VERSION "canboat-NMEA2000-curated"

NS_ :

BS_:

BU_: Vector__XXX
BO_ 2582577152 PGN_126720_0x1ef00ManufacturerProprietaryFastPacketAddressed: 223 Vector__XXX
 SG_ Industry_Code : 13|3@1+ (1.0,0) [0|7] "" Vector__XXX
 SG_ Data : 16|1768@1+ (1.0,0) [0|16635364987126134419907490844611231857889171561340108669757218330385068731224834608417815051548234195819468783937845710359164977421616154908223175941492902641772198991471137845920843845811776377869137773379678289214194183661112800944378464511794046030758602257005203964634516091405743061582849883160885255175229773660916874237270946647032424101972117051870087763059119895517977437771543686400460392041962138103436564399831189767740372774280024852942859855049773927338342604171805121253257539126169331943684033945189625789470637817855] "" Vector__XXX

BO_ 2582577152 PGN_126720_airmarAddressableMultiFrame: 8 Vector__XXX
 SG_ Industry_Code : 13|3@1+ (1.0,0) [0|7] "" Vector__XXX
 SG_ Proprietary_ID : 16|8@1+ (1.0,0) [0|255] "" Vector__XXX

BO_ 2582577152 PGN_126720_airmarAttitudeOffset: 9 Vector__XXX
 SG_ Industry_Code : 13|3@1+ (1.0,0) [0|7] "" Vector__XXX
 SG_ Proprietary_ID : 16|8@1+ (1.0,0) [0|255] "" Vector__XXX
 SG_ Azimuth_offset : 24|16@1- (0.0001,0) [-3.2768|3.2767] "" Vector__XXX
 SG_ Pitch_offset : 40|16@1- (0.0001,0) [-3.2768|3.2767] "" Vector__XXX
 SG_ Roll_offset : 56|16@1- (0.0001,0) [-3.2768|3.2767] "" Vector__XXX

BO_ 2582577152 PGN_126720_airmarCalibrateCompass: 24 Vector__XXX
 SG_ Industry_Code : 13|3@1+ (1.0,0) [0|7] "" Vector__XXX
 SG_ Proprietary_ID : 16|8@1+ (1.0,0) [0|255] "" Vector__XXX
 SG_ Calibrate_Function : 24|8@1+ (1.0,0) [0|255] "" Vector__XXX
 SG_ Calibration_Status : 32|8@1+ (1.0,0) [0|255] "" Vector__XXX
 SG_ Verify_Score : 40|8@1+ (1.0,0) [0|255] "" Vector__XXX
 SG_ X_axis_gain_value : 48|16@1- (0.01,0) [-327.68|327.67] "" Vector__XXX
 SG_ Y_axis_gain_value : 64|16@1- (0.01,0) [-327.68|327.67] "" Vector__XXX
 SG_ Z_axis_gain_value : 80|16@1- (0.01,0) [-327.68|327.67] "" Vector__XXX
 SG_ X_axis_linear_offset : 96|16@1- (0.01,0) [-327.68|327.67] "" Vector__XXX
 SG_ Y_axis_linear_offset : 112|16@1- (0.01,0) [-327.68|327.67] "" Vector__XXX
 SG_ Z_axis_linear_offset : 128|16@1- (0.01,0) [-327.68|327.67] "" Vector__XXX
 SG_ X_axis_angular_offset : 144|16@1- (0.1,0) [-3276.8|3276.7000000000003] "deg" Vector__XXX
 SG_ Pitch_and_Roll_damping : 160|16@1- (0.05,0) [-1638.4|1638.3500000000001] "" Vector__XXX
 SG_ Compass_Rate_gyro_damping : 176|16@1- (0.05,0) [-1638.4|1638.3500000000001] "" Vector__XXX

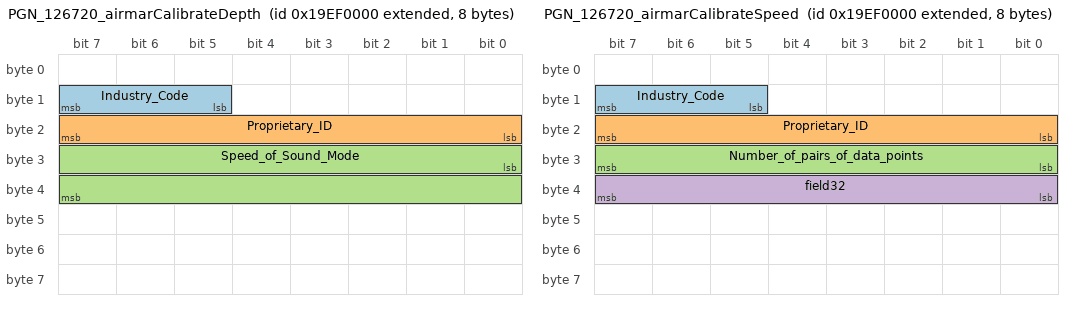
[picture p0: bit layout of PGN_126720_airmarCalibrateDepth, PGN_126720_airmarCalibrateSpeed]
BO_ 2582577152 PGN_126720_airmarCalibrateDepth: 8 Vector__XXX
 SG_ Industry_Code : 13|3@1+ (1.0,0) [0|7] "" Vector__XXX
 SG_ Proprietary_ID : 16|8@1+ (1.0,0) [0|255] "" Vector__XXX
 SG_ Speed_of_Sound_Mode : 24|16@1+ (0.1,0) [0.0|6553.5] "" Vector__XXX

BO_ 2582577152 PGN_126720_airmarCalibrateSpeed: 8 Vector__XXX
 SG_ Industry_Code : 13|3@1+ (1.0,0) [0|7] "" Vector__XXX
 SG_ Proprietary_ID : 16|8@1+ (1.0,0) [0|255] "" Vector__XXX
 SG_ Number_of_pairs_of_data_points : 24|8@1+ (1.0,0) [0|255] "" Vector__XXX
 SG_ field32 : 32|8@1+ (1.0,0) [0|255] "" Vector__XXX

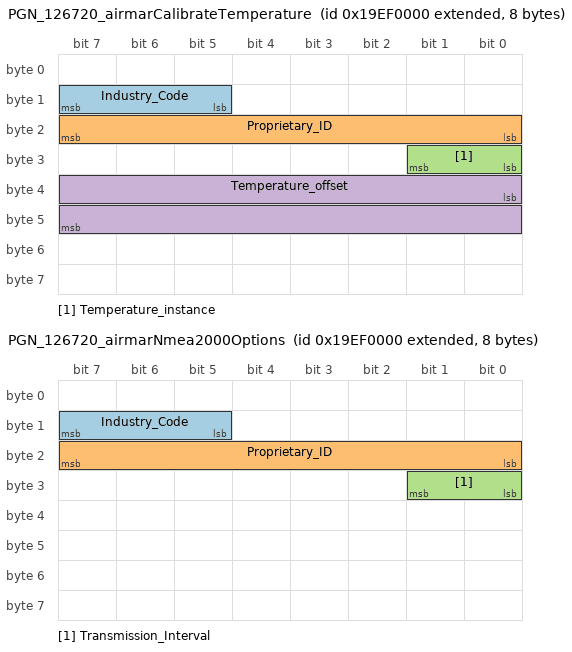
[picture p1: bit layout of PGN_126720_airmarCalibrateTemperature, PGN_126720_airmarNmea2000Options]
BO_ 2582577152 PGN_126720_airmarCalibrateTemperature: 8 Vector__XXX
 SG_ Industry_Code : 13|3@1+ (1.0,0) [0|7] "" Vector__XXX
 SG_ Proprietary_ID : 16|8@1+ (1.0,0) [0|255] "" Vector__XXX
 SG_ Temperature_instance : 24|2@1+ (1.0,0) [0|3] "" Vector__XXX
 SG_ Temperature_offset : 32|16@1- (0.001,0) [-9.999|9.999] "K" Vector__XXX

BO_ 2582577152 PGN_126720_airmarNmea2000Options: 8 Vector__XXX
 SG_ Industry_Code : 13|3@1+ (1.0,0) [0|7] "" Vector__XXX
 SG_ Proprietary_ID : 16|8@1+ (1.0,0) [0|255] "" Vector__XXX
 SG_ Transmission_Interval : 24|2@1+ (1.0,0) [0|3] "" Vector__XXX

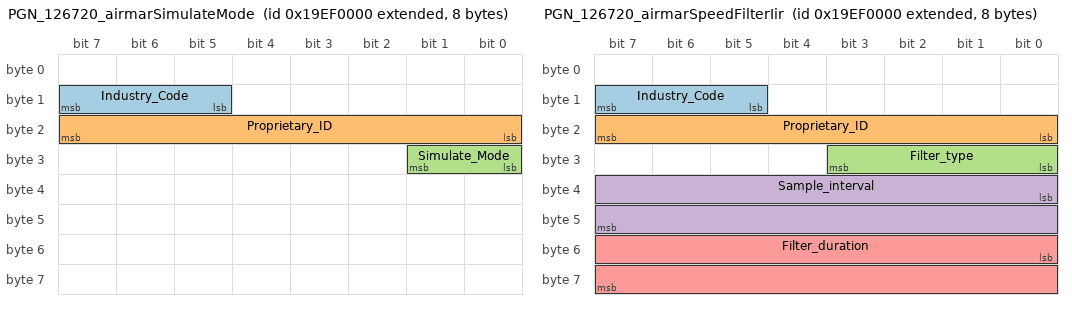
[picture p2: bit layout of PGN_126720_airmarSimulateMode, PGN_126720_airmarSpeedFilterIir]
BO_ 2582577152 PGN_126720_airmarSimulateMode: 8 Vector__XXX
 SG_ Industry_Code : 13|3@1+ (1.0,0) [0|7] "" Vector__XXX
 SG_ Proprietary_ID : 16|8@1+ (1.0,0) [0|255] "" Vector__XXX
 SG_ Simulate_Mode : 24|2@1+ (1.0,0) [0|3] "" Vector__XXX

BO_ 2582577152 PGN_126720_airmarSpeedFilterIir: 8 Vector__XXX
 SG_ Industry_Code : 13|3@1+ (1.0,0) [0|7] "" Vector__XXX
 SG_ Proprietary_ID : 16|8@1+ (1.0,0) [0|255] "" Vector__XXX
 SG_ Filter_type : 24|4@1+ (1.0,0) [0|15] "" Vector__XXX
 SG_ Sample_interval : 32|16@1+ (0.01,0) [0.0|655.35] "" Vector__XXX
 SG_ Filter_duration : 48|16@1+ (0.01,0) [0.0|655.35] "" Vector__XXX

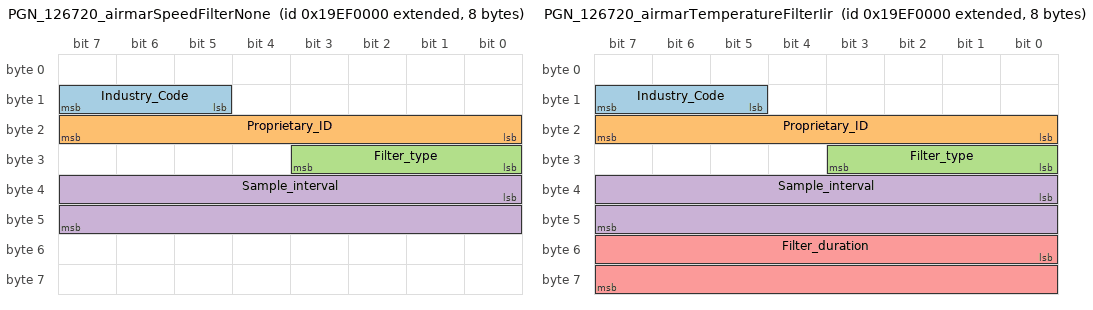
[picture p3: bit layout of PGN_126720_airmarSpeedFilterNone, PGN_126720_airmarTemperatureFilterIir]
BO_ 2582577152 PGN_126720_airmarSpeedFilterNone: 8 Vector__XXX
 SG_ Industry_Code : 13|3@1+ (1.0,0) [0|7] "" Vector__XXX
 SG_ Proprietary_ID : 16|8@1+ (1.0,0) [0|255] "" Vector__XXX
 SG_ Filter_type : 24|4@1+ (1.0,0) [0|15] "" Vector__XXX
 SG_ Sample_interval : 32|16@1+ (0.01,0) [0.0|655.35] "" Vector__XXX

BO_ 2582577152 PGN_126720_airmarTemperatureFilterIir: 8 Vector__XXX
 SG_ Industry_Code : 13|3@1+ (1.0,0) [0|7] "" Vector__XXX
 SG_ Proprietary_ID : 16|8@1+ (1.0,0) [0|255] "" Vector__XXX
 SG_ Filter_type : 24|4@1+ (1.0,0) [0|15] "" Vector__XXX
 SG_ Sample_interval : 32|16@1+ (0.01,0) [0.0|655.35] "" Vector__XXX
 SG_ Filter_duration : 48|16@1+ (0.01,0) [0.0|655.35] "" Vector__XXX

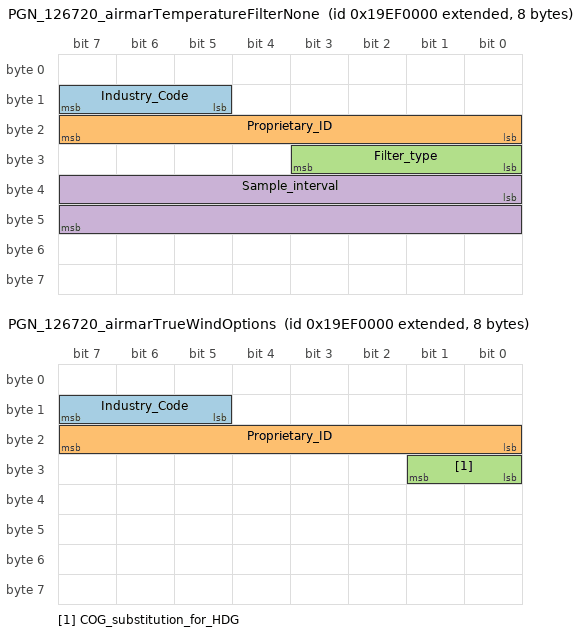
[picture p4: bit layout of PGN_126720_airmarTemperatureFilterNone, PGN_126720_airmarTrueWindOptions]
BO_ 2582577152 PGN_126720_airmarTemperatureFilterNone: 8 Vector__XXX
 SG_ Industry_Code : 13|3@1+ (1.0,0) [0|7] "" Vector__XXX
 SG_ Proprietary_ID : 16|8@1+ (1.0,0) [0|255] "" Vector__XXX
 SG_ Filter_type : 24|4@1+ (1.0,0) [0|15] "" Vector__XXX
 SG_ Sample_interval : 32|16@1+ (0.01,0) [0.0|655.35] "" Vector__XXX

BO_ 2582577152 PGN_126720_airmarTrueWindOptions: 8 Vector__XXX
 SG_ Industry_Code : 13|3@1+ (1.0,0) [0|7] "" Vector__XXX
 SG_ Proprietary_ID : 16|8@1+ (1.0,0) [0|255] "" Vector__XXX
 SG_ COG_substitution_for_HDG : 24|2@1+ (1.0,0) [0|3] "" Vector__XXX

BO_ 2582577152 PGN_126720_carlingDcConfigurationCommand: 13 Vector__XXX
 SG_ Industry_Code : 13|3@1+ (1.0,0) [0|7] "" Vector__XXX
 SG_ Message_Type : 16|8@1+ (1.0,0) [0|255] "" Vector__XXX
 SG_ Breaker_Mapping_1 : 24|8@1+ (1.0,0) [0|255] "" Vector__XXX
 SG_ Breaker_Mapping_2 : 32|8@1+ (1.0,0) [0|255] "" Vector__XXX
 SG_ Breaker_Mapping_3 : 45|3@1+ (1.0,0) [0|7] "" Vector__XXX
 SG_ Inrush_Delay : 48|4@1+ (1.0,0) [0|15] "" Vector__XXX
 SG_ Trip_Delay : 52|4@1+ (1.0,0) [0|15] "" Vector__XXX
 SG_ Configuration_Flags : 56|8@1+ (1.0,0) [0|255] "" Vector__XXX
 SG_ Current_Rating : 64|8@1+ (1.0,0) [0|255] "" Vector__XXX
 SG_ Factory_Max_Rating : 72|8@1+ (1.0,0) [0|255] "" Vector__XXX
 SG_ Schedule_B_Load_Shed_Priority : 80|4@1+ (1.0,0) [0|15] "" Vector__XXX
 SG_ Schedule_A_Load_Shed_Priority : 84|4@1+ (1.0,0) [0|15] "" Vector__XXX
 SG_ Dim_Value : 88|8@1+ (1.0,0) [0|255] "" Vector__XXX
 SG_ Breaker_Group : 96|4@1+ (1.0,0) [0|15] "" Vector__XXX
 SG_ Flash_Map_Index : 100|4@1+ (1.0,0) [0|15] "" Vector__XXX

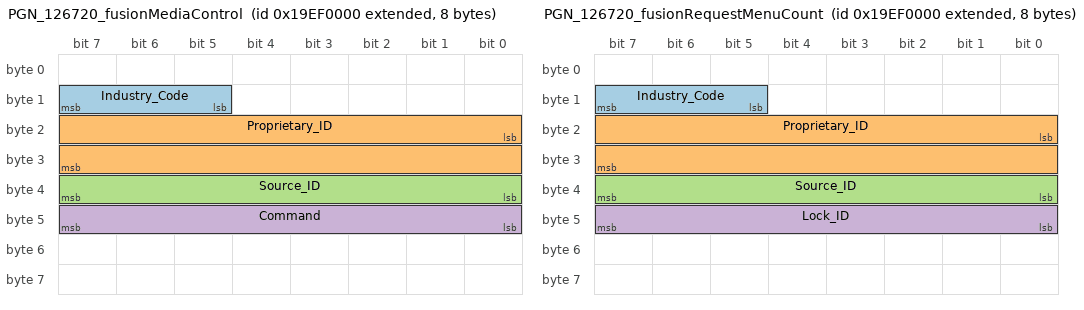
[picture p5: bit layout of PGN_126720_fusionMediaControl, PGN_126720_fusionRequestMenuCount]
BO_ 2582577152 PGN_126720_fusionMediaControl: 8 Vector__XXX
 SG_ Industry_Code : 13|3@1+ (1.0,0) [0|7] "" Vector__XXX
 SG_ Proprietary_ID : 16|16@1+ (1.0,0) [0|65535] "" Vector__XXX
 SG_ Source_ID : 32|8@1+ (1.0,0) [0|255] "" Vector__XXX
 SG_ Command : 40|8@1+ (1.0,0) [0|255] "" Vector__XXX

BO_ 2582577152 PGN_126720_fusionMenuActionCommand: 11 Vector__XXX
 SG_ Industry_Code : 13|3@1+ (1.0,0) [0|7] "" Vector__XXX
 SG_ Proprietary_ID : 16|16@1+ (1.0,0) [0|65535] "" Vector__XXX
 SG_ Source_ID : 32|8@1+ (1.0,0) [0|255] "" Vector__XXX
 SG_ Item_Index : 40|32@1+ (1.0,0) [0|4294967295] "" Vector__XXX
 SG_ Action : 72|8@1+ (1.0,0) [0|255] "" Vector__XXX
 SG_ Lock_ID : 80|8@1+ (1.0,0) [0|255] "" Vector__XXX

BO_ 2582577152 PGN_126720_fusionRequestMenuCount: 8 Vector__XXX
 SG_ Industry_Code : 13|3@1+ (1.0,0) [0|7] "" Vector__XXX
 SG_ Proprietary_ID : 16|16@1+ (1.0,0) [0|65535] "" Vector__XXX
 SG_ Source_ID : 32|8@1+ (1.0,0) [0|255] "" Vector__XXX
 SG_ Lock_ID : 40|8@1+ (1.0,0) [0|255] "" Vector__XXX

BO_ 2582577152 PGN_126720_fusionRequestMenuItems: 14 Vector__XXX
 SG_ Industry_Code : 13|3@1+ (1.0,0) [0|7] "" Vector__XXX
 SG_ Proprietary_ID : 16|16@1+ (1.0,0) [0|65535] "" Vector__XXX
 SG_ Source_ID : 32|8@1+ (1.0,0) [0|255] "" Vector__XXX
 SG_ Start_Index : 40|32@1+ (1.0,0) [0|4294967295] "" Vector__XXX
 SG_ Count : 72|32@1+ (1.0,0) [0|4294967295] "" Vector__XXX
 SG_ Lock_ID : 104|8@1+ (1.0,0) [0|255] "" Vector__XXX

BO_ 2582577152 PGN_126720_fusionRequestStatus: 8 Vector__XXX
 SG_ Industry_Code : 13|3@1+ (1.0,0) [0|7] "" Vector__XXX
 SG_ Proprietary_ID : 16|16@1+ (1.0,0) [0|65535] "" Vector__XXX

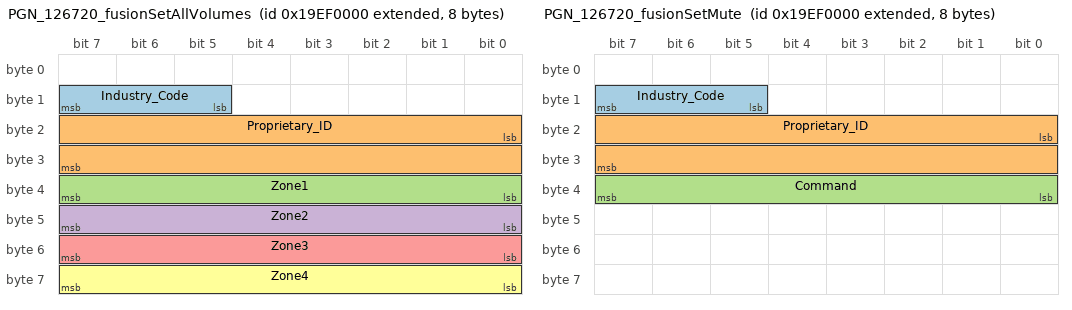
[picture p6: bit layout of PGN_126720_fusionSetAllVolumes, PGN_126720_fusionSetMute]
BO_ 2582577152 PGN_126720_fusionSetAllVolumes: 8 Vector__XXX
 SG_ Industry_Code : 13|3@1+ (1.0,0) [0|7] "" Vector__XXX
 SG_ Proprietary_ID : 16|16@1+ (1.0,0) [0|65535] "" Vector__XXX
 SG_ Zone1 : 32|8@1+ (1.0,0) [0|255] "" Vector__XXX
 SG_ Zone2 : 40|8@1+ (1.0,0) [0|255] "" Vector__XXX
 SG_ Zone3 : 48|8@1+ (1.0,0) [0|255] "" Vector__XXX
 SG_ Zone4 : 56|8@1+ (1.0,0) [0|255] "" Vector__XXX

BO_ 2582577152 PGN_126720_fusionSetMute: 8 Vector__XXX
 SG_ Industry_Code : 13|3@1+ (1.0,0) [0|7] "" Vector__XXX
 SG_ Proprietary_ID : 16|16@1+ (1.0,0) [0|65535] "" Vector__XXX
 SG_ Command : 32|8@1+ (1.0,0) [0|255] "" Vector__XXX

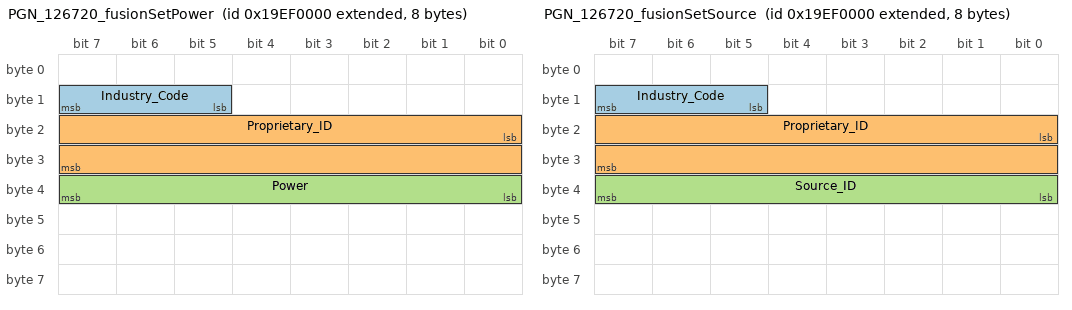
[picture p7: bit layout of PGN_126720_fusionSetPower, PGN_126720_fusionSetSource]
BO_ 2582577152 PGN_126720_fusionSetPower: 8 Vector__XXX
 SG_ Industry_Code : 13|3@1+ (1.0,0) [0|7] "" Vector__XXX
 SG_ Proprietary_ID : 16|16@1+ (1.0,0) [0|65535] "" Vector__XXX
 SG_ Power : 32|8@1+ (1.0,0) [0|255] "" Vector__XXX

BO_ 2582577152 PGN_126720_fusionSetSetting: 12 Vector__XXX
 SG_ Industry_Code : 13|3@1+ (1.0,0) [0|7] "" Vector__XXX
 SG_ Proprietary_ID : 16|16@1+ (1.0,0) [0|65535] "" Vector__XXX
 SG_ ID : 32|32@1+ (1.0,0) [0|4294967295] "" Vector__XXX
 SG_ Value : 64|32@1+ (1.0,0) [0|4294967295] "" Vector__XXX

BO_ 2582577152 PGN_126720_fusionSetSource: 8 Vector__XXX
 SG_ Industry_Code : 13|3@1+ (1.0,0) [0|7] "" Vector__XXX
 SG_ Proprietary_ID : 16|16@1+ (1.0,0) [0|65535] "" Vector__XXX
 SG_ Source_ID : 32|8@1+ (1.0,0) [0|255] "" Vector__XXX

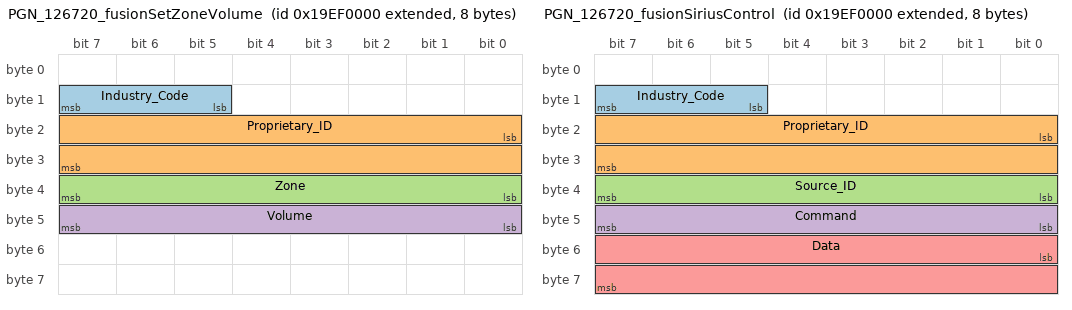
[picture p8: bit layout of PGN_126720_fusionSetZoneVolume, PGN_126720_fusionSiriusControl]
BO_ 2582577152 PGN_126720_fusionSetZoneVolume: 8 Vector__XXX
 SG_ Industry_Code : 13|3@1+ (1.0,0) [0|7] "" Vector__XXX
 SG_ Proprietary_ID : 16|16@1+ (1.0,0) [0|65535] "" Vector__XXX
 SG_ Zone : 32|8@1+ (1.0,0) [0|255] "" Vector__XXX
 SG_ Volume : 40|8@1+ (1.0,0) [0|255] "" Vector__XXX

BO_ 2582577152 PGN_126720_fusionSiriusControl: 8 Vector__XXX
 SG_ Industry_Code : 13|3@1+ (1.0,0) [0|7] "" Vector__XXX
 SG_ Proprietary_ID : 16|16@1+ (1.0,0) [0|65535] "" Vector__XXX
 SG_ Source_ID : 32|8@1+ (1.0,0) [0|255] "" Vector__XXX
 SG_ Command : 40|8@1+ (1.0,0) [0|255] "" Vector__XXX
 SG_ Data : 48|16@1+ (1.0,0) [0|65535] "" Vector__XXX

BO_ 2582577152 PGN_126720_garminAhrsAttCogSourceValidFlag: 12 Vector__XXX
 SG_ Industry_Code : 13|3@1+ (1.0,0) [0|7] "" Vector__XXX
 SG_ Sub_protocol_ID : 16|16@1+ (1.0,0) [0|65535] "" Vector__XXX
 SG_ Wrapper_Byte_1 : 32|8@1+ (1.0,0) [0|255] "" Vector__XXX
 SG_ Wrapper_Byte_2 : 40|8@1+ (1.0,0) [0|255] "" Vector__XXX
 SG_ ATT_Message_ID : 48|16@1+ (1.0,0) [0|65535] "" Vector__XXX
 SG_ COG_Source_Flags : 64|32@1+ (1.0,0) [0|4294967295] "" Vector__XXX

BO_ 2582577152 PGN_126720_garminAhrsAttDeviceFlags: 12 Vector__XXX
 SG_ Industry_Code : 13|3@1+ (1.0,0) [0|7] "" Vector__XXX
 SG_ Sub_protocol_ID : 16|16@1+ (1.0,0) [0|65535] "" Vector__XXX
 SG_ Wrapper_Byte_1 : 32|8@1+ (1.0,0) [0|255] "" Vector__XXX
 SG_ Wrapper_Byte_2 : 40|8@1+ (1.0,0) [0|255] "" Vector__XXX
 SG_ ATT_Message_ID : 48|16@1+ (1.0,0) [0|65535] "" Vector__XXX
 SG_ Device_Flags : 64|32@1+ (1.0,0) [0|4294967295] "" Vector__XXX

BO_ 2582577152 PGN_126720_garminAhrsAttNonDefaultCalibrationMatrixPresent: 9 Vector__XXX
 SG_ Industry_Code : 13|3@1+ (1.0,0) [0|7] "" Vector__XXX
 SG_ Sub_protocol_ID : 16|16@1+ (1.0,0) [0|65535] "" Vector__XXX
 SG_ Wrapper_Byte_1 : 32|8@1+ (1.0,0) [0|255] "" Vector__XXX
 SG_ Wrapper_Byte_2 : 40|8@1+ (1.0,0) [0|255] "" Vector__XXX
 SG_ ATT_Message_ID : 48|16@1+ (1.0,0) [0|65535] "" Vector__XXX
 SG_ Calibration_Matrix_Present : 64|8@1+ (1.0,0) [0|255] "" Vector__XXX

BO_ 2582577152 PGN_126720_garminAhrsAttSetNorthState: 9 Vector__XXX
 SG_ Industry_Code : 13|3@1+ (1.0,0) [0|7] "" Vector__XXX
 SG_ Sub_protocol_ID : 16|16@1+ (1.0,0) [0|65535] "" Vector__XXX
 SG_ Wrapper_Byte_1 : 32|8@1+ (1.0,0) [0|255] "" Vector__XXX
 SG_ Wrapper_Byte_2 : 40|8@1+ (1.0,0) [0|255] "" Vector__XXX
 SG_ ATT_Message_ID : 48|16@1+ (1.0,0) [0|65535] "" Vector__XXX
 SG_ Set_North_State : 64|8@1+ (1.0,0) [0|255] "" Vector__XXX

BO_ 2649686016 PGN_126720_garminAutopilotEngineRpmA: 11 Vector__XXX
 SG_ Manufacturer_Code : 0|11@1+ (1.0,0) [0|2047] "" Vector__XXX
 SG_ Industry_Code : 13|3@1+ (1.0,0) [0|7] "" Vector__XXX
 SG_ Sub_protocol_ID : 16|16@1+ (1.0,0) [0|65535] "" Vector__XXX
 SG_ Wrapper_Byte_1 : 32|8@1+ (1.0,0) [0|255] "" Vector__XXX
 SG_ Wrapper_Byte_2 : 40|8@1+ (1.0,0) [0|255] "" Vector__XXX
 SG_ Field_Group : 48|8@1+ (1.0,0) [0|255] "" Vector__XXX
 SG_ Field : 56|8@1+ (1.0,0) [0|255] "" Vector__XXX
 SG_ Engine_Speed : 72|16@1+ (1.0,0) [0|65535] "rpm" Vector__XXX

BO_ 2649686016 PGN_126720_garminAutopilotEngineRpmB: 11 Vector__XXX
 SG_ Manufacturer_Code : 0|11@1+ (1.0,0) [0|2047] "" Vector__XXX
 SG_ Industry_Code : 13|3@1+ (1.0,0) [0|7] "" Vector__XXX
 SG_ Sub_protocol_ID : 16|16@1+ (1.0,0) [0|65535] "" Vector__XXX
 SG_ Wrapper_Byte_1 : 32|8@1+ (1.0,0) [0|255] "" Vector__XXX
 SG_ Wrapper_Byte_2 : 40|8@1+ (1.0,0) [0|255] "" Vector__XXX
 SG_ Field_Group : 48|8@1+ (1.0,0) [0|255] "" Vector__XXX
 SG_ Field : 56|8@1+ (1.0,0) [0|255] "" Vector__XXX
 SG_ Engine_Speed : 72|16@1+ (1.0,0) [0|65535] "rpm" Vector__XXX

BO_ 2649686016 PGN_126720_garminAutopilotHeadingToSteer: 13 Vector__XXX
 SG_ Manufacturer_Code : 0|11@1+ (1.0,0) [0|2047] "" Vector__XXX
 SG_ Industry_Code : 13|3@1+ (1.0,0) [0|7] "" Vector__XXX
 SG_ Sub_protocol_ID : 16|16@1+ (1.0,0) [0|65535] "" Vector__XXX
 SG_ Wrapper_Byte_1 : 32|8@1+ (1.0,0) [0|255] "" Vector__XXX
 SG_ Wrapper_Byte_2 : 40|8@1+ (1.0,0) [0|255] "" Vector__XXX
 SG_ Field_Group : 48|8@1+ (1.0,0) [0|255] "" Vector__XXX
 SG_ Field : 56|8@1+ (1.0,0) [0|255] "" Vector__XXX
 SG_ Heading_to_Steer : 72|32@1- (1.0,0) [-2147483648|2147483647] "rad" Vector__XXX

BO_ 2649686016 PGN_126720_garminAutopilotHeartbeat: 12 Vector__XXX
 SG_ Manufacturer_Code : 0|11@1+ (1.0,0) [0|2047] "" Vector__XXX
 SG_ Industry_Code : 13|3@1+ (1.0,0) [0|7] "" Vector__XXX
 SG_ Sub_protocol_ID : 16|16@1+ (1.0,0) [0|65535] "" Vector__XXX
 SG_ Wrapper_Byte_1 : 32|8@1+ (1.0,0) [0|255] "" Vector__XXX
 SG_ Wrapper_Byte_2 : 40|8@1+ (1.0,0) [0|255] "" Vector__XXX
 SG_ Field_Group : 48|8@1+ (1.0,0) [0|255] "" Vector__XXX
 SG_ Field : 56|8@1+ (1.0,0) [0|255] "" Vector__XXX
 SG_ Heartbeat_Data : 64|32@1+ (1.0,0) [0|4294967295] "" Vector__XXX

BO_ 2649686016 PGN_126720_garminAutopilotManeuver: 10 Vector__XXX
 SG_ Manufacturer_Code : 0|11@1+ (1.0,0) [0|2047] "" Vector__XXX
 SG_ Industry_Code : 13|3@1+ (1.0,0) [0|7] "" Vector__XXX
 SG_ Sub_protocol_ID : 16|16@1+ (1.0,0) [0|65535] "" Vector__XXX
 SG_ Wrapper_Byte_1 : 32|8@1+ (1.0,0) [0|255] "" Vector__XXX
 SG_ Wrapper_Byte_2 : 40|8@1+ (1.0,0) [0|255] "" Vector__XXX
 SG_ Field_Group : 48|8@1+ (1.0,0) [0|255] "" Vector__XXX
 SG_ Maneuver_Code : 56|8@1+ (1.0,0) [0|255] "" Vector__XXX
 SG_ Spare : 64|8@1+ (1.0,0) [0|255] "" Vector__XXX
 SG_ Value : 72|8@1+ (1.0,0) [0|255] "" Vector__XXX

BO_ 2649686016 PGN_126720_garminAutopilotModeState: 11 Vector__XXX
 SG_ Manufacturer_Code : 0|11@1+ (1.0,0) [0|2047] "" Vector__XXX
 SG_ Industry_Code : 13|3@1+ (1.0,0) [0|7] "" Vector__XXX
 SG_ Sub_protocol_ID : 16|16@1+ (1.0,0) [0|65535] "" Vector__XXX
 SG_ Wrapper_Byte_1 : 32|8@1+ (1.0,0) [0|255] "" Vector__XXX
 SG_ Wrapper_Byte_2 : 40|8@1+ (1.0,0) [0|255] "" Vector__XXX
 SG_ Field_Group : 48|8@1+ (1.0,0) [0|255] "" Vector__XXX
 SG_ Field : 56|8@1+ (1.0,0) [0|255] "" Vector__XXX
 SG_ Spare : 64|8@1+ (1.0,0) [0|255] "" Vector__XXX
 SG_ Mode_State : 72|8@1+ (1.0,0) [0|255] "" Vector__XXX
 SG_ Spare_1 : 80|8@1+ (1.0,0) [0|255] "" Vector__XXX

BO_ 2649686016 PGN_126720_garminAutopilotRateOfTurn: 13 Vector__XXX
 SG_ Manufacturer_Code : 0|11@1+ (1.0,0) [0|2047] "" Vector__XXX
 SG_ Industry_Code : 13|3@1+ (1.0,0) [0|7] "" Vector__XXX
 SG_ Sub_protocol_ID : 16|16@1+ (1.0,0) [0|65535] "" Vector__XXX
 SG_ Wrapper_Byte_1 : 32|8@1+ (1.0,0) [0|255] "" Vector__XXX
 SG_ Wrapper_Byte_2 : 40|8@1+ (1.0,0) [0|255] "" Vector__XXX
 SG_ Field_Group : 48|8@1+ (1.0,0) [0|255] "" Vector__XXX
 SG_ Field : 56|8@1+ (1.0,0) [0|255] "" Vector__XXX
 SG_ Rate_of_Turn : 72|32@1- (1.0,0) [-3.40282346638529e+38|3.40282346638529e+38] "rad/s" Vector__XXX

BO_ 2649686016 PGN_126720_garminAutopilotRateOfTurnOrder: 13 Vector__XXX
 SG_ Manufacturer_Code : 0|11@1+ (1.0,0) [0|2047] "" Vector__XXX
 SG_ Industry_Code : 13|3@1+ (1.0,0) [0|7] "" Vector__XXX
 SG_ Sub_protocol_ID : 16|16@1+ (1.0,0) [0|65535] "" Vector__XXX
 SG_ Wrapper_Byte_1 : 32|8@1+ (1.0,0) [0|255] "" Vector__XXX
 SG_ Wrapper_Byte_2 : 40|8@1+ (1.0,0) [0|255] "" Vector__XXX
 SG_ Field_Group : 48|8@1+ (1.0,0) [0|255] "" Vector__XXX
 SG_ Field : 56|8@1+ (1.0,0) [0|255] "" Vector__XXX
 SG_ Rate_of_Turn_Order : 72|32@1- (1.0,0) [-3.40282346638529e+38|3.40282346638529e+38] "rad/s" Vector__XXX

BO_ 2649686016 PGN_126720_garminAutopilotResponseSetting: 10 Vector__XXX
 SG_ Manufacturer_Code : 0|11@1+ (1.0,0) [0|2047] "" Vector__XXX
 SG_ Industry_Code : 13|3@1+ (1.0,0) [0|7] "" Vector__XXX
 SG_ Sub_protocol_ID : 16|16@1+ (1.0,0) [0|65535] "" Vector__XXX
 SG_ Wrapper_Byte_1 : 32|8@1+ (1.0,0) [0|255] "" Vector__XXX
 SG_ Wrapper_Byte_2 : 40|8@1+ (1.0,0) [0|255] "" Vector__XXX
 SG_ Field_Group : 48|8@1+ (1.0,0) [0|255] "" Vector__XXX
 SG_ Field : 56|8@1+ (1.0,0) [0|255] "" Vector__XXX
 SG_ Response_Setting : 72|8@1- (1.0,0) [-128|127] "" Vector__XXX

BO_ 2649686016 PGN_126720_garminAutopilotSpeed: 13 Vector__XXX
 SG_ Manufacturer_Code : 0|11@1+ (1.0,0) [0|2047] "" Vector__XXX
 SG_ Industry_Code : 13|3@1+ (1.0,0) [0|7] "" Vector__XXX
 SG_ Sub_protocol_ID : 16|16@1+ (1.0,0) [0|65535] "" Vector__XXX
 SG_ Wrapper_Byte_1 : 32|8@1+ (1.0,0) [0|255] "" Vector__XXX
 SG_ Wrapper_Byte_2 : 40|8@1+ (1.0,0) [0|255] "" Vector__XXX
 SG_ Field_Group : 48|8@1+ (1.0,0) [0|255] "" Vector__XXX
 SG_ Field : 56|8@1+ (1.0,0) [0|255] "" Vector__XXX
 SG_ Speed : 72|32@1- (1.0,0) [-3.40282346638529e+38|3.40282346638529e+38] "m/s" Vector__XXX

BO_ 2649686016 PGN_126720_garminAutopilotSystemVoltage: 11 Vector__XXX
 SG_ Manufacturer_Code : 0|11@1+ (1.0,0) [0|2047] "" Vector__XXX
 SG_ Industry_Code : 13|3@1+ (1.0,0) [0|7] "" Vector__XXX
 SG_ Sub_protocol_ID : 16|16@1+ (1.0,0) [0|65535] "" Vector__XXX
 SG_ Wrapper_Byte_1 : 32|8@1+ (1.0,0) [0|255] "" Vector__XXX
 SG_ Wrapper_Byte_2 : 40|8@1+ (1.0,0) [0|255] "" Vector__XXX
 SG_ Field_Group : 48|8@1+ (1.0,0) [0|255] "" Vector__XXX
 SG_ Field : 56|8@1+ (1.0,0) [0|255] "" Vector__XXX
 SG_ System_Voltage : 72|16@1+ (0.01,0) [0.0|655.35] "" Vector__XXX

BO_ 2649686016 PGN_126720_garminAutopilotTurnAngleMeasured: 11 Vector__XXX
 SG_ Manufacturer_Code : 0|11@1+ (1.0,0) [0|2047] "" Vector__XXX
 SG_ Industry_Code : 13|3@1+ (1.0,0) [0|7] "" Vector__XXX
 SG_ Sub_protocol_ID : 16|16@1+ (1.0,0) [0|65535] "" Vector__XXX
 SG_ Wrapper_Byte_1 : 32|8@1+ (1.0,0) [0|255] "" Vector__XXX
 SG_ Wrapper_Byte_2 : 40|8@1+ (1.0,0) [0|255] "" Vector__XXX
 SG_ Field_Group : 48|8@1+ (1.0,0) [0|255] "" Vector__XXX
 SG_ Field : 56|8@1+ (1.0,0) [0|255] "" Vector__XXX
 SG_ Turn_Angle_Measured : 72|16@1+ (9.587379924285257e-05,0) [0.0|6.2830894333803435] "rad" Vector__XXX

BO_ 2649686016 PGN_126720_garminAutopilotTurnAngleOrder: 11 Vector__XXX
 SG_ Manufacturer_Code : 0|11@1+ (1.0,0) [0|2047] "" Vector__XXX
 SG_ Industry_Code : 13|3@1+ (1.0,0) [0|7] "" Vector__XXX
 SG_ Sub_protocol_ID : 16|16@1+ (1.0,0) [0|65535] "" Vector__XXX
 SG_ Wrapper_Byte_1 : 32|8@1+ (1.0,0) [0|255] "" Vector__XXX
 SG_ Wrapper_Byte_2 : 40|8@1+ (1.0,0) [0|255] "" Vector__XXX
 SG_ Field_Group : 48|8@1+ (1.0,0) [0|255] "" Vector__XXX
 SG_ Field : 56|8@1+ (1.0,0) [0|255] "" Vector__XXX
 SG_ Turn_Angle_Order : 72|16@1+ (9.587379924285257e-05,0) [0.0|6.2830894333803435] "rad" Vector__XXX

BO_ 2582577152 PGN_126720_garminColorMode: 11 Vector__XXX
 SG_ Industry_Code : 13|3@1+ (1.0,0) [0|7] "" Vector__XXX
 SG_ Unknown_ID_1 : 16|8@1+ (1.0,0) [0|255] "" Vector__XXX
 SG_ Unknown_ID_2 : 24|8@1+ (1.0,0) [0|255] "" Vector__XXX
 SG_ Unknown_ID_3 : 32|8@1+ (1.0,0) [0|255] "" Vector__XXX
 SG_ Unknown_ID_4 : 40|8@1+ (1.0,0) [0|255] "" Vector__XXX
 SG_ Spare : 48|16@1+ (1.0,0) [0|65535] "" Vector__XXX
 SG_ Mode : 64|8@1+ (1.0,0) [0|255] "" Vector__XXX
 SG_ Spare_1 : 72|8@1+ (1.0,0) [0|255] "" Vector__XXX
 SG_ Color : 80|8@1+ (1.0,0) [0|255] "" Vector__XXX

BO_ 2582577152 PGN_126720_garminDayMode: 11 Vector__XXX
 SG_ Industry_Code : 13|3@1+ (1.0,0) [0|7] "" Vector__XXX
 SG_ Unknown_ID_1 : 16|8@1+ (1.0,0) [0|255] "" Vector__XXX
 SG_ Unknown_ID_2 : 24|8@1+ (1.0,0) [0|255] "" Vector__XXX
 SG_ Unknown_ID_3 : 32|8@1+ (1.0,0) [0|255] "" Vector__XXX
 SG_ Unknown_ID_4 : 40|8@1+ (1.0,0) [0|255] "" Vector__XXX
 SG_ Spare : 48|16@1+ (1.0,0) [0|65535] "" Vector__XXX
 SG_ Mode : 64|8@1+ (1.0,0) [0|255] "" Vector__XXX
 SG_ Spare_1 : 72|8@1+ (1.0,0) [0|255] "" Vector__XXX
 SG_ Backlight : 80|8@1+ (1.0,0) [0|255] "" Vector__XXX

BO_ 2582577152 PGN_126720_garminNightMode: 11 Vector__XXX
 SG_ Industry_Code : 13|3@1+ (1.0,0) [0|7] "" Vector__XXX
 SG_ Unknown_ID_1 : 16|8@1+ (1.0,0) [0|255] "" Vector__XXX
 SG_ Unknown_ID_2 : 24|8@1+ (1.0,0) [0|255] "" Vector__XXX
 SG_ Unknown_ID_3 : 32|8@1+ (1.0,0) [0|255] "" Vector__XXX
 SG_ Unknown_ID_4 : 40|8@1+ (1.0,0) [0|255] "" Vector__XXX
 SG_ Spare : 48|16@1+ (1.0,0) [0|65535] "" Vector__XXX
 SG_ Mode : 64|8@1+ (1.0,0) [0|255] "" Vector__XXX
 SG_ Spare_1 : 72|8@1+ (1.0,0) [0|255] "" Vector__XXX
 SG_ Backlight : 80|8@1+ (1.0,0) [0|255] "" Vector__XXX

BO_ 2582577152 PGN_126720_lumishoreProprietary: 225 Vector__XXX
 SG_ Industry_Code : 13|3@1+ (1.0,0) [0|7] "" Vector__XXX
 SG_ Data : 16|1784@1+ (1.0,0) [0|1090215279796298345343057319992441691038624747443985361781209060500115864369550760897269927218265076257224706224150656474098235960303036328065314058501678867531182833105052489870268422279120576700031813116210596361941430020414688522690787050244934600671795757515093047026287646566366777283893649942831776083163858446641848270013788759459916945946844663111358071639842481472666169361795887031940572252862030682746818684507336852618633070135215708762463263460541984102045620907003420426453486084172633338261276848631947315738747720031010815] "" Vector__XXX

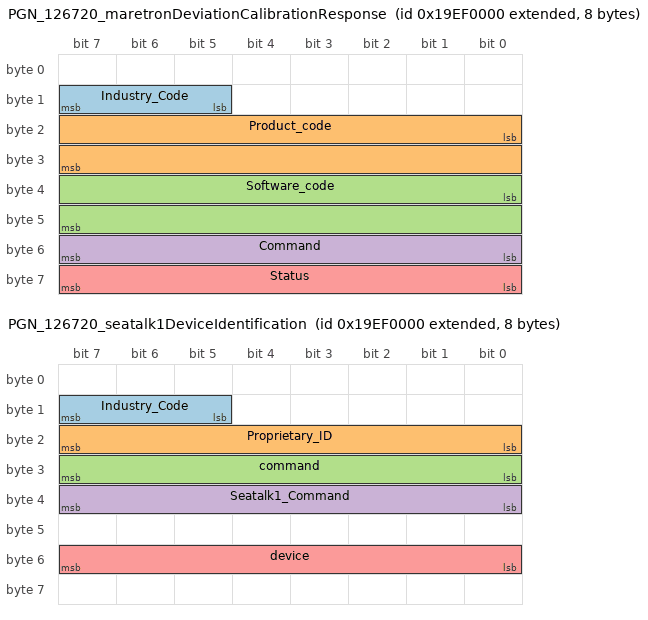
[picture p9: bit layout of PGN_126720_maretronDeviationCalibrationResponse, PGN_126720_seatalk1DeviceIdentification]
BO_ 2582577152 PGN_126720_maretronDeviationCalibrationResponse: 8 Vector__XXX
 SG_ Industry_Code : 13|3@1+ (1.0,0) [0|7] "" Vector__XXX
 SG_ Product_code : 16|16@1+ (1.0,0) [0|65535] "" Vector__XXX
 SG_ Software_code : 32|16@1+ (1.0,0) [0|65535] "" Vector__XXX
 SG_ Command : 48|8@1+ (1.0,0) [0|255] "" Vector__XXX
 SG_ Status : 56|8@1+ (1.0,0) [0|255] "" Vector__XXX

BO_ 2582577152 PGN_126720_maretronProprietaryConfiguration: 230 Vector__XXX
 SG_ Industry_Code : 13|3@1+ (1.0,0) [0|7] "" Vector__XXX
 SG_ Product_code : 16|16@1+ (1.0,0) [0|65535] "" Vector__XXX
 SG_ Software_code : 32|16@1+ (1.0,0) [0|65535] "" Vector__XXX
 SG_ Opcode : 48|8@1+ (1.0,0) [0|255] "" Vector__XXX
 SG_ Payload : 56|1784@1+ (1.0,0) [0|1090215279796298345343057319992441691038624747443985361781209060500115864369550760897269927218265076257224706224150656474098235960303036328065314058501678867531182833105052489870268422279120576700031813116210596361941430020414688522690787050244934600671795757515093047026287646566366777283893649942831776083163858446641848270013788759459916945946844663111358071639842481472666169361795887031940572252862030682746818684507336852618633070135215708762463263460541984102045620907003420426453486084172633338261276848631947315738747720031010815] "" Vector__XXX

BO_ 2582577152 PGN_126720_seatalk1DeviceIdentification: 8 Vector__XXX
 SG_ Industry_Code : 13|3@1+ (1.0,0) [0|7] "" Vector__XXX
 SG_ Proprietary_ID : 16|8@1+ (1.0,0) [0|255] "" Vector__XXX
 SG_ command : 24|8@1+ (1.0,0) [0|255] "" Vector__XXX
 SG_ Seatalk1_Command : 32|8@1+ (1.0,0) [0|255] "" Vector__XXX
 SG_ device : 48|8@1+ (1.0,0) [0|255] "" Vector__XXX

BO_ 2582577152 PGN_126720_seatalk1DisplayBrightness: 9 Vector__XXX
 SG_ Industry_Code : 13|3@1+ (1.0,0) [0|7] "" Vector__XXX
 SG_ Proprietary_ID : 16|8@1+ (1.0,0) [0|255] "" Vector__XXX
 SG_ command1 : 24|8@1+ (1.0,0) [0|255] "" Vector__XXX
 SG_ Group : 32|8@1+ (1.0,0) [0|255] "" Vector__XXX
 SG_ Shared : 40|8@1+ (1.0,0) [0|255] "" Vector__XXX
 SG_ Command : 48|8@1+ (1.0,0) [0|255] "" Vector__XXX
 SG_ Brightness : 56|8@1+ (1.0,0) [0|255] "%" Vector__XXX
 SG_ Unknown_2 : 64|8@1+ (1.0,0) [0|255] "" Vector__XXX

BO_ 2582577152 PGN_126720_seatalk1DisplayColor: 9 Vector__XXX
 SG_ Industry_Code : 13|3@1+ (1.0,0) [0|7] "" Vector__XXX
 SG_ Proprietary_ID : 16|8@1+ (1.0,0) [0|255] "" Vector__XXX
 SG_ command1 : 24|8@1+ (1.0,0) [0|255] "" Vector__XXX
 SG_ Group : 32|8@1+ (1.0,0) [0|255] "" Vector__XXX
 SG_ Unknown_1 : 40|8@1+ (1.0,0) [0|255] "" Vector__XXX
 SG_ Command : 48|8@1+ (1.0,0) [0|255] "" Vector__XXX
 SG_ Color : 56|8@1+ (1.0,0) [0|255] "" Vector__XXX
 SG_ Unknown_2 : 64|8@1+ (1.0,0) [0|255] "" Vector__XXX

BO_ 2582577152 PGN_126720_seatalk1Keystroke: 22 Vector__XXX
 SG_ Industry_Code : 13|3@1+ (1.0,0) [0|7] "" Vector__XXX
 SG_ Proprietary_ID : 16|8@1+ (1.0,0) [0|255] "" Vector__XXX
 SG_ command : 24|8@1+ (1.0,0) [0|255] "" Vector__XXX
 SG_ Seatalk1_Command : 32|8@1+ (1.0,0) [0|255] "" Vector__XXX
 SG_ device : 40|8@1+ (1.0,0) [0|255] "" Vector__XXX
 SG_ key : 48|8@1+ (1.0,0) [0|255] "" Vector__XXX
 SG_ keyInverted : 56|8@1+ (1.0,0) [0|255] "" Vector__XXX
 SG_ Unknown_data : 64|112@1+ (1.0,0) [0|5192296858534827628530496329220095] "" Vector__XXX

BO_ 2582577152 PGN_126720_seatalk1PilotHullType: 14 Vector__XXX
 SG_ Industry_Code : 13|3@1+ (1.0,0) [0|7] "" Vector__XXX
 SG_ Proprietary_ID : 16|8@1+ (1.0,0) [0|255] "" Vector__XXX
 SG_ command : 24|8@1+ (1.0,0) [0|255] "" Vector__XXX
 SG_ Unknown : 32|8@1+ (1.0,0) [0|255] "" Vector__XXX
 SG_ Hull_Type : 40|8@1+ (1.0,0) [0|255] "" Vector__XXX
 SG_ Unknown_2 : 48|64@1+ (1.0,0) [0|18446744073709551615] "" Vector__XXX

BO_ 2582577152 PGN_126720_seatalk1PilotMode: 21 Vector__XXX
 SG_ Industry_Code : 13|3@1+ (1.0,0) [0|7] "" Vector__XXX
 SG_ Proprietary_ID : 16|8@1+ (1.0,0) [0|255] "" Vector__XXX
 SG_ command : 24|8@1+ (1.0,0) [0|255] "" Vector__XXX
 SG_ Seatalk1_Command : 32|8@1+ (1.0,0) [0|255] "" Vector__XXX
 SG_ Unknown_1 : 40|24@1+ (1.0,0) [0|16777215] "" Vector__XXX
 SG_ Pilot_Mode : 64|8@1+ (1.0,0) [0|255] "" Vector__XXX
 SG_ Sub_Mode : 72|8@1+ (1.0,0) [0|255] "" Vector__XXX
 SG_ Pilot_Mode_Data : 80|8@1+ (1.0,0) [0|255] "" Vector__XXX
 SG_ Unknown_2 : 88|80@1+ (1.0,0) [0|1208925819614629174706175] "" Vector__XXX

BO_ 2582577152 PGN_126720_seatalkPilotAutoTurn: 9 Vector__XXX
 SG_ Industry_Code : 13|3@1+ (1.0,0) [0|7] "" Vector__XXX
 SG_ Proprietary_ID : 16|8@1+ (1.0,0) [0|255] "" Vector__XXX
 SG_ command : 24|8@1+ (1.0,0) [0|255] "" Vector__XXX
 SG_ Unknown : 32|8@1+ (1.0,0) [0|255] "" Vector__XXX
 SG_ Enabled : 40|8@1+ (1.0,0) [0|255] "" Vector__XXX
 SG_ Unknown_2 : 48|8@1+ (1.0,0) [0|255] "" Vector__XXX
 SG_ Unknown_3 : 56|16@1+ (1.0,0) [0|65535] "" Vector__XXX

BO_ 2582642688 PGN_126976: 223 Vector__XXX
 SG_ Data : 0|1784@1+ (1.0,0) [0|1090215279796298345343057319992441691038624747443985361781209060500115864369550760897269927218265076257224706224150656474098235960303036328065314058501678867531182833105052489870268422279120576700031813116210596361941430020414688522690787050244934600671795757515093047026287646566366777283893649942831776083163858446641848270013788759459916945946844663111358071639842481472666169361795887031940572252862030682746818684507336852618633070135215708762463263460541984102045620907003420426453486084172633338261276848631947315738747720031010815] "" Vector__XXX

BO_ 2582644480 PGN_126983_alert: 28 Vector__XXX
 SG_ Alert_Type : 0|4@1+ (1.0,0) [0|15] "" Vector__XXX
 SG_ Alert_Category : 4|4@1+ (1.0,0) [0|15] "" Vector__XXX
 SG_ Alert_System : 8|8@1+ (1.0,0) [0|255] "" Vector__XXX
 SG_ Alert_Sub_System : 16|8@1+ (1.0,0) [0|255] "" Vector__XXX
 SG_ Alert_ID : 24|16@1+ (1.0,0) [0|65535] "" Vector__XXX
 SG_ Data_Source_Network_ID_NAME : 40|64@1+ (1.0,0) [0|18446744073709551615] "" Vector__XXX
 SG_ Data_Source_Instance : 104|8@1+ (1.0,0) [0|255] "" Vector__XXX
 SG_ Data_Source_Index_Source : 112|8@1+ (1.0,0) [0|255] "" Vector__XXX
 SG_ Alert_Occurrence_Number : 120|8@1+ (1.0,0) [0|255] "" Vector__XXX
 SG_ Temporary_Silence_Status : 128|1@1+ (1.0,0) [0|1] "" Vector__XXX
 SG_ Acknowledge_Status : 129|1@1+ (1.0,0) [0|1] "" Vector__XXX
 SG_ Escalation_Status : 130|1@1+ (1.0,0) [0|1] "" Vector__XXX
 SG_ Temporary_Silence_Support : 131|1@1+ (1.0,0) [0|1] "" Vector__XXX
 SG_ Acknowledge_Support : 132|1@1+ (1.0,0) [0|1] "" Vector__XXX
 SG_ Escalation_Support : 133|1@1+ (1.0,0) [0|1] "" Vector__XXX
 SG_ Acknowledge_Source_Network_ID_NAME : 136|64@1+ (1.0,0) [0|18446744073709551615] "" Vector__XXX
 SG_ Trigger_Condition : 200|4@1+ (1.0,0) [0|15] "" Vector__XXX
 SG_ Threshold_Status : 204|4@1+ (1.0,0) [0|15] "" Vector__XXX
 SG_ Alert_Priority : 208|8@1+ (1.0,0) [0|255] "" Vector__XXX
 SG_ Alert_State : 216|8@1+ (1.0,0) [0|255] "" Vector__XXX

BO_ 2582644736 PGN_126984_alertResponse: 25 Vector__XXX
 SG_ Alert_Type : 0|4@1+ (1.0,0) [0|15] "" Vector__XXX
 SG_ Alert_Category : 4|4@1+ (1.0,0) [0|15] "" Vector__XXX
 SG_ Alert_System : 8|8@1+ (1.0,0) [0|255] "" Vector__XXX
 SG_ Alert_Sub_System : 16|8@1+ (1.0,0) [0|255] "" Vector__XXX
 SG_ Alert_ID : 24|16@1+ (1.0,0) [0|65535] "" Vector__XXX
 SG_ Data_Source_Network_ID_NAME : 40|64@1+ (1.0,0) [0|18446744073709551615] "" Vector__XXX
 SG_ Data_Source_Instance : 104|8@1+ (1.0,0) [0|255] "" Vector__XXX
 SG_ Data_Source_Index_Source : 112|8@1+ (1.0,0) [0|255] "" Vector__XXX
 SG_ Alert_Occurrence_Number : 120|8@1+ (1.0,0) [0|255] "" Vector__XXX
 SG_ Acknowledge_Source_Network_ID_NAME : 128|64@1+ (1.0,0) [0|18446744073709551615] "" Vector__XXX
 SG_ Response_Command : 192|2@1+ (1.0,0) [0|3] "" Vector__XXX

BO_ 2582644992 PGN_126985_alertText: 19 Vector__XXX
 SG_ Alert_Type : 0|4@1+ (1.0,0) [0|15] "" Vector__XXX
 SG_ Alert_Category : 4|4@1+ (1.0,0) [0|15] "" Vector__XXX
 SG_ Alert_System : 8|8@1+ (1.0,0) [0|255] "" Vector__XXX
 SG_ Alert_Sub_System : 16|8@1+ (1.0,0) [0|255] "" Vector__XXX
 SG_ Alert_ID : 24|16@1+ (1.0,0) [0|65535] "" Vector__XXX
 SG_ Data_Source_Network_ID_NAME : 40|64@1+ (1.0,0) [0|18446744073709551615] "" Vector__XXX
 SG_ Data_Source_Instance : 104|8@1+ (1.0,0) [0|255] "" Vector__XXX
 SG_ Data_Source_Index_Source : 112|8@1+ (1.0,0) [0|255] "" Vector__XXX
 SG_ Alert_Occurrence_Number : 120|8@1+ (1.0,0) [0|255] "" Vector__XXX
 SG_ Language_ID : 128|8@1+ (1.0,0) [0|255] "" Vector__XXX
 SG_ Alert_Text_Description : 136|8@1+ (1.0,0) [0|255] "" Vector__XXX
 SG_ Alert_Location_Text_Description : 144|8@1+ (1.0,0) [0|255] "" Vector__XXX

BO_ 2582645248 PGN_126986_alertConfiguration: 20 Vector__XXX
 SG_ Alert_Type : 0|4@1+ (1.0,0) [0|15] "" Vector__XXX
 SG_ Alert_Category : 4|4@1+ (1.0,0) [0|15] "" Vector__XXX
 SG_ Alert_System : 8|8@1+ (1.0,0) [0|255] "" Vector__XXX
 SG_ Alert_Sub_System : 16|8@1+ (1.0,0) [0|255] "" Vector__XXX
 SG_ Alert_ID : 24|16@1+ (1.0,0) [0|65535] "" Vector__XXX
 SG_ Data_Source_Network_ID_NAME : 40|64@1+ (1.0,0) [0|18446744073709551615] "" Vector__XXX
 SG_ Data_Source_Instance : 104|8@1+ (1.0,0) [0|255] "" Vector__XXX
 SG_ Data_Source_Index_Source : 112|8@1+ (1.0,0) [0|255] "" Vector__XXX
 SG_ Alert_Occurrence_Number : 120|8@1+ (1.0,0) [0|255] "" Vector__XXX
 SG_ Alert_Control : 128|2@1+ (1.0,0) [0|3] "" Vector__XXX
 SG_ User_Defined_Alert_Assignment : 130|2@1+ (1.0,0) [0|3] "" Vector__XXX
 SG_ Reactivation_Period : 136|8@1+ (1.0,0) [0|255] "" Vector__XXX
 SG_ Temporary_Silence_Period : 144|8@1+ (1.0,0) [0|255] "" Vector__XXX
 SG_ Escalation_Period : 152|8@1+ (1.0,0) [0|255] "" Vector__XXX

CM_ BO_ 2649686016 "NMEA2000: PGN 126720 - Garmin Autopilot: Engine RPM A (type: Fast)";
CM_ BO_ 2649686016 "NMEA2000: PGN 126720 - Garmin Autopilot: Engine RPM B (type: Fast)";
CM_ BO_ 2649686016 "NMEA2000: PGN 126720 - Garmin Autopilot: Heading to Steer (type: Fast)";
CM_ BO_ 2649686016 "NMEA2000: PGN 126720 - Garmin Autopilot: Heartbeat (type: Fast)";
CM_ BO_ 2649686016 "NMEA2000: PGN 126720 - Garmin Autopilot: Maneuver (type: Fast)";
CM_ BO_ 2649686016 "NMEA2000: PGN 126720 - Garmin Autopilot: Mode State (type: Fast)";
CM_ BO_ 2649686016 "NMEA2000: PGN 126720 - Garmin Autopilot: Rate of Turn (type: Fast)";
CM_ BO_ 2649686016 "NMEA2000: PGN 126720 - Garmin Autopilot: Rate of Turn Order (type: Fast)";
CM_ BO_ 2649686016 "NMEA2000: PGN 126720 - Garmin Autopilot: Response Setting (type: Fast)";
CM_ BO_ 2649686016 "NMEA2000: PGN 126720 - Garmin Autopilot: Speed (type: Fast)";
CM_ BO_ 2649686016 "NMEA2000: PGN 126720 - Garmin Autopilot: System Voltage (type: Fast)";
CM_ BO_ 2649686016 "NMEA2000: PGN 126720 - Garmin Autopilot: Turn Angle Measured (type: Fast)";
CM_ BO_ 2649686016 "NMEA2000: PGN 126720 - Garmin Autopilot: Turn Angle Order (type: Fast)";
CM_ BO_ 2582642688 "NMEA2000: PGN 126976 - 0x1F000-0x1FEFF: Standardized mixed single/fast packet non-addressed (type: Mixed)";
CM_ BO_ 2582644480 "NMEA2000: PGN 126983 - Alert (type: Fast)";
CM_ BO_ 2582644736 "NMEA2000: PGN 126984 - Alert Response (type: Fast)";
CM_ BO_ 2582644992 "NMEA2000: PGN 126985 - Alert Text (type: Fast)";
CM_ BO_ 2582645248 "NMEA2000: PGN 126986 - Alert Configuration (type: Fast)";
CM_ SG_ 2582577152 Industry_Code "canboat type: LOOKUP";
CM_ SG_ 2582577152 Data "canboat type: BINARY";
CM_ SG_ 2582577152 Industry_Code "Marine Industry; canboat type: LOOKUP";
CM_ SG_ 2582577152 Proprietary_ID "canboat type: UINT8";
CM_ SG_ 2582577152 Industry_Code "Marine Industry; canboat type: LOOKUP";
CM_ SG_ 2582577152 Proprietary_ID "Attitude Offsets; canboat type: LOOKUP";
CM_ SG_ 2582577152 Azimuth_offset "Positive: sensor rotated to port, negative: sensor rotated to starboard; canboat type: ANGLE_FIX16";
CM_ SG_ 2582577152 Pitch_offset "Positive: sensor tilted to bow, negative: sensor tilted to stern; canboat type: ANGLE_FIX16";
CM_ SG_ 2582577152 Roll_offset "Positive: sensor tilted to port, negative: sensor tilted to starboard; canboat type: ANGLE_FIX16";
CM_ SG_ 2582577152 Industry_Code "Marine Industry; canboat type: LOOKUP";
CM_ SG_ 2582577152 Proprietary_ID "Calibrate Compass; canboat type: LOOKUP";
CM_ SG_ 2582577152 Calibrate_Function "canboat type: LOOKUP";
CM_ SG_ 2582577152 Calibration_Status "canboat type: LOOKUP";
CM_ SG_ 2582577152 Verify_Score "TBD; canboat type: UINT8";
CM_ SG_ 2582577152 X_axis_gain_value "default 100, range 50 to 500; canboat type: DILUTION_OF_PRECISION_FIX16";
CM_ SG_ 2582577152 Y_axis_gain_value "default 100, range 50 to 500; canboat type: DILUTION_OF_PRECISION_FIX16";
CM_ SG_ 2582577152 Z_axis_gain_value "default 100, range 50 to 500; canboat type: DILUTION_OF_PRECISION_FIX16";
CM_ SG_ 2582577152 X_axis_linear_offset "canboat type: MAGNETIC_FIELD_FIX16";
CM_ SG_ 2582577152 Y_axis_linear_offset "canboat type: MAGNETIC_FIELD_FIX16";
CM_ SG_ 2582577152 Z_axis_linear_offset "canboat type: MAGNETIC_FIELD_FIX16";
CM_ SG_ 2582577152 X_axis_angular_offset "canboat type: ANGLE_FIX16_DDEG";
CM_ SG_ 2582577152 Pitch_and_Roll_damping "default 30, range 0 to 200; canboat type: DURATION_FIX16_5CS";
CM_ SG_ 2582577152 Compass_Rate_gyro_damping "default -30, range -2400 to 2400, negative indicates rate gyro is to be used in compass calculations; canboat type: DURATION_FIX16_5CS";
CM_ SG_ 2582577152 Industry_Code "Marine Industry; canboat type: LOOKUP";
CM_ SG_ 2582577152 Proprietary_ID "Calibrate Depth; canboat type: LOOKUP";
CM_ SG_ 2582577152 Speed_of_Sound_Mode "actual allowed range is 1350.0 to 1650.0 m/s; canboat type: SPEED_UFIX16_DM";
CM_ SG_ 2582577152 Industry_Code "Marine Industry; canboat type: LOOKUP";
CM_ SG_ 2582577152 Proprietary_ID "Calibrate Speed; canboat type: LOOKUP";
CM_ SG_ 2582577152 Number_of_pairs_of_data_points "actual range is 0 to 25. 254=restore default speed curve; canboat type: UINT8";
CM_ SG_ 2582577152 field32 "canboat type: NUMBER";
CM_ SG_ 2582577152 Industry_Code "Marine Industry; canboat type: LOOKUP";
CM_ SG_ 2582577152 Proprietary_ID "Calibrate Temperature; canboat type: LOOKUP";
CM_ SG_ 2582577152 Temperature_instance "canboat type: LOOKUP";
CM_ SG_ 2582577152 Temperature_offset "canboat type: INT16";
CM_ SG_ 2582577152 Industry_Code "Marine Industry; canboat type: LOOKUP";
CM_ SG_ 2582577152 Proprietary_ID "NMEA 2000 options; canboat type: LOOKUP";
CM_ SG_ 2582577152 Transmission_Interval "canboat type: LOOKUP";
CM_ SG_ 2582577152 Industry_Code "Marine Industry; canboat type: LOOKUP";
CM_ SG_ 2582577152 Proprietary_ID "Simulate Mode; canboat type: LOOKUP";
CM_ SG_ 2582577152 Simulate_Mode "canboat type: LOOKUP";
CM_ SG_ 2582577152 Industry_Code "Marine Industry; canboat type: LOOKUP";
CM_ SG_ 2582577152 Proprietary_ID "Speed Filter; canboat type: LOOKUP";
CM_ SG_ 2582577152 Filter_type "IIR filter; canboat type: UNSIGNED_INTEGER";
CM_ SG_ 2582577152 Sample_interval "Interval of time between successive samples of the paddlewheel pulse accumulator; canboat type: DURATION_UFIX16_CS";
CM_ SG_ 2582577152 Filter_duration "Duration of filter, must be bigger than the sample interval; canboat type: DURATION_UFIX16_CS";
CM_ SG_ 2582577152 Industry_Code "Marine Industry; canboat type: LOOKUP";
CM_ SG_ 2582577152 Proprietary_ID "Speed Filter; canboat type: LOOKUP";
CM_ SG_ 2582577152 Filter_type "No filter; canboat type: UNSIGNED_INTEGER";
CM_ SG_ 2582577152 Sample_interval "Interval of time between successive samples of the paddlewheel pulse accumulator; canboat type: DURATION_UFIX16_CS";
CM_ SG_ 2582577152 Industry_Code "Marine Industry; canboat type: LOOKUP";
CM_ SG_ 2582577152 Proprietary_ID "Temperature Filter; canboat type: LOOKUP";
CM_ SG_ 2582577152 Filter_type "IIR filter; canboat type: UNSIGNED_INTEGER";
CM_ SG_ 2582577152 Sample_interval "Interval of time between successive samples of the water temperature thermistor; canboat type: DURATION_UFIX16_CS";
CM_ SG_ 2582577152 Filter_duration "Duration of filter, must be bigger than the sample interval; canboat type: DURATION_UFIX16_CS";
CM_ SG_ 2582577152 Industry_Code "Marine Industry; canboat type: LOOKUP";
CM_ SG_ 2582577152 Proprietary_ID "Temperature Filter; canboat type: LOOKUP";
CM_ SG_ 2582577152 Filter_type "No filter; canboat type: UNSIGNED_INTEGER";
CM_ SG_ 2582577152 Sample_interval "Interval of time between successive samples of the water temperature thermistor; canboat type: DURATION_UFIX16_CS";
CM_ SG_ 2582577152 Industry_Code "Marine Industry; canboat type: LOOKUP";
CM_ SG_ 2582577152 Proprietary_ID "True Wind Options; canboat type: LOOKUP";
CM_ SG_ 2582577152 COG_substitution_for_HDG "Allow use of COG when HDG not available?; canboat type: LOOKUP";
CM_ SG_ 2582577152 Industry_Code "Marine Industry; canboat type: LOOKUP";
CM_ SG_ 2582577152 Message_Type "canboat type: UINT8";
CM_ SG_ 2582577152 Breaker_Mapping_1 "canboat type: UINT8";
CM_ SG_ 2582577152 Breaker_Mapping_2 "canboat type: UINT8";
CM_ SG_ 2582577152 Breaker_Mapping_3 "canboat type: UNSIGNED_INTEGER";
CM_ SG_ 2582577152 Inrush_Delay "canboat type: UNSIGNED_INTEGER";
CM_ SG_ 2582577152 Trip_Delay "canboat type: UNSIGNED_INTEGER";
CM_ SG_ 2582577152 Configuration_Flags "canboat type: UINT8";
CM_ SG_ 2582577152 Current_Rating "canboat type: UINT8";
CM_ SG_ 2582577152 Factory_Max_Rating "canboat type: UINT8";
CM_ SG_ 2582577152 Schedule_B_Load_Shed_Priority "canboat type: UNSIGNED_INTEGER";
CM_ SG_ 2582577152 Schedule_A_Load_Shed_Priority "canboat type: UNSIGNED_INTEGER";
CM_ SG_ 2582577152 Dim_Value "canboat type: UINT8";
CM_ SG_ 2582577152 Breaker_Group "canboat type: UNSIGNED_INTEGER";
CM_ SG_ 2582577152 Flash_Map_Index "canboat type: UNSIGNED_INTEGER";
CM_ SG_ 2582577152 Industry_Code "Marine Industry; canboat type: LOOKUP";
CM_ SG_ 2582577152 Proprietary_ID "Media Command; canboat type: LOOKUP";
CM_ SG_ 2582577152 Source_ID "canboat type: UINT8";
CM_ SG_ 2582577152 Command "canboat type: LOOKUP";
CM_ SG_ 2582577152 Industry_Code "Marine Industry; canboat type: LOOKUP";
CM_ SG_ 2582577152 Proprietary_ID "Menu Action; canboat type: LOOKUP";
CM_ SG_ 2582577152 Source_ID "Runtime source identifier announced by Fusion Source status messages; not a stable source-type enumeration.; canboat type: UINT8";
CM_ SG_ 2582577152 Item_Index "canboat type: UINT32";
CM_ SG_ 2582577152 Action "canboat type: LOOKUP";
CM_ SG_ 2582577152 Lock_ID "canboat type: UINT8";
CM_ SG_ 2582577152 Industry_Code "Marine Industry; canboat type: LOOKUP";
CM_ SG_ 2582577152 Proprietary_ID "Request Menu Count; canboat type: LOOKUP";
CM_ SG_ 2582577152 Source_ID "Runtime source identifier announced by Fusion Source status messages; not a stable source-type enumeration.; canboat type: UINT8";
CM_ SG_ 2582577152 Lock_ID "canboat type: UINT8";
CM_ SG_ 2582577152 Industry_Code "Marine Industry; canboat type: LOOKUP";
CM_ SG_ 2582577152 Proprietary_ID "Request Menu Item; canboat type: LOOKUP";
CM_ SG_ 2582577152 Source_ID "Runtime source identifier announced by Fusion Source status messages; not a stable source-type enumeration.; canboat type: UINT8";
CM_ SG_ 2582577152 Start_Index "canboat type: UINT32";
CM_ SG_ 2582577152 Count "canboat type: UINT32";
CM_ SG_ 2582577152 Lock_ID "canboat type: UINT8";
CM_ SG_ 2582577152 Industry_Code "Marine Industry; canboat type: LOOKUP";
CM_ SG_ 2582577152 Proprietary_ID "Request Status; canboat type: LOOKUP";
CM_ SG_ 2582577152 Industry_Code "Marine Industry; canboat type: LOOKUP";
CM_ SG_ 2582577152 Proprietary_ID "Set All Volumes; canboat type: LOOKUP";
CM_ SG_ 2582577152 Zone1 "canboat type: UINT8";
CM_ SG_ 2582577152 Zone2 "canboat type: UINT8";
CM_ SG_ 2582577152 Zone3 "canboat type: UINT8";
CM_ SG_ 2582577152 Zone4 "canboat type: UINT8";
CM_ SG_ 2582577152 Industry_Code "Marine Industry; canboat type: LOOKUP";
CM_ SG_ 2582577152 Proprietary_ID "Set Mute; canboat type: LOOKUP";
CM_ SG_ 2582577152 Command "canboat type: LOOKUP";
CM_ SG_ 2582577152 Industry_Code "Marine Industry; canboat type: LOOKUP";
CM_ SG_ 2582577152 Proprietary_ID "Power; canboat type: LOOKUP";
CM_ SG_ 2582577152 Power "canboat type: LOOKUP";
CM_ SG_ 2582577152 Industry_Code "Marine Industry; canboat type: LOOKUP";
CM_ SG_ 2582577152 Proprietary_ID "Set Settings; canboat type: LOOKUP";
CM_ SG_ 2582577152 ID "canboat type: LOOKUP";
CM_ SG_ 2582577152 Value "canboat type: UINT32";
CM_ SG_ 2582577152 Industry_Code "Marine Industry; canboat type: LOOKUP";
CM_ SG_ 2582577152 Proprietary_ID "Set Source; canboat type: LOOKUP";
CM_ SG_ 2582577152 Source_ID "canboat type: UINT8";
CM_ SG_ 2582577152 Industry_Code "Marine Industry; canboat type: LOOKUP";
CM_ SG_ 2582577152 Proprietary_ID "Set Zone Volume; canboat type: LOOKUP";
CM_ SG_ 2582577152 Zone "canboat type: UINT8";
CM_ SG_ 2582577152 Volume "canboat type: UINT8";
CM_ SG_ 2582577152 Industry_Code "Marine Industry; canboat type: LOOKUP";
CM_ SG_ 2582577152 Proprietary_ID "Send Sirius Command; canboat type: LOOKUP";
CM_ SG_ 2582577152 Source_ID "canboat type: UINT8";
CM_ SG_ 2582577152 Command "canboat type: LOOKUP";
CM_ SG_ 2582577152 Data "canboat type: UINT16";
CM_ SG_ 2582577152 Industry_Code "Marine Industry; canboat type: LOOKUP";
CM_ SG_ 2582577152 Sub_protocol_ID "AHRS ATT transport; canboat type: LOOKUP";
CM_ SG_ 2582577152 Wrapper_Byte_1 "canboat type: UINT8";
CM_ SG_ 2582577152 Wrapper_Byte_2 "canboat type: UINT8";
CM_ SG_ 2582577152 ATT_Message_ID "COG Source Valid Flag; canboat type: LOOKUP";
CM_ SG_ 2582577152 COG_Source_Flags "canboat type: UINT32";
CM_ SG_ 2582577152 Industry_Code "Marine Industry; canboat type: LOOKUP";
CM_ SG_ 2582577152 Sub_protocol_ID "AHRS ATT transport; canboat type: LOOKUP";
CM_ SG_ 2582577152 Wrapper_Byte_1 "canboat type: UINT8";
CM_ SG_ 2582577152 Wrapper_Byte_2 "canboat type: UINT8";
CM_ SG_ 2582577152 ATT_Message_ID "Device Flags; canboat type: LOOKUP";
CM_ SG_ 2582577152 Device_Flags "canboat type: UINT32";
CM_ SG_ 2582577152 Industry_Code "Marine Industry; canboat type: LOOKUP";
CM_ SG_ 2582577152 Sub_protocol_ID "AHRS ATT transport; canboat type: LOOKUP";
CM_ SG_ 2582577152 Wrapper_Byte_1 "canboat type: UINT8";
CM_ SG_ 2582577152 Wrapper_Byte_2 "canboat type: UINT8";
CM_ SG_ 2582577152 ATT_Message_ID "Calibration Matrix Present; canboat type: LOOKUP";
CM_ SG_ 2582577152 Calibration_Matrix_Present "canboat type: UINT8";
CM_ SG_ 2582577152 Industry_Code "Marine Industry; canboat type: LOOKUP";
CM_ SG_ 2582577152 Sub_protocol_ID "AHRS ATT transport; canboat type: LOOKUP";
CM_ SG_ 2582577152 Wrapper_Byte_1 "canboat type: UINT8";
CM_ SG_ 2582577152 Wrapper_Byte_2 "canboat type: UINT8";
CM_ SG_ 2582577152 ATT_Message_ID "Set North State; canboat type: LOOKUP";
CM_ SG_ 2582577152 Set_North_State "canboat type: UINT8";
CM_ SG_ 2649686016 Manufacturer_Code "Garmin; canboat type: LOOKUP";
CM_ SG_ 2649686016 Industry_Code "Marine Industry; canboat type: LOOKUP";
CM_ SG_ 2649686016 Sub_protocol_ID "Autopilot transport; canboat type: LOOKUP";
CM_ SG_ 2649686016 Wrapper_Byte_1 "canboat type: UINT8";
CM_ SG_ 2649686016 Wrapper_Byte_2 "canboat type: UINT8";
CM_ SG_ 2649686016 Field_Group "canboat type: UINT8";
CM_ SG_ 2649686016 Field "Engine RPM A; canboat type: LOOKUP";
CM_ SG_ 2649686016 Engine_Speed "canboat type: UINT16";
CM_ SG_ 2649686016 Manufacturer_Code "Garmin; canboat type: LOOKUP";
CM_ SG_ 2649686016 Industry_Code "Marine Industry; canboat type: LOOKUP";
CM_ SG_ 2649686016 Sub_protocol_ID "Autopilot transport; canboat type: LOOKUP";
CM_ SG_ 2649686016 Wrapper_Byte_1 "canboat type: UINT8";
CM_ SG_ 2649686016 Wrapper_Byte_2 "canboat type: UINT8";
CM_ SG_ 2649686016 Field_Group "canboat type: UINT8";
CM_ SG_ 2649686016 Field "Engine RPM B; canboat type: LOOKUP";
CM_ SG_ 2649686016 Engine_Speed "canboat type: UINT16";
CM_ SG_ 2649686016 Manufacturer_Code "Garmin; canboat type: LOOKUP";
CM_ SG_ 2649686016 Industry_Code "Marine Industry; canboat type: LOOKUP";
CM_ SG_ 2649686016 Sub_protocol_ID "Autopilot transport; canboat type: LOOKUP";
CM_ SG_ 2649686016 Wrapper_Byte_1 "canboat type: UINT8";
CM_ SG_ 2649686016 Wrapper_Byte_2 "canboat type: UINT8";
CM_ SG_ 2649686016 Field_Group "canboat type: UINT8";
CM_ SG_ 2649686016 Field "Heading to Steer; canboat type: LOOKUP";
CM_ SG_ 2649686016 Heading_to_Steer "Values at or above 1000 rad signal no active order; canboat type: FLOAT_RAD";
CM_ SG_ 2649686016 Manufacturer_Code "Garmin; canboat type: LOOKUP";
CM_ SG_ 2649686016 Industry_Code "Marine Industry; canboat type: LOOKUP";
CM_ SG_ 2649686016 Sub_protocol_ID "Autopilot transport; canboat type: LOOKUP";
CM_ SG_ 2649686016 Wrapper_Byte_1 "canboat type: UINT8";
CM_ SG_ 2649686016 Wrapper_Byte_2 "canboat type: UINT8";
CM_ SG_ 2649686016 Field_Group "canboat type: UINT8";
CM_ SG_ 2649686016 Field "Heartbeat; canboat type: LOOKUP";
CM_ SG_ 2649686016 Heartbeat_Data "Fixed helm heartbeat payload (observed 01 00 c8 00); canboat type: BINARY";
CM_ SG_ 2649686016 Manufacturer_Code "Garmin; canboat type: LOOKUP";
CM_ SG_ 2649686016 Industry_Code "Marine Industry; canboat type: LOOKUP";
CM_ SG_ 2649686016 Sub_protocol_ID "Autopilot transport; canboat type: LOOKUP";
CM_ SG_ 2649686016 Wrapper_Byte_1 "canboat type: UINT8";
CM_ SG_ 2649686016 Wrapper_Byte_2 "canboat type: UINT8";
CM_ SG_ 2649686016 Field_Group "canboat type: UINT8";
CM_ SG_ 2649686016 Maneuver_Code "canboat type: LOOKUP";
CM_ SG_ 2649686016 Spare "canboat type: SPARE";
CM_ SG_ 2649686016 Value "canboat type: UINT8";
CM_ SG_ 2649686016 Manufacturer_Code "Garmin; canboat type: LOOKUP";
CM_ SG_ 2649686016 Industry_Code "Marine Industry; canboat type: LOOKUP";
CM_ SG_ 2649686016 Sub_protocol_ID "Autopilot transport; canboat type: LOOKUP";
CM_ SG_ 2649686016 Wrapper_Byte_1 "canboat type: UINT8";
CM_ SG_ 2649686016 Wrapper_Byte_2 "canboat type: UINT8";
CM_ SG_ 2649686016 Field_Group "canboat type: UINT8";
CM_ SG_ 2649686016 Field "Mode State; canboat type: LOOKUP";
CM_ SG_ 2649686016 Spare "canboat type: SPARE";
CM_ SG_ 2649686016 Mode_State "canboat type: LOOKUP";
CM_ SG_ 2649686016 Spare_1 "canboat type: SPARE";
CM_ SG_ 2649686016 Manufacturer_Code "Garmin; canboat type: LOOKUP";
CM_ SG_ 2649686016 Industry_Code "Marine Industry; canboat type: LOOKUP";
CM_ SG_ 2649686016 Sub_protocol_ID "Autopilot transport; canboat type: LOOKUP";
CM_ SG_ 2649686016 Wrapper_Byte_1 "canboat type: UINT8";
CM_ SG_ 2649686016 Wrapper_Byte_2 "canboat type: UINT8";
CM_ SG_ 2649686016 Field_Group "canboat type: UINT8";
CM_ SG_ 2649686016 Field "Rate of Turn; canboat type: LOOKUP";
CM_ SG_ 2649686016 Rate_of_Turn "canboat type: FLOAT_RAD_S";
CM_ SG_ 2649686016 Manufacturer_Code "Garmin; canboat type: LOOKUP";
CM_ SG_ 2649686016 Industry_Code "Marine Industry; canboat type: LOOKUP";
CM_ SG_ 2649686016 Sub_protocol_ID "Autopilot transport; canboat type: LOOKUP";
CM_ SG_ 2649686016 Wrapper_Byte_1 "canboat type: UINT8";
CM_ SG_ 2649686016 Wrapper_Byte_2 "canboat type: UINT8";
CM_ SG_ 2649686016 Field_Group "canboat type: UINT8";
CM_ SG_ 2649686016 Field "Rate of Turn Order; canboat type: LOOKUP";
CM_ SG_ 2649686016 Rate_of_Turn_Order "canboat type: FLOAT_RAD_S";
CM_ SG_ 2649686016 Manufacturer_Code "Garmin; canboat type: LOOKUP";
CM_ SG_ 2649686016 Industry_Code "Marine Industry; canboat type: LOOKUP";
CM_ SG_ 2649686016 Sub_protocol_ID "Autopilot transport; canboat type: LOOKUP";
CM_ SG_ 2649686016 Wrapper_Byte_1 "canboat type: UINT8";
CM_ SG_ 2649686016 Wrapper_Byte_2 "canboat type: UINT8";
CM_ SG_ 2649686016 Field_Group "canboat type: UINT8";
CM_ SG_ 2649686016 Field "Response Setting; canboat type: LOOKUP";
CM_ SG_ 2649686016 Response_Setting "canboat type: INT8";
CM_ SG_ 2649686016 Manufacturer_Code "Garmin; canboat type: LOOKUP";
CM_ SG_ 2649686016 Industry_Code "Marine Industry; canboat type: LOOKUP";
CM_ SG_ 2649686016 Sub_protocol_ID "Autopilot transport; canboat type: LOOKUP";
CM_ SG_ 2649686016 Wrapper_Byte_1 "canboat type: UINT8";
CM_ SG_ 2649686016 Wrapper_Byte_2 "canboat type: UINT8";
CM_ SG_ 2649686016 Field_Group "canboat type: UINT8";
CM_ SG_ 2649686016 Field "Speed; canboat type: LOOKUP";
CM_ SG_ 2649686016 Speed "canboat type: FLOAT_SPEED";
CM_ SG_ 2649686016 Manufacturer_Code "Garmin; canboat type: LOOKUP";
CM_ SG_ 2649686016 Industry_Code "Marine Industry; canboat type: LOOKUP";
CM_ SG_ 2649686016 Sub_protocol_ID "Autopilot transport; canboat type: LOOKUP";
CM_ SG_ 2649686016 Wrapper_Byte_1 "canboat type: UINT8";
CM_ SG_ 2649686016 Wrapper_Byte_2 "canboat type: UINT8";
CM_ SG_ 2649686016 Field_Group "canboat type: UINT8";
CM_ SG_ 2649686016 Field "System Voltage; canboat type: LOOKUP";
CM_ SG_ 2649686016 System_Voltage "canboat type: VOLTAGE_UFIX16_10MV";
CM_ SG_ 2649686016 Manufacturer_Code "Garmin; canboat type: LOOKUP";
CM_ SG_ 2649686016 Industry_Code "Marine Industry; canboat type: LOOKUP";
CM_ SG_ 2649686016 Sub_protocol_ID "Autopilot transport; canboat type: LOOKUP";
CM_ SG_ 2649686016 Wrapper_Byte_1 "canboat type: UINT8";
CM_ SG_ 2649686016 Wrapper_Byte_2 "canboat type: UINT8";
CM_ SG_ 2649686016 Field_Group "canboat type: UINT8";
CM_ SG_ 2649686016 Field "Turn Angle Measured; canboat type: LOOKUP";
CM_ SG_ 2649686016 Turn_Angle_Measured "Full-circle angle, wraps 0..2*pi (2*pi/65536 rad per bit); canboat type: UINT16";
CM_ SG_ 2649686016 Manufacturer_Code "Garmin; canboat type: LOOKUP";
CM_ SG_ 2649686016 Industry_Code "Marine Industry; canboat type: LOOKUP";
CM_ SG_ 2649686016 Sub_protocol_ID "Autopilot transport; canboat type: LOOKUP";
CM_ SG_ 2649686016 Wrapper_Byte_1 "canboat type: UINT8";
CM_ SG_ 2649686016 Wrapper_Byte_2 "canboat type: UINT8";
CM_ SG_ 2649686016 Field_Group "canboat type: UINT8";
CM_ SG_ 2649686016 Field "Turn Angle Order; canboat type: LOOKUP";
CM_ SG_ 2649686016 Turn_Angle_Order "Full-circle angle, wraps 0..2*pi (2*pi/65536 rad per bit); canboat type: UINT16";
CM_ SG_ 2582577152 Industry_Code "Marine Industry; canboat type: LOOKUP";
CM_ SG_ 2582577152 Unknown_ID_1 "Always 222; canboat type: UINT8";
CM_ SG_ 2582577152 Unknown_ID_2 "Always 5; canboat type: UINT8";
CM_ SG_ 2582577152 Unknown_ID_3 "Always 5; canboat type: UINT8";
CM_ SG_ 2582577152 Unknown_ID_4 "Always 5; canboat type: UINT8";
CM_ SG_ 2582577152 Spare "canboat type: SPARE";
CM_ SG_ 2582577152 Mode "Color; canboat type: LOOKUP";
CM_ SG_ 2582577152 Spare_1 "canboat type: SPARE";
CM_ SG_ 2582577152 Color "canboat type: LOOKUP";
CM_ SG_ 2582577152 Industry_Code "Marine Industry; canboat type: LOOKUP";
CM_ SG_ 2582577152 Unknown_ID_1 "Always 222; canboat type: UINT8";
CM_ SG_ 2582577152 Unknown_ID_2 "Always 5; canboat type: UINT8";
CM_ SG_ 2582577152 Unknown_ID_3 "Always 5; canboat type: UINT8";
CM_ SG_ 2582577152 Unknown_ID_4 "Always 5; canboat type: UINT8";
CM_ SG_ 2582577152 Spare "canboat type: SPARE";
CM_ SG_ 2582577152 Mode "Day; canboat type: LOOKUP";
CM_ SG_ 2582577152 Spare_1 "canboat type: SPARE";
CM_ SG_ 2582577152 Backlight "canboat type: LOOKUP";
CM_ SG_ 2582577152 Industry_Code "Marine Industry; canboat type: LOOKUP";
CM_ SG_ 2582577152 Unknown_ID_1 "Always 222; canboat type: UINT8";
CM_ SG_ 2582577152 Unknown_ID_2 "Always 5; canboat type: UINT8";
CM_ SG_ 2582577152 Unknown_ID_3 "Always 5; canboat type: UINT8";
CM_ SG_ 2582577152 Unknown_ID_4 "Always 5; canboat type: UINT8";
CM_ SG_ 2582577152 Spare "canboat type: SPARE";
CM_ SG_ 2582577152 Mode "Night; canboat type: LOOKUP";
CM_ SG_ 2582577152 Spare_1 "canboat type: SPARE";
CM_ SG_ 2582577152 Backlight "canboat type: LOOKUP";
CM_ SG_ 2582577152 Industry_Code "Marine Industry; canboat type: LOOKUP";
CM_ SG_ 2582577152 Data "canboat type: BINARY";
CM_ SG_ 2582577152 Industry_Code "Marine Industry; canboat type: LOOKUP";
CM_ SG_ 2582577152 Product_code "canboat type: LOOKUP";
CM_ SG_ 2582577152 Software_code "Version 1; canboat type: LOOKUP";
CM_ SG_ 2582577152 Command "Deviation calibration; canboat type: LOOKUP";
CM_ SG_ 2582577152 Status "canboat type: LOOKUP";
CM_ SG_ 2582577152 Industry_Code "Marine Industry; canboat type: LOOKUP";
CM_ SG_ 2582577152 Product_code "canboat type: LOOKUP";
CM_ SG_ 2582577152 Software_code "canboat type: UINT16";
CM_ SG_ 2582577152 Opcode "canboat type: LOOKUP";
CM_ SG_ 2582577152 Payload "canboat type: BINARY";
CM_ SG_ 2582577152 Industry_Code "Marine Industry; canboat type: LOOKUP";
CM_ SG_ 2582577152 Proprietary_ID "Seatalk 1 Encoded; canboat type: LOOKUP";
CM_ SG_ 2582577152 command "Seatalk1; canboat type: LOOKUP";
CM_ SG_ 2582577152 Seatalk1_Command "Device Identification; canboat type: LOOKUP";
CM_ SG_ 2582577152 device "canboat type: LOOKUP";
CM_ SG_ 2582577152 Industry_Code "Marine Industry; canboat type: LOOKUP";
CM_ SG_ 2582577152 Proprietary_ID "Display; canboat type: LOOKUP";
CM_ SG_ 2582577152 command1 "Settings; canboat type: LOOKUP";
CM_ SG_ 2582577152 Group "canboat type: LOOKUP";
CM_ SG_ 2582577152 Shared "canboat type: LOOKUP";
CM_ SG_ 2582577152 Command "Brightness; canboat type: UINT8";
CM_ SG_ 2582577152 Brightness "canboat type: PERCENTAGE_UINT8";
CM_ SG_ 2582577152 Unknown_2 "canboat type: BINARY";
CM_ SG_ 2582577152 Industry_Code "Marine Industry; canboat type: LOOKUP";
CM_ SG_ 2582577152 Proprietary_ID "Display; canboat type: LOOKUP";
CM_ SG_ 2582577152 command1 "Settings; canboat type: LOOKUP";
CM_ SG_ 2582577152 Group "canboat type: LOOKUP";
CM_ SG_ 2582577152 Unknown_1 "canboat type: BINARY";
CM_ SG_ 2582577152 Command "Color; canboat type: UINT8";
CM_ SG_ 2582577152 Color "canboat type: LOOKUP";
CM_ SG_ 2582577152 Unknown_2 "canboat type: BINARY";
CM_ SG_ 2582577152 Industry_Code "Marine Industry; canboat type: LOOKUP";
CM_ SG_ 2582577152 Proprietary_ID "Seatalk 1 Encoded; canboat type: LOOKUP";
CM_ SG_ 2582577152 command "Seatalk1; canboat type: LOOKUP";
CM_ SG_ 2582577152 Seatalk1_Command "Keystroke; canboat type: LOOKUP";
CM_ SG_ 2582577152 device "canboat type: UINT8";
CM_ SG_ 2582577152 key "canboat type: LOOKUP";
CM_ SG_ 2582577152 keyInverted "Bit negated version of key; canboat type: UINT8";
CM_ SG_ 2582577152 Unknown_data "canboat type: BINARY";
CM_ SG_ 2582577152 Industry_Code "Marine Industry; canboat type: LOOKUP";
CM_ SG_ 2582577152 Proprietary_ID "Pilot Configuration; canboat type: LOOKUP";
CM_ SG_ 2582577152 command "Hull Type; canboat type: LOOKUP";
CM_ SG_ 2582577152 Unknown "canboat type: BINARY";
CM_ SG_ 2582577152 Hull_Type "canboat type: LOOKUP";
CM_ SG_ 2582577152 Unknown_2 "canboat type: BINARY";
CM_ SG_ 2582577152 Industry_Code "Marine Industry; canboat type: LOOKUP";
CM_ SG_ 2582577152 Proprietary_ID "Seatalk 1 Encoded; canboat type: LOOKUP";
CM_ SG_ 2582577152 command "Seatalk1; canboat type: LOOKUP";
CM_ SG_ 2582577152 Seatalk1_Command "Compass heading Autopilot course and Rudder position; canboat type: LOOKUP";
CM_ SG_ 2582577152 Unknown_1 "canboat type: BINARY";
CM_ SG_ 2582577152 Pilot_Mode "canboat type: LOOKUP";
CM_ SG_ 2582577152 Sub_Mode "canboat type: UINT8";
CM_ SG_ 2582577152 Pilot_Mode_Data "canboat type: BINARY";
CM_ SG_ 2582577152 Unknown_2 "canboat type: BINARY";
CM_ SG_ 2582577152 Industry_Code "Marine Industry; canboat type: LOOKUP";
CM_ SG_ 2582577152 Proprietary_ID "Pilot Configuration; canboat type: LOOKUP";
CM_ SG_ 2582577152 command "Auto Turn; canboat type: LOOKUP";
CM_ SG_ 2582577152 Unknown "canboat type: BINARY";
CM_ SG_ 2582577152 Enabled "canboat type: LOOKUP";
CM_ SG_ 2582577152 Unknown_2 "canboat type: LOOKUP";
CM_ SG_ 2582577152 Unknown_3 "canboat type: BINARY";
CM_ SG_ 2582642688 Data "canboat type: BINARY";
CM_ SG_ 2582644480 Alert_Type "canboat type: LOOKUP";
CM_ SG_ 2582644480 Alert_Category "canboat type: LOOKUP";
CM_ SG_ 2582644480 Alert_System "canboat type: UINT8";
CM_ SG_ 2582644480 Alert_Sub_System "canboat type: UINT8";
CM_ SG_ 2582644480 Alert_ID "canboat type: UINT16";
CM_ SG_ 2582644480 Data_Source_Network_ID_NAME "canboat type: ISO_NAME";
CM_ SG_ 2582644480 Data_Source_Instance "canboat type: UINT8";
CM_ SG_ 2582644480 Data_Source_Index_Source "canboat type: UINT8";
CM_ SG_ 2582644480 Alert_Occurrence_Number "canboat type: UINT8";
CM_ SG_ 2582644480 Temporary_Silence_Status "canboat type: LOOKUP";
CM_ SG_ 2582644480 Acknowledge_Status "canboat type: LOOKUP";
CM_ SG_ 2582644480 Escalation_Status "canboat type: LOOKUP";
CM_ SG_ 2582644480 Temporary_Silence_Support "canboat type: LOOKUP";
CM_ SG_ 2582644480 Acknowledge_Support "canboat type: LOOKUP";
CM_ SG_ 2582644480 Escalation_Support "canboat type: LOOKUP";
CM_ SG_ 2582644480 Acknowledge_Source_Network_ID_NAME "canboat type: ISO_NAME";
CM_ SG_ 2582644480 Trigger_Condition "canboat type: LOOKUP";
CM_ SG_ 2582644480 Threshold_Status "canboat type: LOOKUP";
CM_ SG_ 2582644480 Alert_Priority "canboat type: UINT8";
CM_ SG_ 2582644480 Alert_State "canboat type: LOOKUP";
CM_ SG_ 2582644736 Alert_Type "canboat type: LOOKUP";
CM_ SG_ 2582644736 Alert_Category "canboat type: LOOKUP";
CM_ SG_ 2582644736 Alert_System "canboat type: UINT8";
CM_ SG_ 2582644736 Alert_Sub_System "canboat type: UINT8";
CM_ SG_ 2582644736 Alert_ID "canboat type: UINT16";
CM_ SG_ 2582644736 Data_Source_Network_ID_NAME "canboat type: ISO_NAME";
CM_ SG_ 2582644736 Data_Source_Instance "canboat type: UINT8";
CM_ SG_ 2582644736 Data_Source_Index_Source "canboat type: UINT8";
CM_ SG_ 2582644736 Alert_Occurrence_Number "canboat type: UINT8";
CM_ SG_ 2582644736 Acknowledge_Source_Network_ID_NAME "canboat type: ISO_NAME";
CM_ SG_ 2582644736 Response_Command "canboat type: LOOKUP";
CM_ SG_ 2582644992 Alert_Type "canboat type: LOOKUP";
CM_ SG_ 2582644992 Alert_Category "canboat type: LOOKUP";
CM_ SG_ 2582644992 Alert_System "canboat type: UINT8";
CM_ SG_ 2582644992 Alert_Sub_System "canboat type: UINT8";
CM_ SG_ 2582644992 Alert_ID "canboat type: UINT16";
CM_ SG_ 2582644992 Data_Source_Network_ID_NAME "canboat type: ISO_NAME";
CM_ SG_ 2582644992 Data_Source_Instance "canboat type: UINT8";
CM_ SG_ 2582644992 Data_Source_Index_Source "canboat type: UINT8";
CM_ SG_ 2582644992 Alert_Occurrence_Number "canboat type: UINT8";
CM_ SG_ 2582644992 Language_ID "canboat type: LOOKUP";
CM_ SG_ 2582644992 Alert_Text_Description "canboat type: STRING_LAU";
CM_ SG_ 2582644992 Alert_Location_Text_Description "canboat type: STRING_LAU";
CM_ SG_ 2582645248 Alert_Type "canboat type: LOOKUP";
CM_ SG_ 2582645248 Alert_Category "canboat type: LOOKUP";
CM_ SG_ 2582645248 Alert_System "canboat type: UINT8";
CM_ SG_ 2582645248 Alert_Sub_System "canboat type: UINT8";
CM_ SG_ 2582645248 Alert_ID "canboat type: UINT16";
CM_ SG_ 2582645248 Data_Source_Network_ID_NAME "canboat type: ISO_NAME";
CM_ SG_ 2582645248 Data_Source_Instance "canboat type: UINT8";
CM_ SG_ 2582645248 Data_Source_Index_Source "canboat type: UINT8";
CM_ SG_ 2582645248 Alert_Occurrence_Number "canboat type: UINT8";
CM_ SG_ 2582645248 Alert_Control "canboat type: UNSIGNED_INTEGER";
CM_ SG_ 2582645248 User_Defined_Alert_Assignment "canboat type: UNSIGNED_INTEGER";
CM_ SG_ 2582645248 Reactivation_Period "canboat type: UINT8";
CM_ SG_ 2582645248 Temporary_Silence_Period "canboat type: UINT8";
CM_ SG_ 2582645248 Escalation_Period "canboat type: UINT8";
VAL_ 2582577152 Industry_Code 0 "Global" 1 "Highway" 2 "Agriculture" 3 "Construction" 4 "Marine Industry" 5 "Industrial" ;
VAL_ 2582577152 Industry_Code 0 "Global" 1 "Highway" 2 "Agriculture" 3 "Construction" 4 "Marine Industry" 5 "Industrial" ;
VAL_ 2582577152 Industry_Code 0 "Global" 1 "Highway" 2 "Agriculture" 3 "Construction" 4 "Marine Industry" 5 "Industrial" ;
VAL_ 2582577152 Proprietary_ID 32 "Attitude Offsets" 33 "Calibrate Compass" 34 "True Wind Options" 35 "Simulate Mode" 40 "Calibrate Depth" 41 "Calibrate Speed" 42 "Calibrate Temperature" 43 "Speed Filter" 44 "Temperature Filter" 46 "NMEA 2000 options" ;
VAL_ 2582577152 Industry_Code 0 "Global" 1 "Highway" 2 "Agriculture" 3 "Construction" 4 "Marine Industry" 5 "Industrial" ;
VAL_ 2582577152 Proprietary_ID 32 "Attitude Offsets" 33 "Calibrate Compass" 34 "True Wind Options" 35 "Simulate Mode" 40 "Calibrate Depth" 41 "Calibrate Speed" 42 "Calibrate Temperature" 43 "Speed Filter" 44 "Temperature Filter" 46 "NMEA 2000 options" ;
VAL_ 2582577152 Calibrate_Function 0 "Normal/cancel calibration" 1 "Enter calibration mode" 2 "Reset calibration to 0" 3 "Verify" 4 "Reset compass to defaults" 5 "Reset damping to defaults" ;
VAL_ 2582577152 Calibration_Status 0 "Queried" 1 "Passed" 2 "Failed - timeout" 3 "Failed - tilt error" 4 "Failed - other" 5 "In progress" ;
VAL_ 2582577152 Industry_Code 0 "Global" 1 "Highway" 2 "Agriculture" 3 "Construction" 4 "Marine Industry" 5 "Industrial" ;
VAL_ 2582577152 Proprietary_ID 32 "Attitude Offsets" 33 "Calibrate Compass" 34 "True Wind Options" 35 "Simulate Mode" 40 "Calibrate Depth" 41 "Calibrate Speed" 42 "Calibrate Temperature" 43 "Speed Filter" 44 "Temperature Filter" 46 "NMEA 2000 options" ;
VAL_ 2582577152 Industry_Code 0 "Global" 1 "Highway" 2 "Agriculture" 3 "Construction" 4 "Marine Industry" 5 "Industrial" ;
VAL_ 2582577152 Proprietary_ID 32 "Attitude Offsets" 33 "Calibrate Compass" 34 "True Wind Options" 35 "Simulate Mode" 40 "Calibrate Depth" 41 "Calibrate Speed" 42 "Calibrate Temperature" 43 "Speed Filter" 44 "Temperature Filter" 46 "NMEA 2000 options" ;
VAL_ 2582577152 Industry_Code 0 "Global" 1 "Highway" 2 "Agriculture" 3 "Construction" 4 "Marine Industry" 5 "Industrial" ;
VAL_ 2582577152 Proprietary_ID 32 "Attitude Offsets" 33 "Calibrate Compass" 34 "True Wind Options" 35 "Simulate Mode" 40 "Calibrate Depth" 41 "Calibrate Speed" 42 "Calibrate Temperature" 43 "Speed Filter" 44 "Temperature Filter" 46 "NMEA 2000 options" ;
VAL_ 2582577152 Temperature_instance 0 "Device Sensor" 1 "Onboard Water Sensor" 2 "Optional Water Sensor" ;
VAL_ 2582577152 Industry_Code 0 "Global" 1 "Highway" 2 "Agriculture" 3 "Construction" 4 "Marine Industry" 5 "Industrial" ;
VAL_ 2582577152 Proprietary_ID 32 "Attitude Offsets" 33 "Calibrate Compass" 34 "True Wind Options" 35 "Simulate Mode" 40 "Calibrate Depth" 41 "Calibrate Speed" 42 "Calibrate Temperature" 43 "Speed Filter" 44 "Temperature Filter" 46 "NMEA 2000 options" ;
VAL_ 2582577152 Transmission_Interval 0 "Measure interval" 1 "Requested by user" ;
VAL_ 2582577152 Industry_Code 0 "Global" 1 "Highway" 2 "Agriculture" 3 "Construction" 4 "Marine Industry" 5 "Industrial" ;
VAL_ 2582577152 Proprietary_ID 32 "Attitude Offsets" 33 "Calibrate Compass" 34 "True Wind Options" 35 "Simulate Mode" 40 "Calibrate Depth" 41 "Calibrate Speed" 42 "Calibrate Temperature" 43 "Speed Filter" 44 "Temperature Filter" 46 "NMEA 2000 options" ;
VAL_ 2582577152 Simulate_Mode 0 "Off" 1 "On" ;
VAL_ 2582577152 Industry_Code 0 "Global" 1 "Highway" 2 "Agriculture" 3 "Construction" 4 "Marine Industry" 5 "Industrial" ;
VAL_ 2582577152 Proprietary_ID 32 "Attitude Offsets" 33 "Calibrate Compass" 34 "True Wind Options" 35 "Simulate Mode" 40 "Calibrate Depth" 41 "Calibrate Speed" 42 "Calibrate Temperature" 43 "Speed Filter" 44 "Temperature Filter" 46 "NMEA 2000 options" ;
VAL_ 2582577152 Industry_Code 0 "Global" 1 "Highway" 2 "Agriculture" 3 "Construction" 4 "Marine Industry" 5 "Industrial" ;
VAL_ 2582577152 Proprietary_ID 32 "Attitude Offsets" 33 "Calibrate Compass" 34 "True Wind Options" 35 "Simulate Mode" 40 "Calibrate Depth" 41 "Calibrate Speed" 42 "Calibrate Temperature" 43 "Speed Filter" 44 "Temperature Filter" 46 "NMEA 2000 options" ;
VAL_ 2582577152 Industry_Code 0 "Global" 1 "Highway" 2 "Agriculture" 3 "Construction" 4 "Marine Industry" 5 "Industrial" ;
VAL_ 2582577152 Proprietary_ID 32 "Attitude Offsets" 33 "Calibrate Compass" 34 "True Wind Options" 35 "Simulate Mode" 40 "Calibrate Depth" 41 "Calibrate Speed" 42 "Calibrate Temperature" 43 "Speed Filter" 44 "Temperature Filter" 46 "NMEA 2000 options" ;
VAL_ 2582577152 Industry_Code 0 "Global" 1 "Highway" 2 "Agriculture" 3 "Construction" 4 "Marine Industry" 5 "Industrial" ;
VAL_ 2582577152 Proprietary_ID 32 "Attitude Offsets" 33 "Calibrate Compass" 34 "True Wind Options" 35 "Simulate Mode" 40 "Calibrate Depth" 41 "Calibrate Speed" 42 "Calibrate Temperature" 43 "Speed Filter" 44 "Temperature Filter" 46 "NMEA 2000 options" ;
VAL_ 2582577152 Industry_Code 0 "Global" 1 "Highway" 2 "Agriculture" 3 "Construction" 4 "Marine Industry" 5 "Industrial" ;
VAL_ 2582577152 Proprietary_ID 32 "Attitude Offsets" 33 "Calibrate Compass" 34 "True Wind Options" 35 "Simulate Mode" 40 "Calibrate Depth" 41 "Calibrate Speed" 42 "Calibrate Temperature" 43 "Speed Filter" 44 "Temperature Filter" 46 "NMEA 2000 options" ;
VAL_ 2582577152 COG_substitution_for_HDG 0 "No" 1 "Yes" ;
VAL_ 2582577152 Industry_Code 0 "Global" 1 "Highway" 2 "Agriculture" 3 "Construction" 4 "Marine Industry" 5 "Industrial" ;
VAL_ 2582577152 Industry_Code 0 "Global" 1 "Highway" 2 "Agriculture" 3 "Construction" 4 "Marine Industry" 5 "Industrial" ;
VAL_ 2582577152 Proprietary_ID 1 "Request Status" 2 "Set Source" 3 "Media Command" 5 "Tuner Command" 6 "Marine Tuner Command" 7 "Set Marine Tuner Squelch" 8 "Set Marine Tuner Scan Mode" 9 "Menu Action" 10 "Request Menu Count" 11 "Request Menu Item" 12 "Request Menu Lock ID" 13 "Set Aux Gain" 15 "Set Settings" 16 "DAB Updtate Command" 17 "Set Mute" 18 "Set Balance" 19 "Set Low Pass Filer" 20 "Set Sublevel" 22 "Set Equalizer" 23 "Set Volume Limit" 24 "Set Zone Volume" 25 "Set All Volumes" 27 "Set Line Level Control" 28 "Power" 29 "Set Device Name" 30 "Send Sirius Command" 31 "Set Sirius Parental" 33 "Send Factory Reset Command" 34 "Set Zone Name" 35 "Send Dvd Command" 36 "Dvd Press Ir Key" 39 "Send Select Sirius Team" 40 "Send Select Sirius Artist" 41 "Send Sirius Sport Alert User Action" 45 "Send Sirius Artist Song User Action" 50 "Send Multiroom Command" 51 "Get Multiroom Device Record" 52 "Scan Multirooom Devices" 53 "Send File Transfer" 54 "Set Loud" 56 "Fapi Set Source Multiroom Enabled" 57 "Request Head Unit Dsp Settings" 64 "Send Transfer Status" 65 "Fapi Get Server Info" 69 "Fapi Set Source Enabled" 70 "Fapi Set Source Name" 73 "Send External Amp Gain" 74 "Send Internal Amp Gain" 75 "Send Mono" ;
VAL_ 2582577152 Command 1 "Play" 2 "Pause" 4 "Next" 6 "Prev" ;
VAL_ 2582577152 Industry_Code 0 "Global" 1 "Highway" 2 "Agriculture" 3 "Construction" 4 "Marine Industry" 5 "Industrial" ;
VAL_ 2582577152 Proprietary_ID 1 "Request Status" 2 "Set Source" 3 "Media Command" 5 "Tuner Command" 6 "Marine Tuner Command" 7 "Set Marine Tuner Squelch" 8 "Set Marine Tuner Scan Mode" 9 "Menu Action" 10 "Request Menu Count" 11 "Request Menu Item" 12 "Request Menu Lock ID" 13 "Set Aux Gain" 15 "Set Settings" 16 "DAB Updtate Command" 17 "Set Mute" 18 "Set Balance" 19 "Set Low Pass Filer" 20 "Set Sublevel" 22 "Set Equalizer" 23 "Set Volume Limit" 24 "Set Zone Volume" 25 "Set All Volumes" 27 "Set Line Level Control" 28 "Power" 29 "Set Device Name" 30 "Send Sirius Command" 31 "Set Sirius Parental" 33 "Send Factory Reset Command" 34 "Set Zone Name" 35 "Send Dvd Command" 36 "Dvd Press Ir Key" 39 "Send Select Sirius Team" 40 "Send Select Sirius Artist" 41 "Send Sirius Sport Alert User Action" 45 "Send Sirius Artist Song User Action" 50 "Send Multiroom Command" 51 "Get Multiroom Device Record" 52 "Scan Multirooom Devices" 53 "Send File Transfer" 54 "Set Loud" 56 "Fapi Set Source Multiroom Enabled" 57 "Request Head Unit Dsp Settings" 64 "Send Transfer Status" 65 "Fapi Get Server Info" 69 "Fapi Set Source Enabled" 70 "Fapi Set Source Name" 73 "Send External Amp Gain" 74 "Send Internal Amp Gain" 75 "Send Mono" ;
VAL_ 2582577152 Action 1 "Open" 2 "Select" 4 "Close" ;
VAL_ 2582577152 Industry_Code 0 "Global" 1 "Highway" 2 "Agriculture" 3 "Construction" 4 "Marine Industry" 5 "Industrial" ;
VAL_ 2582577152 Proprietary_ID 1 "Request Status" 2 "Set Source" 3 "Media Command" 5 "Tuner Command" 6 "Marine Tuner Command" 7 "Set Marine Tuner Squelch" 8 "Set Marine Tuner Scan Mode" 9 "Menu Action" 10 "Request Menu Count" 11 "Request Menu Item" 12 "Request Menu Lock ID" 13 "Set Aux Gain" 15 "Set Settings" 16 "DAB Updtate Command" 17 "Set Mute" 18 "Set Balance" 19 "Set Low Pass Filer" 20 "Set Sublevel" 22 "Set Equalizer" 23 "Set Volume Limit" 24 "Set Zone Volume" 25 "Set All Volumes" 27 "Set Line Level Control" 28 "Power" 29 "Set Device Name" 30 "Send Sirius Command" 31 "Set Sirius Parental" 33 "Send Factory Reset Command" 34 "Set Zone Name" 35 "Send Dvd Command" 36 "Dvd Press Ir Key" 39 "Send Select Sirius Team" 40 "Send Select Sirius Artist" 41 "Send Sirius Sport Alert User Action" 45 "Send Sirius Artist Song User Action" 50 "Send Multiroom Command" 51 "Get Multiroom Device Record" 52 "Scan Multirooom Devices" 53 "Send File Transfer" 54 "Set Loud" 56 "Fapi Set Source Multiroom Enabled" 57 "Request Head Unit Dsp Settings" 64 "Send Transfer Status" 65 "Fapi Get Server Info" 69 "Fapi Set Source Enabled" 70 "Fapi Set Source Name" 73 "Send External Amp Gain" 74 "Send Internal Amp Gain" 75 "Send Mono" ;
VAL_ 2582577152 Industry_Code 0 "Global" 1 "Highway" 2 "Agriculture" 3 "Construction" 4 "Marine Industry" 5 "Industrial" ;
VAL_ 2582577152 Proprietary_ID 1 "Request Status" 2 "Set Source" 3 "Media Command" 5 "Tuner Command" 6 "Marine Tuner Command" 7 "Set Marine Tuner Squelch" 8 "Set Marine Tuner Scan Mode" 9 "Menu Action" 10 "Request Menu Count" 11 "Request Menu Item" 12 "Request Menu Lock ID" 13 "Set Aux Gain" 15 "Set Settings" 16 "DAB Updtate Command" 17 "Set Mute" 18 "Set Balance" 19 "Set Low Pass Filer" 20 "Set Sublevel" 22 "Set Equalizer" 23 "Set Volume Limit" 24 "Set Zone Volume" 25 "Set All Volumes" 27 "Set Line Level Control" 28 "Power" 29 "Set Device Name" 30 "Send Sirius Command" 31 "Set Sirius Parental" 33 "Send Factory Reset Command" 34 "Set Zone Name" 35 "Send Dvd Command" 36 "Dvd Press Ir Key" 39 "Send Select Sirius Team" 40 "Send Select Sirius Artist" 41 "Send Sirius Sport Alert User Action" 45 "Send Sirius Artist Song User Action" 50 "Send Multiroom Command" 51 "Get Multiroom Device Record" 52 "Scan Multirooom Devices" 53 "Send File Transfer" 54 "Set Loud" 56 "Fapi Set Source Multiroom Enabled" 57 "Request Head Unit Dsp Settings" 64 "Send Transfer Status" 65 "Fapi Get Server Info" 69 "Fapi Set Source Enabled" 70 "Fapi Set Source Name" 73 "Send External Amp Gain" 74 "Send Internal Amp Gain" 75 "Send Mono" ;
VAL_ 2582577152 Industry_Code 0 "Global" 1 "Highway" 2 "Agriculture" 3 "Construction" 4 "Marine Industry" 5 "Industrial" ;
VAL_ 2582577152 Proprietary_ID 1 "Request Status" 2 "Set Source" 3 "Media Command" 5 "Tuner Command" 6 "Marine Tuner Command" 7 "Set Marine Tuner Squelch" 8 "Set Marine Tuner Scan Mode" 9 "Menu Action" 10 "Request Menu Count" 11 "Request Menu Item" 12 "Request Menu Lock ID" 13 "Set Aux Gain" 15 "Set Settings" 16 "DAB Updtate Command" 17 "Set Mute" 18 "Set Balance" 19 "Set Low Pass Filer" 20 "Set Sublevel" 22 "Set Equalizer" 23 "Set Volume Limit" 24 "Set Zone Volume" 25 "Set All Volumes" 27 "Set Line Level Control" 28 "Power" 29 "Set Device Name" 30 "Send Sirius Command" 31 "Set Sirius Parental" 33 "Send Factory Reset Command" 34 "Set Zone Name" 35 "Send Dvd Command" 36 "Dvd Press Ir Key" 39 "Send Select Sirius Team" 40 "Send Select Sirius Artist" 41 "Send Sirius Sport Alert User Action" 45 "Send Sirius Artist Song User Action" 50 "Send Multiroom Command" 51 "Get Multiroom Device Record" 52 "Scan Multirooom Devices" 53 "Send File Transfer" 54 "Set Loud" 56 "Fapi Set Source Multiroom Enabled" 57 "Request Head Unit Dsp Settings" 64 "Send Transfer Status" 65 "Fapi Get Server Info" 69 "Fapi Set Source Enabled" 70 "Fapi Set Source Name" 73 "Send External Amp Gain" 74 "Send Internal Amp Gain" 75 "Send Mono" ;
VAL_ 2582577152 Industry_Code 0 "Global" 1 "Highway" 2 "Agriculture" 3 "Construction" 4 "Marine Industry" 5 "Industrial" ;
VAL_ 2582577152 Proprietary_ID 1 "Request Status" 2 "Set Source" 3 "Media Command" 5 "Tuner Command" 6 "Marine Tuner Command" 7 "Set Marine Tuner Squelch" 8 "Set Marine Tuner Scan Mode" 9 "Menu Action" 10 "Request Menu Count" 11 "Request Menu Item" 12 "Request Menu Lock ID" 13 "Set Aux Gain" 15 "Set Settings" 16 "DAB Updtate Command" 17 "Set Mute" 18 "Set Balance" 19 "Set Low Pass Filer" 20 "Set Sublevel" 22 "Set Equalizer" 23 "Set Volume Limit" 24 "Set Zone Volume" 25 "Set All Volumes" 27 "Set Line Level Control" 28 "Power" 29 "Set Device Name" 30 "Send Sirius Command" 31 "Set Sirius Parental" 33 "Send Factory Reset Command" 34 "Set Zone Name" 35 "Send Dvd Command" 36 "Dvd Press Ir Key" 39 "Send Select Sirius Team" 40 "Send Select Sirius Artist" 41 "Send Sirius Sport Alert User Action" 45 "Send Sirius Artist Song User Action" 50 "Send Multiroom Command" 51 "Get Multiroom Device Record" 52 "Scan Multirooom Devices" 53 "Send File Transfer" 54 "Set Loud" 56 "Fapi Set Source Multiroom Enabled" 57 "Request Head Unit Dsp Settings" 64 "Send Transfer Status" 65 "Fapi Get Server Info" 69 "Fapi Set Source Enabled" 70 "Fapi Set Source Name" 73 "Send External Amp Gain" 74 "Send Internal Amp Gain" 75 "Send Mono" ;
VAL_ 2582577152 Industry_Code 0 "Global" 1 "Highway" 2 "Agriculture" 3 "Construction" 4 "Marine Industry" 5 "Industrial" ;
VAL_ 2582577152 Proprietary_ID 1 "Request Status" 2 "Set Source" 3 "Media Command" 5 "Tuner Command" 6 "Marine Tuner Command" 7 "Set Marine Tuner Squelch" 8 "Set Marine Tuner Scan Mode" 9 "Menu Action" 10 "Request Menu Count" 11 "Request Menu Item" 12 "Request Menu Lock ID" 13 "Set Aux Gain" 15 "Set Settings" 16 "DAB Updtate Command" 17 "Set Mute" 18 "Set Balance" 19 "Set Low Pass Filer" 20 "Set Sublevel" 22 "Set Equalizer" 23 "Set Volume Limit" 24 "Set Zone Volume" 25 "Set All Volumes" 27 "Set Line Level Control" 28 "Power" 29 "Set Device Name" 30 "Send Sirius Command" 31 "Set Sirius Parental" 33 "Send Factory Reset Command" 34 "Set Zone Name" 35 "Send Dvd Command" 36 "Dvd Press Ir Key" 39 "Send Select Sirius Team" 40 "Send Select Sirius Artist" 41 "Send Sirius Sport Alert User Action" 45 "Send Sirius Artist Song User Action" 50 "Send Multiroom Command" 51 "Get Multiroom Device Record" 52 "Scan Multirooom Devices" 53 "Send File Transfer" 54 "Set Loud" 56 "Fapi Set Source Multiroom Enabled" 57 "Request Head Unit Dsp Settings" 64 "Send Transfer Status" 65 "Fapi Get Server Info" 69 "Fapi Set Source Enabled" 70 "Fapi Set Source Name" 73 "Send External Amp Gain" 74 "Send Internal Amp Gain" 75 "Send Mono" ;
VAL_ 2582577152 Command 1 "Mute On" 2 "Mute Off" ;
VAL_ 2582577152 Industry_Code 0 "Global" 1 "Highway" 2 "Agriculture" 3 "Construction" 4 "Marine Industry" 5 "Industrial" ;
VAL_ 2582577152 Proprietary_ID 1 "Request Status" 2 "Set Source" 3 "Media Command" 5 "Tuner Command" 6 "Marine Tuner Command" 7 "Set Marine Tuner Squelch" 8 "Set Marine Tuner Scan Mode" 9 "Menu Action" 10 "Request Menu Count" 11 "Request Menu Item" 12 "Request Menu Lock ID" 13 "Set Aux Gain" 15 "Set Settings" 16 "DAB Updtate Command" 17 "Set Mute" 18 "Set Balance" 19 "Set Low Pass Filer" 20 "Set Sublevel" 22 "Set Equalizer" 23 "Set Volume Limit" 24 "Set Zone Volume" 25 "Set All Volumes" 27 "Set Line Level Control" 28 "Power" 29 "Set Device Name" 30 "Send Sirius Command" 31 "Set Sirius Parental" 33 "Send Factory Reset Command" 34 "Set Zone Name" 35 "Send Dvd Command" 36 "Dvd Press Ir Key" 39 "Send Select Sirius Team" 40 "Send Select Sirius Artist" 41 "Send Sirius Sport Alert User Action" 45 "Send Sirius Artist Song User Action" 50 "Send Multiroom Command" 51 "Get Multiroom Device Record" 52 "Scan Multirooom Devices" 53 "Send File Transfer" 54 "Set Loud" 56 "Fapi Set Source Multiroom Enabled" 57 "Request Head Unit Dsp Settings" 64 "Send Transfer Status" 65 "Fapi Get Server Info" 69 "Fapi Set Source Enabled" 70 "Fapi Set Source Name" 73 "Send External Amp Gain" 74 "Send Internal Amp Gain" 75 "Send Mono" ;
VAL_ 2582577152 Power 1 "On" 2 "Off" ;
VAL_ 2582577152 Industry_Code 0 "Global" 1 "Highway" 2 "Agriculture" 3 "Construction" 4 "Marine Industry" 5 "Industrial" ;
VAL_ 2582577152 Proprietary_ID 1 "Request Status" 2 "Set Source" 3 "Media Command" 5 "Tuner Command" 6 "Marine Tuner Command" 7 "Set Marine Tuner Squelch" 8 "Set Marine Tuner Scan Mode" 9 "Menu Action" 10 "Request Menu Count" 11 "Request Menu Item" 12 "Request Menu Lock ID" 13 "Set Aux Gain" 15 "Set Settings" 16 "DAB Updtate Command" 17 "Set Mute" 18 "Set Balance" 19 "Set Low Pass Filer" 20 "Set Sublevel" 22 "Set Equalizer" 23 "Set Volume Limit" 24 "Set Zone Volume" 25 "Set All Volumes" 27 "Set Line Level Control" 28 "Power" 29 "Set Device Name" 30 "Send Sirius Command" 31 "Set Sirius Parental" 33 "Send Factory Reset Command" 34 "Set Zone Name" 35 "Send Dvd Command" 36 "Dvd Press Ir Key" 39 "Send Select Sirius Team" 40 "Send Select Sirius Artist" 41 "Send Sirius Sport Alert User Action" 45 "Send Sirius Artist Song User Action" 50 "Send Multiroom Command" 51 "Get Multiroom Device Record" 52 "Scan Multirooom Devices" 53 "Send File Transfer" 54 "Set Loud" 56 "Fapi Set Source Multiroom Enabled" 57 "Request Head Unit Dsp Settings" 64 "Send Transfer Status" 65 "Fapi Get Server Info" 69 "Fapi Set Source Enabled" 70 "Fapi Set Source Name" 73 "Send External Amp Gain" 74 "Send Internal Amp Gain" 75 "Send Mono" ;
VAL_ 2582577152 ID 0 "Alpha Search Threshold" 1 "iPod Subtitles" 2 "Zone 2 Linked" 3 "Zone 2 Enabled" 4 "Zone 3 Enabled" 5 "Zone 4 Enabled" 6 "Telemute" 7 "Tuner Region" 8 "Marine Zone" 9 "USB repeat" 10 "USB shuffle" 11 "iPod Album Artwork" 12 "iPod repeat" 13 "iPod shuffle" 14 "AM Preset 0" 15 "AM Preset 1" 16 "AM Preset 2" 17 "AM Preset 3" 18 "AM Preset 4" 19 "AM Preset 5" 20 "AM Preset 6" 21 "AM Preset 7" 22 "AM Preset 8" 23 "AM Preset 9" 24 "AM Preset 10" 25 "AM Preset 11" 26 "AM Preset 12" 27 "AM Preset 13" 28 "AM Preset 14" 29 "FM Preset 0" 30 "FM Preset 1" 31 "FM Preset 2" 32 "FM Preset 3" 33 "FM Preset 4" 34 "FM Preset 5" 35 "FM Preset 6" 36 "FM Preset 7" 37 "FM Preset 8" 38 "FM Preset 9" 39 "FM Preset 10" 40 "FM Preset 11" 41 "FM Preset 12" 42 "FM Preset 13" 43 "FM Preset 14" 44 "VHF Preset 0" 45 "VHF Preset 1" 46 "VHF Preset 2" 47 "VHF Preset 3" 48 "VHF Preset 4" 49 "VHF Preset 5" 50 "VHF Preset 6" 51 "VHF Preset 7" 52 "VHF Preset 8" 53 "VHF Preset 9" 54 "VHF Preset 10" 55 "VHF Preset 11" 56 "VHF Preset 12" 57 "VHF Preset 13" 58 "VHF Preset 14" 59 "Clock Time" 60 "Clock Alarm" 61 "iPod Video Signal" 62 "iPod Monitor Aspect" 63 "Aux Name Index" 64 "AM Enabled" 65 "VHF Enabled" 66 "Language" 67 "Internal Amps On" 68 "MTP Repeat" 69 "MTP Shuffle" 70 "Id Accessory Source" 71 "NMEA Power" 72 "Low Power Mode" 73 "DVD region" 74 "Volume Zone Sync" 75 "Max Volume Start" 76 "BT Auto Connect" 77 "Null Setting" ;
VAL_ 2582577152 Industry_Code 0 "Global" 1 "Highway" 2 "Agriculture" 3 "Construction" 4 "Marine Industry" 5 "Industrial" ;
VAL_ 2582577152 Proprietary_ID 1 "Request Status" 2 "Set Source" 3 "Media Command" 5 "Tuner Command" 6 "Marine Tuner Command" 7 "Set Marine Tuner Squelch" 8 "Set Marine Tuner Scan Mode" 9 "Menu Action" 10 "Request Menu Count" 11 "Request Menu Item" 12 "Request Menu Lock ID" 13 "Set Aux Gain" 15 "Set Settings" 16 "DAB Updtate Command" 17 "Set Mute" 18 "Set Balance" 19 "Set Low Pass Filer" 20 "Set Sublevel" 22 "Set Equalizer" 23 "Set Volume Limit" 24 "Set Zone Volume" 25 "Set All Volumes" 27 "Set Line Level Control" 28 "Power" 29 "Set Device Name" 30 "Send Sirius Command" 31 "Set Sirius Parental" 33 "Send Factory Reset Command" 34 "Set Zone Name" 35 "Send Dvd Command" 36 "Dvd Press Ir Key" 39 "Send Select Sirius Team" 40 "Send Select Sirius Artist" 41 "Send Sirius Sport Alert User Action" 45 "Send Sirius Artist Song User Action" 50 "Send Multiroom Command" 51 "Get Multiroom Device Record" 52 "Scan Multirooom Devices" 53 "Send File Transfer" 54 "Set Loud" 56 "Fapi Set Source Multiroom Enabled" 57 "Request Head Unit Dsp Settings" 64 "Send Transfer Status" 65 "Fapi Get Server Info" 69 "Fapi Set Source Enabled" 70 "Fapi Set Source Name" 73 "Send External Amp Gain" 74 "Send Internal Amp Gain" 75 "Send Mono" ;
VAL_ 2582577152 Industry_Code 0 "Global" 1 "Highway" 2 "Agriculture" 3 "Construction" 4 "Marine Industry" 5 "Industrial" ;
VAL_ 2582577152 Proprietary_ID 1 "Request Status" 2 "Set Source" 3 "Media Command" 5 "Tuner Command" 6 "Marine Tuner Command" 7 "Set Marine Tuner Squelch" 8 "Set Marine Tuner Scan Mode" 9 "Menu Action" 10 "Request Menu Count" 11 "Request Menu Item" 12 "Request Menu Lock ID" 13 "Set Aux Gain" 15 "Set Settings" 16 "DAB Updtate Command" 17 "Set Mute" 18 "Set Balance" 19 "Set Low Pass Filer" 20 "Set Sublevel" 22 "Set Equalizer" 23 "Set Volume Limit" 24 "Set Zone Volume" 25 "Set All Volumes" 27 "Set Line Level Control" 28 "Power" 29 "Set Device Name" 30 "Send Sirius Command" 31 "Set Sirius Parental" 33 "Send Factory Reset Command" 34 "Set Zone Name" 35 "Send Dvd Command" 36 "Dvd Press Ir Key" 39 "Send Select Sirius Team" 40 "Send Select Sirius Artist" 41 "Send Sirius Sport Alert User Action" 45 "Send Sirius Artist Song User Action" 50 "Send Multiroom Command" 51 "Get Multiroom Device Record" 52 "Scan Multirooom Devices" 53 "Send File Transfer" 54 "Set Loud" 56 "Fapi Set Source Multiroom Enabled" 57 "Request Head Unit Dsp Settings" 64 "Send Transfer Status" 65 "Fapi Get Server Info" 69 "Fapi Set Source Enabled" 70 "Fapi Set Source Name" 73 "Send External Amp Gain" 74 "Send Internal Amp Gain" 75 "Send Mono" ;
VAL_ 2582577152 Industry_Code 0 "Global" 1 "Highway" 2 "Agriculture" 3 "Construction" 4 "Marine Industry" 5 "Industrial" ;
VAL_ 2582577152 Proprietary_ID 1 "Request Status" 2 "Set Source" 3 "Media Command" 5 "Tuner Command" 6 "Marine Tuner Command" 7 "Set Marine Tuner Squelch" 8 "Set Marine Tuner Scan Mode" 9 "Menu Action" 10 "Request Menu Count" 11 "Request Menu Item" 12 "Request Menu Lock ID" 13 "Set Aux Gain" 15 "Set Settings" 16 "DAB Updtate Command" 17 "Set Mute" 18 "Set Balance" 19 "Set Low Pass Filer" 20 "Set Sublevel" 22 "Set Equalizer" 23 "Set Volume Limit" 24 "Set Zone Volume" 25 "Set All Volumes" 27 "Set Line Level Control" 28 "Power" 29 "Set Device Name" 30 "Send Sirius Command" 31 "Set Sirius Parental" 33 "Send Factory Reset Command" 34 "Set Zone Name" 35 "Send Dvd Command" 36 "Dvd Press Ir Key" 39 "Send Select Sirius Team" 40 "Send Select Sirius Artist" 41 "Send Sirius Sport Alert User Action" 45 "Send Sirius Artist Song User Action" 50 "Send Multiroom Command" 51 "Get Multiroom Device Record" 52 "Scan Multirooom Devices" 53 "Send File Transfer" 54 "Set Loud" 56 "Fapi Set Source Multiroom Enabled" 57 "Request Head Unit Dsp Settings" 64 "Send Transfer Status" 65 "Fapi Get Server Info" 69 "Fapi Set Source Enabled" 70 "Fapi Set Source Name" 73 "Send External Amp Gain" 74 "Send Internal Amp Gain" 75 "Send Mono" ;
VAL_ 2582577152 Command 1 "Next" 2 "Prev" ;
VAL_ 2582577152 Industry_Code 0 "Global" 1 "Highway" 2 "Agriculture" 3 "Construction" 4 "Marine Industry" 5 "Industrial" ;
VAL_ 2582577152 Sub_protocol_ID 1900 "AHRS ATT transport" 5904 "Autopilot transport" ;
VAL_ 2582577152 ATT_Message_ID 40 "Calibration Matrix Present" 52 "Set North State" 65 "Device Flags" 67 "COG Source Valid Flag" ;
VAL_ 2582577152 Industry_Code 0 "Global" 1 "Highway" 2 "Agriculture" 3 "Construction" 4 "Marine Industry" 5 "Industrial" ;
VAL_ 2582577152 Sub_protocol_ID 1900 "AHRS ATT transport" 5904 "Autopilot transport" ;
VAL_ 2582577152 ATT_Message_ID 40 "Calibration Matrix Present" 52 "Set North State" 65 "Device Flags" 67 "COG Source Valid Flag" ;
VAL_ 2582577152 Industry_Code 0 "Global" 1 "Highway" 2 "Agriculture" 3 "Construction" 4 "Marine Industry" 5 "Industrial" ;
VAL_ 2582577152 Sub_protocol_ID 1900 "AHRS ATT transport" 5904 "Autopilot transport" ;
VAL_ 2582577152 ATT_Message_ID 40 "Calibration Matrix Present" 52 "Set North State" 65 "Device Flags" 67 "COG Source Valid Flag" ;
VAL_ 2582577152 Industry_Code 0 "Global" 1 "Highway" 2 "Agriculture" 3 "Construction" 4 "Marine Industry" 5 "Industrial" ;
VAL_ 2582577152 Sub_protocol_ID 1900 "AHRS ATT transport" 5904 "Autopilot transport" ;
VAL_ 2582577152 ATT_Message_ID 40 "Calibration Matrix Present" 52 "Set North State" 65 "Device Flags" 67 "COG Source Valid Flag" ;
VAL_ 2649686016 Manufacturer_Code 69 "ARKS Enterprises" 78 "FW Murphy/Enovation Controls" 80 "Twin Disc" 85 "Kohler Power Systems" 88 "Hemisphere GPS" 135 "Airmar" 137 "Maretron" 140 "Lowrance" 144 "Mercury Marine" 147 "Nautibus Electronic" 148 "Blue Water Data" 154 "Westerbeke" 157 "ISSPRO" 161 "Offshore Systems (UK)" 163 "Evinrude/BRP" 165 "CPAC Systems" 168 "Xantrex Technology" 169 "Marlin Technologies" 172 "Yanmar Marine" 174 "Volvo Penta" 176 "Carling Technologies Inc. (Moritz Aerospace)" 185 "Beede Instruments" 192 "Floscan Instrument" 193 "Nobeltec" 198 "Mystic Valley Communications" 199 "Actia" 201 "Disenos Y Technologia" 211 "Digital Switching Systems" 215 "Xintex/Atena" 224 "EMMI NETWORK" 228 "ZF" 229 "Garmin" 233 "Yacht Monitoring Solutions" 235 "Sailormade Marine Telemetry/Tetra Technology" 243 "Eride" 257 "Honda Motor" 272 "Groco" 273 "Actisense" 274 "Amphenol LTW Technology" 275 "Navico" 283 "Hamilton Jet" 285 "Sea Recovery" 286 "Coelmo SRL Italy" 295 "BEP Marine" 304 "Empir Bus" 305 "NovAtel" 306 "Sleipner Motor" 307 "MBW Technologies" 315 "ICOM" 328 "Qwerty" 329 "Dief" 341 "Boening Automationstechnologie" 345 "Korean Maritime University" 351 "Thrane and Thrane" 355 "Mastervolt" 356 "Fischer Panda Generators" 358 "Victron Energy" 370 "Rolls Royce Marine" 373 "Electronic Design" 374 "Northern Lights" 378 "Glendinning" 381 "B & G" 384 "Rose Point Navigation Systems" 385 "Johnson Outdoors Marine Electronics Inc Geonav" 394 "Capi 2" 396 "Beyond Measure" 400 "Livorsi Marine" 404 "ComNav" 409 "Chetco" 419 "Fusion Electronics" 421 "Standard Horizon" 422 "True Heading" 426 "Egersund Marine Electronics" 427 "em-trak Marine Electronics" 431 "Tohatsu Co, JP" 437 "Digital Yacht" 438 "Comar Systems Limited" 440 "Cummins" 443 "VDO (aka Continental-Corporation)" 451 "Parker Hannifin aka Village Marine Tech" 459 "Alltek Marine Electronics" 460 "SAN GIORGIO S.E.I.N" 466 "Veethree Electronics & Marine" 470 "SI-TEX Marine Electronics" 471 "Sea Cross Marine" 475 "GME aka Standard Communications" 476 "Humminbird Marine Electronics" 478 "Ocean Sat" 481 "Chetco Digital Instruments" 493 "Watcheye" 499 "Lcj Capteurs" 502 "Attwood Marine" 503 "Naviop S.R.L." 504 "Vesper Marine" 510 "Marinesoft" 513 "Simarine" 517 "NoLand Engineering" 518 "Transas USA" 529 "National Instruments Korea" 530 "National Marine Electronics Association" 532 "Onwa Marine" 540 "Webasto" 571 "Marinecraft (South Korea)" 573 "McMurdo Group aka Orolia" 578 "Advansea" 579 "KVH" 580 "San Jose Technology" 583 "Yacht Control" 586 "Suzuki Motor" 591 "US Coast Guard" 595 "Ship Module aka Customware" 600 "Aquatic AV" 605 "Aventics" 606 "Intellian" 612 "SamwonIT" 614 "Arlt Tecnologies" 637 "Bavaria Yachts" 641 "Diverse Yacht Services" 644 "Wema U.S.A dba KUS" 658 "Shenzhen Jiuzhou Himunication" 688 "Rockford" 699 "Harman International" 704 "JL Audio" 708 "Lars Thrane" 715 "Autonnic" 717 "Yacht Devices" 734 "REAP Systems" 735 "AEM Performance Electronics" 739 "LxNav" 741 "Littelfuse, Inc (formerly Carling Technologies)" 743 "DaeMyung" 744 "Woosung" 748 "ISOTTA IFRA srl" 773 "Clarion US" 776 "HMI Systems" 777 "Ocean Signal" 778 "Seakeeper" 781 "Poly Planar" 785 "Fischer Panda DE" 795 "Broyda Industries" 796 "Canadian Automotive" 797 "Tides Marine" 798 "Lumishore" 799 "Still Water Designs and Audio" 802 "BJ Technologies (Beneteau)" 803 "Gill Sensors" 811 "Blue Water Desalination" 815 "FLIR" 824 "Undheim Systems" 826 "Lewmar" 838 "TeamSurv" 844 "Fell Marine" 847 "Oceanvolt" 862 "Prospec" 868 "Data Panel" 890 "L3 Technologies" 894 "Rhodan Marine Systems" 896 "Nexfour Solutions" 905 "ASA Electronics" 909 "Marines Co (South Korea)" 911 "Nautic-on" 917 "Sentinel" 929 "JL Marine Systems" 930 "Ecotronix" 944 "Zontisa Marine" 951 "EXOR International" 962 "Timbolier Industries" 963 "TJC Micro" 968 "Cox Powertrain" 969 "Blue Seas" 981 "Kobelt Manufacturing" 992 "Blue Ocean IOT" 997 "Xenta Systems" 999 "Signal K" 1004 "Ultraflex" 1008 "Lintest SmartBoat" 1011 "Soundmax" 1020 "Team Italia Marine (Onyx Marine Automation s.r.l)" 1021 "Entratech" 1022 "ITC" 1029 "The Marine Guardian" 1047 "Sonic" 1051 "ProNav" 1053 "Vetus Maxwell INC." 1056 "Lithium Pros" 1059 "Boatrax" 1062 "Marol Co ltd" 1065 "CALYPSO Instruments" 1066 "Spot Zero Water" 1069 "Lithionics Battery" 1070 "Quick-teck Electronics" 1075 "Uniden America" 1083 "Nauticoncept" 1084 "Shadow-Caster LED lighting" 1085 "Wet Sounds" 1088 "E-T-A Circuit Breakers" 1092 "Scheiber" 1100 "Smart Yachts International Limited" 1109 "Dockmate" 1114 "Bobs Machine" 1118 "L3Harris ASV" 1119 "Balmar" 1120 "Elettromedia" 1127 "Electromaax" 1140 "Across Oceans Systems" 1145 "Kiwi Yachting" 1150 "BSB Artificial Intelligence" 1151 "Orca Technologies" 1154 "TBS Electronics" 1158 "Technoton Electroics" 1160 "MG Energy Systems" 1169 "Sea Machine Robotics" 1171 "Vista Manufacturing" 1183 "Zipwake" 1186 "Sailmon" 1192 "Airmoniq Pro Kft" 1194 "Sierra Marine" 1200 "Xinuo Information Technology (Xiamen)" 1218 "Septentrio" 1233 "NKE Marine Electronics" 1238 "SuperTrack Aps" 1239 "Honda Electronics" 1245 "Raritan Engineering" 1249 "Integrated Power Solutions AG" 1260 "Interactive Technologies" 1283 "LTG-Tech" 1299 "Energy Solutions (UK)" 1300 "WATT Fuel Cell" 1302 "Pro Mainer" 1305 "Dragonfly Energy" 1306 "Koden Electronics" 1311 "Humphree" 1316 "Hinkley Yachts" 1317 "Global Marine Management GmbH (GMM)" 1320 "Triskel Marine" 1330 "Warwick Control Technologies" 1331 "Dolphin Charger" 1337 "Barnacle Systems" 1348 "Radian IoT" 1353 "Ocean LED Marine" 1359 "BluNav" 1361 "OVA (Nantong Saiyang Electronics Co., Ltd)" 1368 "RAD Propulsion" 1369 "Electric Yacht" 1372 "Elco Motor Yachts" 1384 "Tecnoseal Foundry S.r.l" 1385 "Pro Charging Systems" 1389 "EVEX" 1398 "Gobius Sensor Technology" 1403 "Arco Marine" 1408 "Lenco Marine" 1413 "Naocontrol" 1417 "Revatek" 1438 "Aeolionics" 1439 "PredictWind" 1440 "Egis Mobile Electric" 1445 "Starboard Yacht Group" 1446 "Roswell Marine" 1451 "ePropulsion (Guangdong ePropulsion Technology Ltd.)" 1452 "Micro-Air" 1453 "Vital Battery" 1458 "Ride Controller" 1460 "Tocaro Blue" 1461 "Vanquish Yachts" 1471 "FT Technologies" 1478 "Alps Alpine" 1481 "E-Force Marine" 1482 "CMC Marine" 1483 "Nanjing Sandemarine Information Technology" 1850 "Teleflex Marine (SeaStar Solutions)" 1851 "Raymarine" 1852 "Navionics" 1853 "Japan Radio" 1854 "Northstar Technologies" 1855 "Furuno" 1856 "Trimble" 1857 "Simrad" 1858 "Litton" 1859 "Kvasar" 1860 "MMP" 1861 "Vector Cantech" 1862 "Yamaha Marine" 1863 "Faria Instruments" ;
VAL_ 2649686016 Industry_Code 0 "Global" 1 "Highway" 2 "Agriculture" 3 "Construction" 4 "Marine Industry" 5 "Industrial" ;
VAL_ 2649686016 Sub_protocol_ID 1900 "AHRS ATT transport" 5904 "Autopilot transport" ;
VAL_ 2649686016 Field 3 "Heartbeat" 10 "Mode State" 11 "Heading to Steer" 62 "Response Setting" 114 "Rate of Turn" 115 "Rate of Turn Order" 116 "Turn Angle Order" 158 "System Voltage" 161 "Turn Angle Measured" 239 "Engine RPM B" 240 "Engine RPM A" 246 "Speed" ;
VAL_ 2649686016 Manufacturer_Code 69 "ARKS Enterprises" 78 "FW Murphy/Enovation Controls" 80 "Twin Disc" 85 "Kohler Power Systems" 88 "Hemisphere GPS" 135 "Airmar" 137 "Maretron" 140 "Lowrance" 144 "Mercury Marine" 147 "Nautibus Electronic" 148 "Blue Water Data" 154 "Westerbeke" 157 "ISSPRO" 161 "Offshore Systems (UK)" 163 "Evinrude/BRP" 165 "CPAC Systems" 168 "Xantrex Technology" 169 "Marlin Technologies" 172 "Yanmar Marine" 174 "Volvo Penta" 176 "Carling Technologies Inc. (Moritz Aerospace)" 185 "Beede Instruments" 192 "Floscan Instrument" 193 "Nobeltec" 198 "Mystic Valley Communications" 199 "Actia" 201 "Disenos Y Technologia" 211 "Digital Switching Systems" 215 "Xintex/Atena" 224 "EMMI NETWORK" 228 "ZF" 229 "Garmin" 233 "Yacht Monitoring Solutions" 235 "Sailormade Marine Telemetry/Tetra Technology" 243 "Eride" 257 "Honda Motor" 272 "Groco" 273 "Actisense" 274 "Amphenol LTW Technology" 275 "Navico" 283 "Hamilton Jet" 285 "Sea Recovery" 286 "Coelmo SRL Italy" 295 "BEP Marine" 304 "Empir Bus" 305 "NovAtel" 306 "Sleipner Motor" 307 "MBW Technologies" 315 "ICOM" 328 "Qwerty" 329 "Dief" 341 "Boening Automationstechnologie" 345 "Korean Maritime University" 351 "Thrane and Thrane" 355 "Mastervolt" 356 "Fischer Panda Generators" 358 "Victron Energy" 370 "Rolls Royce Marine" 373 "Electronic Design" 374 "Northern Lights" 378 "Glendinning" 381 "B & G" 384 "Rose Point Navigation Systems" 385 "Johnson Outdoors Marine Electronics Inc Geonav" 394 "Capi 2" 396 "Beyond Measure" 400 "Livorsi Marine" 404 "ComNav" 409 "Chetco" 419 "Fusion Electronics" 421 "Standard Horizon" 422 "True Heading" 426 "Egersund Marine Electronics" 427 "em-trak Marine Electronics" 431 "Tohatsu Co, JP" 437 "Digital Yacht" 438 "Comar Systems Limited" 440 "Cummins" 443 "VDO (aka Continental-Corporation)" 451 "Parker Hannifin aka Village Marine Tech" 459 "Alltek Marine Electronics" 460 "SAN GIORGIO S.E.I.N" 466 "Veethree Electronics & Marine" 470 "SI-TEX Marine Electronics" 471 "Sea Cross Marine" 475 "GME aka Standard Communications" 476 "Humminbird Marine Electronics" 478 "Ocean Sat" 481 "Chetco Digital Instruments" 493 "Watcheye" 499 "Lcj Capteurs" 502 "Attwood Marine" 503 "Naviop S.R.L." 504 "Vesper Marine" 510 "Marinesoft" 513 "Simarine" 517 "NoLand Engineering" 518 "Transas USA" 529 "National Instruments Korea" 530 "National Marine Electronics Association" 532 "Onwa Marine" 540 "Webasto" 571 "Marinecraft (South Korea)" 573 "McMurdo Group aka Orolia" 578 "Advansea" 579 "KVH" 580 "San Jose Technology" 583 "Yacht Control" 586 "Suzuki Motor" 591 "US Coast Guard" 595 "Ship Module aka Customware" 600 "Aquatic AV" 605 "Aventics" 606 "Intellian" 612 "SamwonIT" 614 "Arlt Tecnologies" 637 "Bavaria Yachts" 641 "Diverse Yacht Services" 644 "Wema U.S.A dba KUS" 658 "Shenzhen Jiuzhou Himunication" 688 "Rockford" 699 "Harman International" 704 "JL Audio" 708 "Lars Thrane" 715 "Autonnic" 717 "Yacht Devices" 734 "REAP Systems" 735 "AEM Performance Electronics" 739 "LxNav" 741 "Littelfuse, Inc (formerly Carling Technologies)" 743 "DaeMyung" 744 "Woosung" 748 "ISOTTA IFRA srl" 773 "Clarion US" 776 "HMI Systems" 777 "Ocean Signal" 778 "Seakeeper" 781 "Poly Planar" 785 "Fischer Panda DE" 795 "Broyda Industries" 796 "Canadian Automotive" 797 "Tides Marine" 798 "Lumishore" 799 "Still Water Designs and Audio" 802 "BJ Technologies (Beneteau)" 803 "Gill Sensors" 811 "Blue Water Desalination" 815 "FLIR" 824 "Undheim Systems" 826 "Lewmar" 838 "TeamSurv" 844 "Fell Marine" 847 "Oceanvolt" 862 "Prospec" 868 "Data Panel" 890 "L3 Technologies" 894 "Rhodan Marine Systems" 896 "Nexfour Solutions" 905 "ASA Electronics" 909 "Marines Co (South Korea)" 911 "Nautic-on" 917 "Sentinel" 929 "JL Marine Systems" 930 "Ecotronix" 944 "Zontisa Marine" 951 "EXOR International" 962 "Timbolier Industries" 963 "TJC Micro" 968 "Cox Powertrain" 969 "Blue Seas" 981 "Kobelt Manufacturing" 992 "Blue Ocean IOT" 997 "Xenta Systems" 999 "Signal K" 1004 "Ultraflex" 1008 "Lintest SmartBoat" 1011 "Soundmax" 1020 "Team Italia Marine (Onyx Marine Automation s.r.l)" 1021 "Entratech" 1022 "ITC" 1029 "The Marine Guardian" 1047 "Sonic" 1051 "ProNav" 1053 "Vetus Maxwell INC." 1056 "Lithium Pros" 1059 "Boatrax" 1062 "Marol Co ltd" 1065 "CALYPSO Instruments" 1066 "Spot Zero Water" 1069 "Lithionics Battery" 1070 "Quick-teck Electronics" 1075 "Uniden America" 1083 "Nauticoncept" 1084 "Shadow-Caster LED lighting" 1085 "Wet Sounds" 1088 "E-T-A Circuit Breakers" 1092 "Scheiber" 1100 "Smart Yachts International Limited" 1109 "Dockmate" 1114 "Bobs Machine" 1118 "L3Harris ASV" 1119 "Balmar" 1120 "Elettromedia" 1127 "Electromaax" 1140 "Across Oceans Systems" 1145 "Kiwi Yachting" 1150 "BSB Artificial Intelligence" 1151 "Orca Technologies" 1154 "TBS Electronics" 1158 "Technoton Electroics" 1160 "MG Energy Systems" 1169 "Sea Machine Robotics" 1171 "Vista Manufacturing" 1183 "Zipwake" 1186 "Sailmon" 1192 "Airmoniq Pro Kft" 1194 "Sierra Marine" 1200 "Xinuo Information Technology (Xiamen)" 1218 "Septentrio" 1233 "NKE Marine Electronics" 1238 "SuperTrack Aps" 1239 "Honda Electronics" 1245 "Raritan Engineering" 1249 "Integrated Power Solutions AG" 1260 "Interactive Technologies" 1283 "LTG-Tech" 1299 "Energy Solutions (UK)" 1300 "WATT Fuel Cell" 1302 "Pro Mainer" 1305 "Dragonfly Energy" 1306 "Koden Electronics" 1311 "Humphree" 1316 "Hinkley Yachts" 1317 "Global Marine Management GmbH (GMM)" 1320 "Triskel Marine" 1330 "Warwick Control Technologies" 1331 "Dolphin Charger" 1337 "Barnacle Systems" 1348 "Radian IoT" 1353 "Ocean LED Marine" 1359 "BluNav" 1361 "OVA (Nantong Saiyang Electronics Co., Ltd)" 1368 "RAD Propulsion" 1369 "Electric Yacht" 1372 "Elco Motor Yachts" 1384 "Tecnoseal Foundry S.r.l" 1385 "Pro Charging Systems" 1389 "EVEX" 1398 "Gobius Sensor Technology" 1403 "Arco Marine" 1408 "Lenco Marine" 1413 "Naocontrol" 1417 "Revatek" 1438 "Aeolionics" 1439 "PredictWind" 1440 "Egis Mobile Electric" 1445 "Starboard Yacht Group" 1446 "Roswell Marine" 1451 "ePropulsion (Guangdong ePropulsion Technology Ltd.)" 1452 "Micro-Air" 1453 "Vital Battery" 1458 "Ride Controller" 1460 "Tocaro Blue" 1461 "Vanquish Yachts" 1471 "FT Technologies" 1478 "Alps Alpine" 1481 "E-Force Marine" 1482 "CMC Marine" 1483 "Nanjing Sandemarine Information Technology" 1850 "Teleflex Marine (SeaStar Solutions)" 1851 "Raymarine" 1852 "Navionics" 1853 "Japan Radio" 1854 "Northstar Technologies" 1855 "Furuno" 1856 "Trimble" 1857 "Simrad" 1858 "Litton" 1859 "Kvasar" 1860 "MMP" 1861 "Vector Cantech" 1862 "Yamaha Marine" 1863 "Faria Instruments" ;
VAL_ 2649686016 Industry_Code 0 "Global" 1 "Highway" 2 "Agriculture" 3 "Construction" 4 "Marine Industry" 5 "Industrial" ;
VAL_ 2649686016 Sub_protocol_ID 1900 "AHRS ATT transport" 5904 "Autopilot transport" ;
VAL_ 2649686016 Field 3 "Heartbeat" 10 "Mode State" 11 "Heading to Steer" 62 "Response Setting" 114 "Rate of Turn" 115 "Rate of Turn Order" 116 "Turn Angle Order" 158 "System Voltage" 161 "Turn Angle Measured" 239 "Engine RPM B" 240 "Engine RPM A" 246 "Speed" ;
VAL_ 2649686016 Manufacturer_Code 69 "ARKS Enterprises" 78 "FW Murphy/Enovation Controls" 80 "Twin Disc" 85 "Kohler Power Systems" 88 "Hemisphere GPS" 135 "Airmar" 137 "Maretron" 140 "Lowrance" 144 "Mercury Marine" 147 "Nautibus Electronic" 148 "Blue Water Data" 154 "Westerbeke" 157 "ISSPRO" 161 "Offshore Systems (UK)" 163 "Evinrude/BRP" 165 "CPAC Systems" 168 "Xantrex Technology" 169 "Marlin Technologies" 172 "Yanmar Marine" 174 "Volvo Penta" 176 "Carling Technologies Inc. (Moritz Aerospace)" 185 "Beede Instruments" 192 "Floscan Instrument" 193 "Nobeltec" 198 "Mystic Valley Communications" 199 "Actia" 201 "Disenos Y Technologia" 211 "Digital Switching Systems" 215 "Xintex/Atena" 224 "EMMI NETWORK" 228 "ZF" 229 "Garmin" 233 "Yacht Monitoring Solutions" 235 "Sailormade Marine Telemetry/Tetra Technology" 243 "Eride" 257 "Honda Motor" 272 "Groco" 273 "Actisense" 274 "Amphenol LTW Technology" 275 "Navico" 283 "Hamilton Jet" 285 "Sea Recovery" 286 "Coelmo SRL Italy" 295 "BEP Marine" 304 "Empir Bus" 305 "NovAtel" 306 "Sleipner Motor" 307 "MBW Technologies" 315 "ICOM" 328 "Qwerty" 329 "Dief" 341 "Boening Automationstechnologie" 345 "Korean Maritime University" 351 "Thrane and Thrane" 355 "Mastervolt" 356 "Fischer Panda Generators" 358 "Victron Energy" 370 "Rolls Royce Marine" 373 "Electronic Design" 374 "Northern Lights" 378 "Glendinning" 381 "B & G" 384 "Rose Point Navigation Systems" 385 "Johnson Outdoors Marine Electronics Inc Geonav" 394 "Capi 2" 396 "Beyond Measure" 400 "Livorsi Marine" 404 "ComNav" 409 "Chetco" 419 "Fusion Electronics" 421 "Standard Horizon" 422 "True Heading" 426 "Egersund Marine Electronics" 427 "em-trak Marine Electronics" 431 "Tohatsu Co, JP" 437 "Digital Yacht" 438 "Comar Systems Limited" 440 "Cummins" 443 "VDO (aka Continental-Corporation)" 451 "Parker Hannifin aka Village Marine Tech" 459 "Alltek Marine Electronics" 460 "SAN GIORGIO S.E.I.N" 466 "Veethree Electronics & Marine" 470 "SI-TEX Marine Electronics" 471 "Sea Cross Marine" 475 "GME aka Standard Communications" 476 "Humminbird Marine Electronics" 478 "Ocean Sat" 481 "Chetco Digital Instruments" 493 "Watcheye" 499 "Lcj Capteurs" 502 "Attwood Marine" 503 "Naviop S.R.L." 504 "Vesper Marine" 510 "Marinesoft" 513 "Simarine" 517 "NoLand Engineering" 518 "Transas USA" 529 "National Instruments Korea" 530 "National Marine Electronics Association" 532 "Onwa Marine" 540 "Webasto" 571 "Marinecraft (South Korea)" 573 "McMurdo Group aka Orolia" 578 "Advansea" 579 "KVH" 580 "San Jose Technology" 583 "Yacht Control" 586 "Suzuki Motor" 591 "US Coast Guard" 595 "Ship Module aka Customware" 600 "Aquatic AV" 605 "Aventics" 606 "Intellian" 612 "SamwonIT" 614 "Arlt Tecnologies" 637 "Bavaria Yachts" 641 "Diverse Yacht Services" 644 "Wema U.S.A dba KUS" 658 "Shenzhen Jiuzhou Himunication" 688 "Rockford" 699 "Harman International" 704 "JL Audio" 708 "Lars Thrane" 715 "Autonnic" 717 "Yacht Devices" 734 "REAP Systems" 735 "AEM Performance Electronics" 739 "LxNav" 741 "Littelfuse, Inc (formerly Carling Technologies)" 743 "DaeMyung" 744 "Woosung" 748 "ISOTTA IFRA srl" 773 "Clarion US" 776 "HMI Systems" 777 "Ocean Signal" 778 "Seakeeper" 781 "Poly Planar" 785 "Fischer Panda DE" 795 "Broyda Industries" 796 "Canadian Automotive" 797 "Tides Marine" 798 "Lumishore" 799 "Still Water Designs and Audio" 802 "BJ Technologies (Beneteau)" 803 "Gill Sensors" 811 "Blue Water Desalination" 815 "FLIR" 824 "Undheim Systems" 826 "Lewmar" 838 "TeamSurv" 844 "Fell Marine" 847 "Oceanvolt" 862 "Prospec" 868 "Data Panel" 890 "L3 Technologies" 894 "Rhodan Marine Systems" 896 "Nexfour Solutions" 905 "ASA Electronics" 909 "Marines Co (South Korea)" 911 "Nautic-on" 917 "Sentinel" 929 "JL Marine Systems" 930 "Ecotronix" 944 "Zontisa Marine" 951 "EXOR International" 962 "Timbolier Industries" 963 "TJC Micro" 968 "Cox Powertrain" 969 "Blue Seas" 981 "Kobelt Manufacturing" 992 "Blue Ocean IOT" 997 "Xenta Systems" 999 "Signal K" 1004 "Ultraflex" 1008 "Lintest SmartBoat" 1011 "Soundmax" 1020 "Team Italia Marine (Onyx Marine Automation s.r.l)" 1021 "Entratech" 1022 "ITC" 1029 "The Marine Guardian" 1047 "Sonic" 1051 "ProNav" 1053 "Vetus Maxwell INC." 1056 "Lithium Pros" 1059 "Boatrax" 1062 "Marol Co ltd" 1065 "CALYPSO Instruments" 1066 "Spot Zero Water" 1069 "Lithionics Battery" 1070 "Quick-teck Electronics" 1075 "Uniden America" 1083 "Nauticoncept" 1084 "Shadow-Caster LED lighting" 1085 "Wet Sounds" 1088 "E-T-A Circuit Breakers" 1092 "Scheiber" 1100 "Smart Yachts International Limited" 1109 "Dockmate" 1114 "Bobs Machine" 1118 "L3Harris ASV" 1119 "Balmar" 1120 "Elettromedia" 1127 "Electromaax" 1140 "Across Oceans Systems" 1145 "Kiwi Yachting" 1150 "BSB Artificial Intelligence" 1151 "Orca Technologies" 1154 "TBS Electronics" 1158 "Technoton Electroics" 1160 "MG Energy Systems" 1169 "Sea Machine Robotics" 1171 "Vista Manufacturing" 1183 "Zipwake" 1186 "Sailmon" 1192 "Airmoniq Pro Kft" 1194 "Sierra Marine" 1200 "Xinuo Information Technology (Xiamen)" 1218 "Septentrio" 1233 "NKE Marine Electronics" 1238 "SuperTrack Aps" 1239 "Honda Electronics" 1245 "Raritan Engineering" 1249 "Integrated Power Solutions AG" 1260 "Interactive Technologies" 1283 "LTG-Tech" 1299 "Energy Solutions (UK)" 1300 "WATT Fuel Cell" 1302 "Pro Mainer" 1305 "Dragonfly Energy" 1306 "Koden Electronics" 1311 "Humphree" 1316 "Hinkley Yachts" 1317 "Global Marine Management GmbH (GMM)" 1320 "Triskel Marine" 1330 "Warwick Control Technologies" 1331 "Dolphin Charger" 1337 "Barnacle Systems" 1348 "Radian IoT" 1353 "Ocean LED Marine" 1359 "BluNav" 1361 "OVA (Nantong Saiyang Electronics Co., Ltd)" 1368 "RAD Propulsion" 1369 "Electric Yacht" 1372 "Elco Motor Yachts" 1384 "Tecnoseal Foundry S.r.l" 1385 "Pro Charging Systems" 1389 "EVEX" 1398 "Gobius Sensor Technology" 1403 "Arco Marine" 1408 "Lenco Marine" 1413 "Naocontrol" 1417 "Revatek" 1438 "Aeolionics" 1439 "PredictWind" 1440 "Egis Mobile Electric" 1445 "Starboard Yacht Group" 1446 "Roswell Marine" 1451 "ePropulsion (Guangdong ePropulsion Technology Ltd.)" 1452 "Micro-Air" 1453 "Vital Battery" 1458 "Ride Controller" 1460 "Tocaro Blue" 1461 "Vanquish Yachts" 1471 "FT Technologies" 1478 "Alps Alpine" 1481 "E-Force Marine" 1482 "CMC Marine" 1483 "Nanjing Sandemarine Information Technology" 1850 "Teleflex Marine (SeaStar Solutions)" 1851 "Raymarine" 1852 "Navionics" 1853 "Japan Radio" 1854 "Northstar Technologies" 1855 "Furuno" 1856 "Trimble" 1857 "Simrad" 1858 "Litton" 1859 "Kvasar" 1860 "MMP" 1861 "Vector Cantech" 1862 "Yamaha Marine" 1863 "Faria Instruments" ;
VAL_ 2649686016 Industry_Code 0 "Global" 1 "Highway" 2 "Agriculture" 3 "Construction" 4 "Marine Industry" 5 "Industrial" ;
VAL_ 2649686016 Sub_protocol_ID 1900 "AHRS ATT transport" 5904 "Autopilot transport" ;
VAL_ 2649686016 Field 3 "Heartbeat" 10 "Mode State" 11 "Heading to Steer" 62 "Response Setting" 114 "Rate of Turn" 115 "Rate of Turn Order" 116 "Turn Angle Order" 158 "System Voltage" 161 "Turn Angle Measured" 239 "Engine RPM B" 240 "Engine RPM A" 246 "Speed" ;
VAL_ 2649686016 Manufacturer_Code 69 "ARKS Enterprises" 78 "FW Murphy/Enovation Controls" 80 "Twin Disc" 85 "Kohler Power Systems" 88 "Hemisphere GPS" 135 "Airmar" 137 "Maretron" 140 "Lowrance" 144 "Mercury Marine" 147 "Nautibus Electronic" 148 "Blue Water Data" 154 "Westerbeke" 157 "ISSPRO" 161 "Offshore Systems (UK)" 163 "Evinrude/BRP" 165 "CPAC Systems" 168 "Xantrex Technology" 169 "Marlin Technologies" 172 "Yanmar Marine" 174 "Volvo Penta" 176 "Carling Technologies Inc. (Moritz Aerospace)" 185 "Beede Instruments" 192 "Floscan Instrument" 193 "Nobeltec" 198 "Mystic Valley Communications" 199 "Actia" 201 "Disenos Y Technologia" 211 "Digital Switching Systems" 215 "Xintex/Atena" 224 "EMMI NETWORK" 228 "ZF" 229 "Garmin" 233 "Yacht Monitoring Solutions" 235 "Sailormade Marine Telemetry/Tetra Technology" 243 "Eride" 257 "Honda Motor" 272 "Groco" 273 "Actisense" 274 "Amphenol LTW Technology" 275 "Navico" 283 "Hamilton Jet" 285 "Sea Recovery" 286 "Coelmo SRL Italy" 295 "BEP Marine" 304 "Empir Bus" 305 "NovAtel" 306 "Sleipner Motor" 307 "MBW Technologies" 315 "ICOM" 328 "Qwerty" 329 "Dief" 341 "Boening Automationstechnologie" 345 "Korean Maritime University" 351 "Thrane and Thrane" 355 "Mastervolt" 356 "Fischer Panda Generators" 358 "Victron Energy" 370 "Rolls Royce Marine" 373 "Electronic Design" 374 "Northern Lights" 378 "Glendinning" 381 "B & G" 384 "Rose Point Navigation Systems" 385 "Johnson Outdoors Marine Electronics Inc Geonav" 394 "Capi 2" 396 "Beyond Measure" 400 "Livorsi Marine" 404 "ComNav" 409 "Chetco" 419 "Fusion Electronics" 421 "Standard Horizon" 422 "True Heading" 426 "Egersund Marine Electronics" 427 "em-trak Marine Electronics" 431 "Tohatsu Co, JP" 437 "Digital Yacht" 438 "Comar Systems Limited" 440 "Cummins" 443 "VDO (aka Continental-Corporation)" 451 "Parker Hannifin aka Village Marine Tech" 459 "Alltek Marine Electronics" 460 "SAN GIORGIO S.E.I.N" 466 "Veethree Electronics & Marine" 470 "SI-TEX Marine Electronics" 471 "Sea Cross Marine" 475 "GME aka Standard Communications" 476 "Humminbird Marine Electronics" 478 "Ocean Sat" 481 "Chetco Digital Instruments" 493 "Watcheye" 499 "Lcj Capteurs" 502 "Attwood Marine" 503 "Naviop S.R.L." 504 "Vesper Marine" 510 "Marinesoft" 513 "Simarine" 517 "NoLand Engineering" 518 "Transas USA" 529 "National Instruments Korea" 530 "National Marine Electronics Association" 532 "Onwa Marine" 540 "Webasto" 571 "Marinecraft (South Korea)" 573 "McMurdo Group aka Orolia" 578 "Advansea" 579 "KVH" 580 "San Jose Technology" 583 "Yacht Control" 586 "Suzuki Motor" 591 "US Coast Guard" 595 "Ship Module aka Customware" 600 "Aquatic AV" 605 "Aventics" 606 "Intellian" 612 "SamwonIT" 614 "Arlt Tecnologies" 637 "Bavaria Yachts" 641 "Diverse Yacht Services" 644 "Wema U.S.A dba KUS" 658 "Shenzhen Jiuzhou Himunication" 688 "Rockford" 699 "Harman International" 704 "JL Audio" 708 "Lars Thrane" 715 "Autonnic" 717 "Yacht Devices" 734 "REAP Systems" 735 "AEM Performance Electronics" 739 "LxNav" 741 "Littelfuse, Inc (formerly Carling Technologies)" 743 "DaeMyung" 744 "Woosung" 748 "ISOTTA IFRA srl" 773 "Clarion US" 776 "HMI Systems" 777 "Ocean Signal" 778 "Seakeeper" 781 "Poly Planar" 785 "Fischer Panda DE" 795 "Broyda Industries" 796 "Canadian Automotive" 797 "Tides Marine" 798 "Lumishore" 799 "Still Water Designs and Audio" 802 "BJ Technologies (Beneteau)" 803 "Gill Sensors" 811 "Blue Water Desalination" 815 "FLIR" 824 "Undheim Systems" 826 "Lewmar" 838 "TeamSurv" 844 "Fell Marine" 847 "Oceanvolt" 862 "Prospec" 868 "Data Panel" 890 "L3 Technologies" 894 "Rhodan Marine Systems" 896 "Nexfour Solutions" 905 "ASA Electronics" 909 "Marines Co (South Korea)" 911 "Nautic-on" 917 "Sentinel" 929 "JL Marine Systems" 930 "Ecotronix" 944 "Zontisa Marine" 951 "EXOR International" 962 "Timbolier Industries" 963 "TJC Micro" 968 "Cox Powertrain" 969 "Blue Seas" 981 "Kobelt Manufacturing" 992 "Blue Ocean IOT" 997 "Xenta Systems" 999 "Signal K" 1004 "Ultraflex" 1008 "Lintest SmartBoat" 1011 "Soundmax" 1020 "Team Italia Marine (Onyx Marine Automation s.r.l)" 1021 "Entratech" 1022 "ITC" 1029 "The Marine Guardian" 1047 "Sonic" 1051 "ProNav" 1053 "Vetus Maxwell INC." 1056 "Lithium Pros" 1059 "Boatrax" 1062 "Marol Co ltd" 1065 "CALYPSO Instruments" 1066 "Spot Zero Water" 1069 "Lithionics Battery" 1070 "Quick-teck Electronics" 1075 "Uniden America" 1083 "Nauticoncept" 1084 "Shadow-Caster LED lighting" 1085 "Wet Sounds" 1088 "E-T-A Circuit Breakers" 1092 "Scheiber" 1100 "Smart Yachts International Limited" 1109 "Dockmate" 1114 "Bobs Machine" 1118 "L3Harris ASV" 1119 "Balmar" 1120 "Elettromedia" 1127 "Electromaax" 1140 "Across Oceans Systems" 1145 "Kiwi Yachting" 1150 "BSB Artificial Intelligence" 1151 "Orca Technologies" 1154 "TBS Electronics" 1158 "Technoton Electroics" 1160 "MG Energy Systems" 1169 "Sea Machine Robotics" 1171 "Vista Manufacturing" 1183 "Zipwake" 1186 "Sailmon" 1192 "Airmoniq Pro Kft" 1194 "Sierra Marine" 1200 "Xinuo Information Technology (Xiamen)" 1218 "Septentrio" 1233 "NKE Marine Electronics" 1238 "SuperTrack Aps" 1239 "Honda Electronics" 1245 "Raritan Engineering" 1249 "Integrated Power Solutions AG" 1260 "Interactive Technologies" 1283 "LTG-Tech" 1299 "Energy Solutions (UK)" 1300 "WATT Fuel Cell" 1302 "Pro Mainer" 1305 "Dragonfly Energy" 1306 "Koden Electronics" 1311 "Humphree" 1316 "Hinkley Yachts" 1317 "Global Marine Management GmbH (GMM)" 1320 "Triskel Marine" 1330 "Warwick Control Technologies" 1331 "Dolphin Charger" 1337 "Barnacle Systems" 1348 "Radian IoT" 1353 "Ocean LED Marine" 1359 "BluNav" 1361 "OVA (Nantong Saiyang Electronics Co., Ltd)" 1368 "RAD Propulsion" 1369 "Electric Yacht" 1372 "Elco Motor Yachts" 1384 "Tecnoseal Foundry S.r.l" 1385 "Pro Charging Systems" 1389 "EVEX" 1398 "Gobius Sensor Technology" 1403 "Arco Marine" 1408 "Lenco Marine" 1413 "Naocontrol" 1417 "Revatek" 1438 "Aeolionics" 1439 "PredictWind" 1440 "Egis Mobile Electric" 1445 "Starboard Yacht Group" 1446 "Roswell Marine" 1451 "ePropulsion (Guangdong ePropulsion Technology Ltd.)" 1452 "Micro-Air" 1453 "Vital Battery" 1458 "Ride Controller" 1460 "Tocaro Blue" 1461 "Vanquish Yachts" 1471 "FT Technologies" 1478 "Alps Alpine" 1481 "E-Force Marine" 1482 "CMC Marine" 1483 "Nanjing Sandemarine Information Technology" 1850 "Teleflex Marine (SeaStar Solutions)" 1851 "Raymarine" 1852 "Navionics" 1853 "Japan Radio" 1854 "Northstar Technologies" 1855 "Furuno" 1856 "Trimble" 1857 "Simrad" 1858 "Litton" 1859 "Kvasar" 1860 "MMP" 1861 "Vector Cantech" 1862 "Yamaha Marine" 1863 "Faria Instruments" ;
VAL_ 2649686016 Industry_Code 0 "Global" 1 "Highway" 2 "Agriculture" 3 "Construction" 4 "Marine Industry" 5 "Industrial" ;
VAL_ 2649686016 Sub_protocol_ID 1900 "AHRS ATT transport" 5904 "Autopilot transport" ;
VAL_ 2649686016 Field 3 "Heartbeat" 10 "Mode State" 11 "Heading to Steer" 62 "Response Setting" 114 "Rate of Turn" 115 "Rate of Turn Order" 116 "Turn Angle Order" 158 "System Voltage" 161 "Turn Angle Measured" 239 "Engine RPM B" 240 "Engine RPM A" 246 "Speed" ;
VAL_ 2649686016 Manufacturer_Code 69 "ARKS Enterprises" 78 "FW Murphy/Enovation Controls" 80 "Twin Disc" 85 "Kohler Power Systems" 88 "Hemisphere GPS" 135 "Airmar" 137 "Maretron" 140 "Lowrance" 144 "Mercury Marine" 147 "Nautibus Electronic" 148 "Blue Water Data" 154 "Westerbeke" 157 "ISSPRO" 161 "Offshore Systems (UK)" 163 "Evinrude/BRP" 165 "CPAC Systems" 168 "Xantrex Technology" 169 "Marlin Technologies" 172 "Yanmar Marine" 174 "Volvo Penta" 176 "Carling Technologies Inc. (Moritz Aerospace)" 185 "Beede Instruments" 192 "Floscan Instrument" 193 "Nobeltec" 198 "Mystic Valley Communications" 199 "Actia" 201 "Disenos Y Technologia" 211 "Digital Switching Systems" 215 "Xintex/Atena" 224 "EMMI NETWORK" 228 "ZF" 229 "Garmin" 233 "Yacht Monitoring Solutions" 235 "Sailormade Marine Telemetry/Tetra Technology" 243 "Eride" 257 "Honda Motor" 272 "Groco" 273 "Actisense" 274 "Amphenol LTW Technology" 275 "Navico" 283 "Hamilton Jet" 285 "Sea Recovery" 286 "Coelmo SRL Italy" 295 "BEP Marine" 304 "Empir Bus" 305 "NovAtel" 306 "Sleipner Motor" 307 "MBW Technologies" 315 "ICOM" 328 "Qwerty" 329 "Dief" 341 "Boening Automationstechnologie" 345 "Korean Maritime University" 351 "Thrane and Thrane" 355 "Mastervolt" 356 "Fischer Panda Generators" 358 "Victron Energy" 370 "Rolls Royce Marine" 373 "Electronic Design" 374 "Northern Lights" 378 "Glendinning" 381 "B & G" 384 "Rose Point Navigation Systems" 385 "Johnson Outdoors Marine Electronics Inc Geonav" 394 "Capi 2" 396 "Beyond Measure" 400 "Livorsi Marine" 404 "ComNav" 409 "Chetco" 419 "Fusion Electronics" 421 "Standard Horizon" 422 "True Heading" 426 "Egersund Marine Electronics" 427 "em-trak Marine Electronics" 431 "Tohatsu Co, JP" 437 "Digital Yacht" 438 "Comar Systems Limited" 440 "Cummins" 443 "VDO (aka Continental-Corporation)" 451 "Parker Hannifin aka Village Marine Tech" 459 "Alltek Marine Electronics" 460 "SAN GIORGIO S.E.I.N" 466 "Veethree Electronics & Marine" 470 "SI-TEX Marine Electronics" 471 "Sea Cross Marine" 475 "GME aka Standard Communications" 476 "Humminbird Marine Electronics" 478 "Ocean Sat" 481 "Chetco Digital Instruments" 493 "Watcheye" 499 "Lcj Capteurs" 502 "Attwood Marine" 503 "Naviop S.R.L." 504 "Vesper Marine" 510 "Marinesoft" 513 "Simarine" 517 "NoLand Engineering" 518 "Transas USA" 529 "National Instruments Korea" 530 "National Marine Electronics Association" 532 "Onwa Marine" 540 "Webasto" 571 "Marinecraft (South Korea)" 573 "McMurdo Group aka Orolia" 578 "Advansea" 579 "KVH" 580 "San Jose Technology" 583 "Yacht Control" 586 "Suzuki Motor" 591 "US Coast Guard" 595 "Ship Module aka Customware" 600 "Aquatic AV" 605 "Aventics" 606 "Intellian" 612 "SamwonIT" 614 "Arlt Tecnologies" 637 "Bavaria Yachts" 641 "Diverse Yacht Services" 644 "Wema U.S.A dba KUS" 658 "Shenzhen Jiuzhou Himunication" 688 "Rockford" 699 "Harman International" 704 "JL Audio" 708 "Lars Thrane" 715 "Autonnic" 717 "Yacht Devices" 734 "REAP Systems" 735 "AEM Performance Electronics" 739 "LxNav" 741 "Littelfuse, Inc (formerly Carling Technologies)" 743 "DaeMyung" 744 "Woosung" 748 "ISOTTA IFRA srl" 773 "Clarion US" 776 "HMI Systems" 777 "Ocean Signal" 778 "Seakeeper" 781 "Poly Planar" 785 "Fischer Panda DE" 795 "Broyda Industries" 796 "Canadian Automotive" 797 "Tides Marine" 798 "Lumishore" 799 "Still Water Designs and Audio" 802 "BJ Technologies (Beneteau)" 803 "Gill Sensors" 811 "Blue Water Desalination" 815 "FLIR" 824 "Undheim Systems" 826 "Lewmar" 838 "TeamSurv" 844 "Fell Marine" 847 "Oceanvolt" 862 "Prospec" 868 "Data Panel" 890 "L3 Technologies" 894 "Rhodan Marine Systems" 896 "Nexfour Solutions" 905 "ASA Electronics" 909 "Marines Co (South Korea)" 911 "Nautic-on" 917 "Sentinel" 929 "JL Marine Systems" 930 "Ecotronix" 944 "Zontisa Marine" 951 "EXOR International" 962 "Timbolier Industries" 963 "TJC Micro" 968 "Cox Powertrain" 969 "Blue Seas" 981 "Kobelt Manufacturing" 992 "Blue Ocean IOT" 997 "Xenta Systems" 999 "Signal K" 1004 "Ultraflex" 1008 "Lintest SmartBoat" 1011 "Soundmax" 1020 "Team Italia Marine (Onyx Marine Automation s.r.l)" 1021 "Entratech" 1022 "ITC" 1029 "The Marine Guardian" 1047 "Sonic" 1051 "ProNav" 1053 "Vetus Maxwell INC." 1056 "Lithium Pros" 1059 "Boatrax" 1062 "Marol Co ltd" 1065 "CALYPSO Instruments" 1066 "Spot Zero Water" 1069 "Lithionics Battery" 1070 "Quick-teck Electronics" 1075 "Uniden America" 1083 "Nauticoncept" 1084 "Shadow-Caster LED lighting" 1085 "Wet Sounds" 1088 "E-T-A Circuit Breakers" 1092 "Scheiber" 1100 "Smart Yachts International Limited" 1109 "Dockmate" 1114 "Bobs Machine" 1118 "L3Harris ASV" 1119 "Balmar" 1120 "Elettromedia" 1127 "Electromaax" 1140 "Across Oceans Systems" 1145 "Kiwi Yachting" 1150 "BSB Artificial Intelligence" 1151 "Orca Technologies" 1154 "TBS Electronics" 1158 "Technoton Electroics" 1160 "MG Energy Systems" 1169 "Sea Machine Robotics" 1171 "Vista Manufacturing" 1183 "Zipwake" 1186 "Sailmon" 1192 "Airmoniq Pro Kft" 1194 "Sierra Marine" 1200 "Xinuo Information Technology (Xiamen)" 1218 "Septentrio" 1233 "NKE Marine Electronics" 1238 "SuperTrack Aps" 1239 "Honda Electronics" 1245 "Raritan Engineering" 1249 "Integrated Power Solutions AG" 1260 "Interactive Technologies" 1283 "LTG-Tech" 1299 "Energy Solutions (UK)" 1300 "WATT Fuel Cell" 1302 "Pro Mainer" 1305 "Dragonfly Energy" 1306 "Koden Electronics" 1311 "Humphree" 1316 "Hinkley Yachts" 1317 "Global Marine Management GmbH (GMM)" 1320 "Triskel Marine" 1330 "Warwick Control Technologies" 1331 "Dolphin Charger" 1337 "Barnacle Systems" 1348 "Radian IoT" 1353 "Ocean LED Marine" 1359 "BluNav" 1361 "OVA (Nantong Saiyang Electronics Co., Ltd)" 1368 "RAD Propulsion" 1369 "Electric Yacht" 1372 "Elco Motor Yachts" 1384 "Tecnoseal Foundry S.r.l" 1385 "Pro Charging Systems" 1389 "EVEX" 1398 "Gobius Sensor Technology" 1403 "Arco Marine" 1408 "Lenco Marine" 1413 "Naocontrol" 1417 "Revatek" 1438 "Aeolionics" 1439 "PredictWind" 1440 "Egis Mobile Electric" 1445 "Starboard Yacht Group" 1446 "Roswell Marine" 1451 "ePropulsion (Guangdong ePropulsion Technology Ltd.)" 1452 "Micro-Air" 1453 "Vital Battery" 1458 "Ride Controller" 1460 "Tocaro Blue" 1461 "Vanquish Yachts" 1471 "FT Technologies" 1478 "Alps Alpine" 1481 "E-Force Marine" 1482 "CMC Marine" 1483 "Nanjing Sandemarine Information Technology" 1850 "Teleflex Marine (SeaStar Solutions)" 1851 "Raymarine" 1852 "Navionics" 1853 "Japan Radio" 1854 "Northstar Technologies" 1855 "Furuno" 1856 "Trimble" 1857 "Simrad" 1858 "Litton" 1859 "Kvasar" 1860 "MMP" 1861 "Vector Cantech" 1862 "Yamaha Marine" 1863 "Faria Instruments" ;
VAL_ 2649686016 Industry_Code 0 "Global" 1 "Highway" 2 "Agriculture" 3 "Construction" 4 "Marine Industry" 5 "Industrial" ;
VAL_ 2649686016 Sub_protocol_ID 1900 "AHRS ATT transport" 5904 "Autopilot transport" ;
VAL_ 2649686016 Maneuver_Code 0 "Decrease Heading 1 Degree" 1 "Decrease Heading 10 Degrees" 2 "Increase Heading 1 Degree" 3 "Increase Heading 10 Degrees" ;
VAL_ 2649686016 Manufacturer_Code 69 "ARKS Enterprises" 78 "FW Murphy/Enovation Controls" 80 "Twin Disc" 85 "Kohler Power Systems" 88 "Hemisphere GPS" 135 "Airmar" 137 "Maretron" 140 "Lowrance" 144 "Mercury Marine" 147 "Nautibus Electronic" 148 "Blue Water Data" 154 "Westerbeke" 157 "ISSPRO" 161 "Offshore Systems (UK)" 163 "Evinrude/BRP" 165 "CPAC Systems" 168 "Xantrex Technology" 169 "Marlin Technologies" 172 "Yanmar Marine" 174 "Volvo Penta" 176 "Carling Technologies Inc. (Moritz Aerospace)" 185 "Beede Instruments" 192 "Floscan Instrument" 193 "Nobeltec" 198 "Mystic Valley Communications" 199 "Actia" 201 "Disenos Y Technologia" 211 "Digital Switching Systems" 215 "Xintex/Atena" 224 "EMMI NETWORK" 228 "ZF" 229 "Garmin" 233 "Yacht Monitoring Solutions" 235 "Sailormade Marine Telemetry/Tetra Technology" 243 "Eride" 257 "Honda Motor" 272 "Groco" 273 "Actisense" 274 "Amphenol LTW Technology" 275 "Navico" 283 "Hamilton Jet" 285 "Sea Recovery" 286 "Coelmo SRL Italy" 295 "BEP Marine" 304 "Empir Bus" 305 "NovAtel" 306 "Sleipner Motor" 307 "MBW Technologies" 315 "ICOM" 328 "Qwerty" 329 "Dief" 341 "Boening Automationstechnologie" 345 "Korean Maritime University" 351 "Thrane and Thrane" 355 "Mastervolt" 356 "Fischer Panda Generators" 358 "Victron Energy" 370 "Rolls Royce Marine" 373 "Electronic Design" 374 "Northern Lights" 378 "Glendinning" 381 "B & G" 384 "Rose Point Navigation Systems" 385 "Johnson Outdoors Marine Electronics Inc Geonav" 394 "Capi 2" 396 "Beyond Measure" 400 "Livorsi Marine" 404 "ComNav" 409 "Chetco" 419 "Fusion Electronics" 421 "Standard Horizon" 422 "True Heading" 426 "Egersund Marine Electronics" 427 "em-trak Marine Electronics" 431 "Tohatsu Co, JP" 437 "Digital Yacht" 438 "Comar Systems Limited" 440 "Cummins" 443 "VDO (aka Continental-Corporation)" 451 "Parker Hannifin aka Village Marine Tech" 459 "Alltek Marine Electronics" 460 "SAN GIORGIO S.E.I.N" 466 "Veethree Electronics & Marine" 470 "SI-TEX Marine Electronics" 471 "Sea Cross Marine" 475 "GME aka Standard Communications" 476 "Humminbird Marine Electronics" 478 "Ocean Sat" 481 "Chetco Digital Instruments" 493 "Watcheye" 499 "Lcj Capteurs" 502 "Attwood Marine" 503 "Naviop S.R.L." 504 "Vesper Marine" 510 "Marinesoft" 513 "Simarine" 517 "NoLand Engineering" 518 "Transas USA" 529 "National Instruments Korea" 530 "National Marine Electronics Association" 532 "Onwa Marine" 540 "Webasto" 571 "Marinecraft (South Korea)" 573 "McMurdo Group aka Orolia" 578 "Advansea" 579 "KVH" 580 "San Jose Technology" 583 "Yacht Control" 586 "Suzuki Motor" 591 "US Coast Guard" 595 "Ship Module aka Customware" 600 "Aquatic AV" 605 "Aventics" 606 "Intellian" 612 "SamwonIT" 614 "Arlt Tecnologies" 637 "Bavaria Yachts" 641 "Diverse Yacht Services" 644 "Wema U.S.A dba KUS" 658 "Shenzhen Jiuzhou Himunication" 688 "Rockford" 699 "Harman International" 704 "JL Audio" 708 "Lars Thrane" 715 "Autonnic" 717 "Yacht Devices" 734 "REAP Systems" 735 "AEM Performance Electronics" 739 "LxNav" 741 "Littelfuse, Inc (formerly Carling Technologies)" 743 "DaeMyung" 744 "Woosung" 748 "ISOTTA IFRA srl" 773 "Clarion US" 776 "HMI Systems" 777 "Ocean Signal" 778 "Seakeeper" 781 "Poly Planar" 785 "Fischer Panda DE" 795 "Broyda Industries" 796 "Canadian Automotive" 797 "Tides Marine" 798 "Lumishore" 799 "Still Water Designs and Audio" 802 "BJ Technologies (Beneteau)" 803 "Gill Sensors" 811 "Blue Water Desalination" 815 "FLIR" 824 "Undheim Systems" 826 "Lewmar" 838 "TeamSurv" 844 "Fell Marine" 847 "Oceanvolt" 862 "Prospec" 868 "Data Panel" 890 "L3 Technologies" 894 "Rhodan Marine Systems" 896 "Nexfour Solutions" 905 "ASA Electronics" 909 "Marines Co (South Korea)" 911 "Nautic-on" 917 "Sentinel" 929 "JL Marine Systems" 930 "Ecotronix" 944 "Zontisa Marine" 951 "EXOR International" 962 "Timbolier Industries" 963 "TJC Micro" 968 "Cox Powertrain" 969 "Blue Seas" 981 "Kobelt Manufacturing" 992 "Blue Ocean IOT" 997 "Xenta Systems" 999 "Signal K" 1004 "Ultraflex" 1008 "Lintest SmartBoat" 1011 "Soundmax" 1020 "Team Italia Marine (Onyx Marine Automation s.r.l)" 1021 "Entratech" 1022 "ITC" 1029 "The Marine Guardian" 1047 "Sonic" 1051 "ProNav" 1053 "Vetus Maxwell INC." 1056 "Lithium Pros" 1059 "Boatrax" 1062 "Marol Co ltd" 1065 "CALYPSO Instruments" 1066 "Spot Zero Water" 1069 "Lithionics Battery" 1070 "Quick-teck Electronics" 1075 "Uniden America" 1083 "Nauticoncept" 1084 "Shadow-Caster LED lighting" 1085 "Wet Sounds" 1088 "E-T-A Circuit Breakers" 1092 "Scheiber" 1100 "Smart Yachts International Limited" 1109 "Dockmate" 1114 "Bobs Machine" 1118 "L3Harris ASV" 1119 "Balmar" 1120 "Elettromedia" 1127 "Electromaax" 1140 "Across Oceans Systems" 1145 "Kiwi Yachting" 1150 "BSB Artificial Intelligence" 1151 "Orca Technologies" 1154 "TBS Electronics" 1158 "Technoton Electroics" 1160 "MG Energy Systems" 1169 "Sea Machine Robotics" 1171 "Vista Manufacturing" 1183 "Zipwake" 1186 "Sailmon" 1192 "Airmoniq Pro Kft" 1194 "Sierra Marine" 1200 "Xinuo Information Technology (Xiamen)" 1218 "Septentrio" 1233 "NKE Marine Electronics" 1238 "SuperTrack Aps" 1239 "Honda Electronics" 1245 "Raritan Engineering" 1249 "Integrated Power Solutions AG" 1260 "Interactive Technologies" 1283 "LTG-Tech" 1299 "Energy Solutions (UK)" 1300 "WATT Fuel Cell" 1302 "Pro Mainer" 1305 "Dragonfly Energy" 1306 "Koden Electronics" 1311 "Humphree" 1316 "Hinkley Yachts" 1317 "Global Marine Management GmbH (GMM)" 1320 "Triskel Marine" 1330 "Warwick Control Technologies" 1331 "Dolphin Charger" 1337 "Barnacle Systems" 1348 "Radian IoT" 1353 "Ocean LED Marine" 1359 "BluNav" 1361 "OVA (Nantong Saiyang Electronics Co., Ltd)" 1368 "RAD Propulsion" 1369 "Electric Yacht" 1372 "Elco Motor Yachts" 1384 "Tecnoseal Foundry S.r.l" 1385 "Pro Charging Systems" 1389 "EVEX" 1398 "Gobius Sensor Technology" 1403 "Arco Marine" 1408 "Lenco Marine" 1413 "Naocontrol" 1417 "Revatek" 1438 "Aeolionics" 1439 "PredictWind" 1440 "Egis Mobile Electric" 1445 "Starboard Yacht Group" 1446 "Roswell Marine" 1451 "ePropulsion (Guangdong ePropulsion Technology Ltd.)" 1452 "Micro-Air" 1453 "Vital Battery" 1458 "Ride Controller" 1460 "Tocaro Blue" 1461 "Vanquish Yachts" 1471 "FT Technologies" 1478 "Alps Alpine" 1481 "E-Force Marine" 1482 "CMC Marine" 1483 "Nanjing Sandemarine Information Technology" 1850 "Teleflex Marine (SeaStar Solutions)" 1851 "Raymarine" 1852 "Navionics" 1853 "Japan Radio" 1854 "Northstar Technologies" 1855 "Furuno" 1856 "Trimble" 1857 "Simrad" 1858 "Litton" 1859 "Kvasar" 1860 "MMP" 1861 "Vector Cantech" 1862 "Yamaha Marine" 1863 "Faria Instruments" ;
VAL_ 2649686016 Industry_Code 0 "Global" 1 "Highway" 2 "Agriculture" 3 "Construction" 4 "Marine Industry" 5 "Industrial" ;
VAL_ 2649686016 Sub_protocol_ID 1900 "AHRS ATT transport" 5904 "Autopilot transport" ;
VAL_ 2649686016 Field 3 "Heartbeat" 10 "Mode State" 11 "Heading to Steer" 62 "Response Setting" 114 "Rate of Turn" 115 "Rate of Turn Order" 116 "Turn Angle Order" 158 "System Voltage" 161 "Turn Angle Measured" 239 "Engine RPM B" 240 "Engine RPM A" 246 "Speed" ;
VAL_ 2649686016 Mode_State 2 "Standby" 3 "Shadow Drive" 5 "Engaged" ;
VAL_ 2649686016 Manufacturer_Code 69 "ARKS Enterprises" 78 "FW Murphy/Enovation Controls" 80 "Twin Disc" 85 "Kohler Power Systems" 88 "Hemisphere GPS" 135 "Airmar" 137 "Maretron" 140 "Lowrance" 144 "Mercury Marine" 147 "Nautibus Electronic" 148 "Blue Water Data" 154 "Westerbeke" 157 "ISSPRO" 161 "Offshore Systems (UK)" 163 "Evinrude/BRP" 165 "CPAC Systems" 168 "Xantrex Technology" 169 "Marlin Technologies" 172 "Yanmar Marine" 174 "Volvo Penta" 176 "Carling Technologies Inc. (Moritz Aerospace)" 185 "Beede Instruments" 192 "Floscan Instrument" 193 "Nobeltec" 198 "Mystic Valley Communications" 199 "Actia" 201 "Disenos Y Technologia" 211 "Digital Switching Systems" 215 "Xintex/Atena" 224 "EMMI NETWORK" 228 "ZF" 229 "Garmin" 233 "Yacht Monitoring Solutions" 235 "Sailormade Marine Telemetry/Tetra Technology" 243 "Eride" 257 "Honda Motor" 272 "Groco" 273 "Actisense" 274 "Amphenol LTW Technology" 275 "Navico" 283 "Hamilton Jet" 285 "Sea Recovery" 286 "Coelmo SRL Italy" 295 "BEP Marine" 304 "Empir Bus" 305 "NovAtel" 306 "Sleipner Motor" 307 "MBW Technologies" 315 "ICOM" 328 "Qwerty" 329 "Dief" 341 "Boening Automationstechnologie" 345 "Korean Maritime University" 351 "Thrane and Thrane" 355 "Mastervolt" 356 "Fischer Panda Generators" 358 "Victron Energy" 370 "Rolls Royce Marine" 373 "Electronic Design" 374 "Northern Lights" 378 "Glendinning" 381 "B & G" 384 "Rose Point Navigation Systems" 385 "Johnson Outdoors Marine Electronics Inc Geonav" 394 "Capi 2" 396 "Beyond Measure" 400 "Livorsi Marine" 404 "ComNav" 409 "Chetco" 419 "Fusion Electronics" 421 "Standard Horizon" 422 "True Heading" 426 "Egersund Marine Electronics" 427 "em-trak Marine Electronics" 431 "Tohatsu Co, JP" 437 "Digital Yacht" 438 "Comar Systems Limited" 440 "Cummins" 443 "VDO (aka Continental-Corporation)" 451 "Parker Hannifin aka Village Marine Tech" 459 "Alltek Marine Electronics" 460 "SAN GIORGIO S.E.I.N" 466 "Veethree Electronics & Marine" 470 "SI-TEX Marine Electronics" 471 "Sea Cross Marine" 475 "GME aka Standard Communications" 476 "Humminbird Marine Electronics" 478 "Ocean Sat" 481 "Chetco Digital Instruments" 493 "Watcheye" 499 "Lcj Capteurs" 502 "Attwood Marine" 503 "Naviop S.R.L." 504 "Vesper Marine" 510 "Marinesoft" 513 "Simarine" 517 "NoLand Engineering" 518 "Transas USA" 529 "National Instruments Korea" 530 "National Marine Electronics Association" 532 "Onwa Marine" 540 "Webasto" 571 "Marinecraft (South Korea)" 573 "McMurdo Group aka Orolia" 578 "Advansea" 579 "KVH" 580 "San Jose Technology" 583 "Yacht Control" 586 "Suzuki Motor" 591 "US Coast Guard" 595 "Ship Module aka Customware" 600 "Aquatic AV" 605 "Aventics" 606 "Intellian" 612 "SamwonIT" 614 "Arlt Tecnologies" 637 "Bavaria Yachts" 641 "Diverse Yacht Services" 644 "Wema U.S.A dba KUS" 658 "Shenzhen Jiuzhou Himunication" 688 "Rockford" 699 "Harman International" 704 "JL Audio" 708 "Lars Thrane" 715 "Autonnic" 717 "Yacht Devices" 734 "REAP Systems" 735 "AEM Performance Electronics" 739 "LxNav" 741 "Littelfuse, Inc (formerly Carling Technologies)" 743 "DaeMyung" 744 "Woosung" 748 "ISOTTA IFRA srl" 773 "Clarion US" 776 "HMI Systems" 777 "Ocean Signal" 778 "Seakeeper" 781 "Poly Planar" 785 "Fischer Panda DE" 795 "Broyda Industries" 796 "Canadian Automotive" 797 "Tides Marine" 798 "Lumishore" 799 "Still Water Designs and Audio" 802 "BJ Technologies (Beneteau)" 803 "Gill Sensors" 811 "Blue Water Desalination" 815 "FLIR" 824 "Undheim Systems" 826 "Lewmar" 838 "TeamSurv" 844 "Fell Marine" 847 "Oceanvolt" 862 "Prospec" 868 "Data Panel" 890 "L3 Technologies" 894 "Rhodan Marine Systems" 896 "Nexfour Solutions" 905 "ASA Electronics" 909 "Marines Co (South Korea)" 911 "Nautic-on" 917 "Sentinel" 929 "JL Marine Systems" 930 "Ecotronix" 944 "Zontisa Marine" 951 "EXOR International" 962 "Timbolier Industries" 963 "TJC Micro" 968 "Cox Powertrain" 969 "Blue Seas" 981 "Kobelt Manufacturing" 992 "Blue Ocean IOT" 997 "Xenta Systems" 999 "Signal K" 1004 "Ultraflex" 1008 "Lintest SmartBoat" 1011 "Soundmax" 1020 "Team Italia Marine (Onyx Marine Automation s.r.l)" 1021 "Entratech" 1022 "ITC" 1029 "The Marine Guardian" 1047 "Sonic" 1051 "ProNav" 1053 "Vetus Maxwell INC." 1056 "Lithium Pros" 1059 "Boatrax" 1062 "Marol Co ltd" 1065 "CALYPSO Instruments" 1066 "Spot Zero Water" 1069 "Lithionics Battery" 1070 "Quick-teck Electronics" 1075 "Uniden America" 1083 "Nauticoncept" 1084 "Shadow-Caster LED lighting" 1085 "Wet Sounds" 1088 "E-T-A Circuit Breakers" 1092 "Scheiber" 1100 "Smart Yachts International Limited" 1109 "Dockmate" 1114 "Bobs Machine" 1118 "L3Harris ASV" 1119 "Balmar" 1120 "Elettromedia" 1127 "Electromaax" 1140 "Across Oceans Systems" 1145 "Kiwi Yachting" 1150 "BSB Artificial Intelligence" 1151 "Orca Technologies" 1154 "TBS Electronics" 1158 "Technoton Electroics" 1160 "MG Energy Systems" 1169 "Sea Machine Robotics" 1171 "Vista Manufacturing" 1183 "Zipwake" 1186 "Sailmon" 1192 "Airmoniq Pro Kft" 1194 "Sierra Marine" 1200 "Xinuo Information Technology (Xiamen)" 1218 "Septentrio" 1233 "NKE Marine Electronics" 1238 "SuperTrack Aps" 1239 "Honda Electronics" 1245 "Raritan Engineering" 1249 "Integrated Power Solutions AG" 1260 "Interactive Technologies" 1283 "LTG-Tech" 1299 "Energy Solutions (UK)" 1300 "WATT Fuel Cell" 1302 "Pro Mainer" 1305 "Dragonfly Energy" 1306 "Koden Electronics" 1311 "Humphree" 1316 "Hinkley Yachts" 1317 "Global Marine Management GmbH (GMM)" 1320 "Triskel Marine" 1330 "Warwick Control Technologies" 1331 "Dolphin Charger" 1337 "Barnacle Systems" 1348 "Radian IoT" 1353 "Ocean LED Marine" 1359 "BluNav" 1361 "OVA (Nantong Saiyang Electronics Co., Ltd)" 1368 "RAD Propulsion" 1369 "Electric Yacht" 1372 "Elco Motor Yachts" 1384 "Tecnoseal Foundry S.r.l" 1385 "Pro Charging Systems" 1389 "EVEX" 1398 "Gobius Sensor Technology" 1403 "Arco Marine" 1408 "Lenco Marine" 1413 "Naocontrol" 1417 "Revatek" 1438 "Aeolionics" 1439 "PredictWind" 1440 "Egis Mobile Electric" 1445 "Starboard Yacht Group" 1446 "Roswell Marine" 1451 "ePropulsion (Guangdong ePropulsion Technology Ltd.)" 1452 "Micro-Air" 1453 "Vital Battery" 1458 "Ride Controller" 1460 "Tocaro Blue" 1461 "Vanquish Yachts" 1471 "FT Technologies" 1478 "Alps Alpine" 1481 "E-Force Marine" 1482 "CMC Marine" 1483 "Nanjing Sandemarine Information Technology" 1850 "Teleflex Marine (SeaStar Solutions)" 1851 "Raymarine" 1852 "Navionics" 1853 "Japan Radio" 1854 "Northstar Technologies" 1855 "Furuno" 1856 "Trimble" 1857 "Simrad" 1858 "Litton" 1859 "Kvasar" 1860 "MMP" 1861 "Vector Cantech" 1862 "Yamaha Marine" 1863 "Faria Instruments" ;
VAL_ 2649686016 Industry_Code 0 "Global" 1 "Highway" 2 "Agriculture" 3 "Construction" 4 "Marine Industry" 5 "Industrial" ;
VAL_ 2649686016 Sub_protocol_ID 1900 "AHRS ATT transport" 5904 "Autopilot transport" ;
VAL_ 2649686016 Field 3 "Heartbeat" 10 "Mode State" 11 "Heading to Steer" 62 "Response Setting" 114 "Rate of Turn" 115 "Rate of Turn Order" 116 "Turn Angle Order" 158 "System Voltage" 161 "Turn Angle Measured" 239 "Engine RPM B" 240 "Engine RPM A" 246 "Speed" ;
VAL_ 2649686016 Manufacturer_Code 69 "ARKS Enterprises" 78 "FW Murphy/Enovation Controls" 80 "Twin Disc" 85 "Kohler Power Systems" 88 "Hemisphere GPS" 135 "Airmar" 137 "Maretron" 140 "Lowrance" 144 "Mercury Marine" 147 "Nautibus Electronic" 148 "Blue Water Data" 154 "Westerbeke" 157 "ISSPRO" 161 "Offshore Systems (UK)" 163 "Evinrude/BRP" 165 "CPAC Systems" 168 "Xantrex Technology" 169 "Marlin Technologies" 172 "Yanmar Marine" 174 "Volvo Penta" 176 "Carling Technologies Inc. (Moritz Aerospace)" 185 "Beede Instruments" 192 "Floscan Instrument" 193 "Nobeltec" 198 "Mystic Valley Communications" 199 "Actia" 201 "Disenos Y Technologia" 211 "Digital Switching Systems" 215 "Xintex/Atena" 224 "EMMI NETWORK" 228 "ZF" 229 "Garmin" 233 "Yacht Monitoring Solutions" 235 "Sailormade Marine Telemetry/Tetra Technology" 243 "Eride" 257 "Honda Motor" 272 "Groco" 273 "Actisense" 274 "Amphenol LTW Technology" 275 "Navico" 283 "Hamilton Jet" 285 "Sea Recovery" 286 "Coelmo SRL Italy" 295 "BEP Marine" 304 "Empir Bus" 305 "NovAtel" 306 "Sleipner Motor" 307 "MBW Technologies" 315 "ICOM" 328 "Qwerty" 329 "Dief" 341 "Boening Automationstechnologie" 345 "Korean Maritime University" 351 "Thrane and Thrane" 355 "Mastervolt" 356 "Fischer Panda Generators" 358 "Victron Energy" 370 "Rolls Royce Marine" 373 "Electronic Design" 374 "Northern Lights" 378 "Glendinning" 381 "B & G" 384 "Rose Point Navigation Systems" 385 "Johnson Outdoors Marine Electronics Inc Geonav" 394 "Capi 2" 396 "Beyond Measure" 400 "Livorsi Marine" 404 "ComNav" 409 "Chetco" 419 "Fusion Electronics" 421 "Standard Horizon" 422 "True Heading" 426 "Egersund Marine Electronics" 427 "em-trak Marine Electronics" 431 "Tohatsu Co, JP" 437 "Digital Yacht" 438 "Comar Systems Limited" 440 "Cummins" 443 "VDO (aka Continental-Corporation)" 451 "Parker Hannifin aka Village Marine Tech" 459 "Alltek Marine Electronics" 460 "SAN GIORGIO S.E.I.N" 466 "Veethree Electronics & Marine" 470 "SI-TEX Marine Electronics" 471 "Sea Cross Marine" 475 "GME aka Standard Communications" 476 "Humminbird Marine Electronics" 478 "Ocean Sat" 481 "Chetco Digital Instruments" 493 "Watcheye" 499 "Lcj Capteurs" 502 "Attwood Marine" 503 "Naviop S.R.L." 504 "Vesper Marine" 510 "Marinesoft" 513 "Simarine" 517 "NoLand Engineering" 518 "Transas USA" 529 "National Instruments Korea" 530 "National Marine Electronics Association" 532 "Onwa Marine" 540 "Webasto" 571 "Marinecraft (South Korea)" 573 "McMurdo Group aka Orolia" 578 "Advansea" 579 "KVH" 580 "San Jose Technology" 583 "Yacht Control" 586 "Suzuki Motor" 591 "US Coast Guard" 595 "Ship Module aka Customware" 600 "Aquatic AV" 605 "Aventics" 606 "Intellian" 612 "SamwonIT" 614 "Arlt Tecnologies" 637 "Bavaria Yachts" 641 "Diverse Yacht Services" 644 "Wema U.S.A dba KUS" 658 "Shenzhen Jiuzhou Himunication" 688 "Rockford" 699 "Harman International" 704 "JL Audio" 708 "Lars Thrane" 715 "Autonnic" 717 "Yacht Devices" 734 "REAP Systems" 735 "AEM Performance Electronics" 739 "LxNav" 741 "Littelfuse, Inc (formerly Carling Technologies)" 743 "DaeMyung" 744 "Woosung" 748 "ISOTTA IFRA srl" 773 "Clarion US" 776 "HMI Systems" 777 "Ocean Signal" 778 "Seakeeper" 781 "Poly Planar" 785 "Fischer Panda DE" 795 "Broyda Industries" 796 "Canadian Automotive" 797 "Tides Marine" 798 "Lumishore" 799 "Still Water Designs and Audio" 802 "BJ Technologies (Beneteau)" 803 "Gill Sensors" 811 "Blue Water Desalination" 815 "FLIR" 824 "Undheim Systems" 826 "Lewmar" 838 "TeamSurv" 844 "Fell Marine" 847 "Oceanvolt" 862 "Prospec" 868 "Data Panel" 890 "L3 Technologies" 894 "Rhodan Marine Systems" 896 "Nexfour Solutions" 905 "ASA Electronics" 909 "Marines Co (South Korea)" 911 "Nautic-on" 917 "Sentinel" 929 "JL Marine Systems" 930 "Ecotronix" 944 "Zontisa Marine" 951 "EXOR International" 962 "Timbolier Industries" 963 "TJC Micro" 968 "Cox Powertrain" 969 "Blue Seas" 981 "Kobelt Manufacturing" 992 "Blue Ocean IOT" 997 "Xenta Systems" 999 "Signal K" 1004 "Ultraflex" 1008 "Lintest SmartBoat" 1011 "Soundmax" 1020 "Team Italia Marine (Onyx Marine Automation s.r.l)" 1021 "Entratech" 1022 "ITC" 1029 "The Marine Guardian" 1047 "Sonic" 1051 "ProNav" 1053 "Vetus Maxwell INC." 1056 "Lithium Pros" 1059 "Boatrax" 1062 "Marol Co ltd" 1065 "CALYPSO Instruments" 1066 "Spot Zero Water" 1069 "Lithionics Battery" 1070 "Quick-teck Electronics" 1075 "Uniden America" 1083 "Nauticoncept" 1084 "Shadow-Caster LED lighting" 1085 "Wet Sounds" 1088 "E-T-A Circuit Breakers" 1092 "Scheiber" 1100 "Smart Yachts International Limited" 1109 "Dockmate" 1114 "Bobs Machine" 1118 "L3Harris ASV" 1119 "Balmar" 1120 "Elettromedia" 1127 "Electromaax" 1140 "Across Oceans Systems" 1145 "Kiwi Yachting" 1150 "BSB Artificial Intelligence" 1151 "Orca Technologies" 1154 "TBS Electronics" 1158 "Technoton Electroics" 1160 "MG Energy Systems" 1169 "Sea Machine Robotics" 1171 "Vista Manufacturing" 1183 "Zipwake" 1186 "Sailmon" 1192 "Airmoniq Pro Kft" 1194 "Sierra Marine" 1200 "Xinuo Information Technology (Xiamen)" 1218 "Septentrio" 1233 "NKE Marine Electronics" 1238 "SuperTrack Aps" 1239 "Honda Electronics" 1245 "Raritan Engineering" 1249 "Integrated Power Solutions AG" 1260 "Interactive Technologies" 1283 "LTG-Tech" 1299 "Energy Solutions (UK)" 1300 "WATT Fuel Cell" 1302 "Pro Mainer" 1305 "Dragonfly Energy" 1306 "Koden Electronics" 1311 "Humphree" 1316 "Hinkley Yachts" 1317 "Global Marine Management GmbH (GMM)" 1320 "Triskel Marine" 1330 "Warwick Control Technologies" 1331 "Dolphin Charger" 1337 "Barnacle Systems" 1348 "Radian IoT" 1353 "Ocean LED Marine" 1359 "BluNav" 1361 "OVA (Nantong Saiyang Electronics Co., Ltd)" 1368 "RAD Propulsion" 1369 "Electric Yacht" 1372 "Elco Motor Yachts" 1384 "Tecnoseal Foundry S.r.l" 1385 "Pro Charging Systems" 1389 "EVEX" 1398 "Gobius Sensor Technology" 1403 "Arco Marine" 1408 "Lenco Marine" 1413 "Naocontrol" 1417 "Revatek" 1438 "Aeolionics" 1439 "PredictWind" 1440 "Egis Mobile Electric" 1445 "Starboard Yacht Group" 1446 "Roswell Marine" 1451 "ePropulsion (Guangdong ePropulsion Technology Ltd.)" 1452 "Micro-Air" 1453 "Vital Battery" 1458 "Ride Controller" 1460 "Tocaro Blue" 1461 "Vanquish Yachts" 1471 "FT Technologies" 1478 "Alps Alpine" 1481 "E-Force Marine" 1482 "CMC Marine" 1483 "Nanjing Sandemarine Information Technology" 1850 "Teleflex Marine (SeaStar Solutions)" 1851 "Raymarine" 1852 "Navionics" 1853 "Japan Radio" 1854 "Northstar Technologies" 1855 "Furuno" 1856 "Trimble" 1857 "Simrad" 1858 "Litton" 1859 "Kvasar" 1860 "MMP" 1861 "Vector Cantech" 1862 "Yamaha Marine" 1863 "Faria Instruments" ;
VAL_ 2649686016 Industry_Code 0 "Global" 1 "Highway" 2 "Agriculture" 3 "Construction" 4 "Marine Industry" 5 "Industrial" ;
VAL_ 2649686016 Sub_protocol_ID 1900 "AHRS ATT transport" 5904 "Autopilot transport" ;
VAL_ 2649686016 Field 3 "Heartbeat" 10 "Mode State" 11 "Heading to Steer" 62 "Response Setting" 114 "Rate of Turn" 115 "Rate of Turn Order" 116 "Turn Angle Order" 158 "System Voltage" 161 "Turn Angle Measured" 239 "Engine RPM B" 240 "Engine RPM A" 246 "Speed" ;
VAL_ 2649686016 Manufacturer_Code 69 "ARKS Enterprises" 78 "FW Murphy/Enovation Controls" 80 "Twin Disc" 85 "Kohler Power Systems" 88 "Hemisphere GPS" 135 "Airmar" 137 "Maretron" 140 "Lowrance" 144 "Mercury Marine" 147 "Nautibus Electronic" 148 "Blue Water Data" 154 "Westerbeke" 157 "ISSPRO" 161 "Offshore Systems (UK)" 163 "Evinrude/BRP" 165 "CPAC Systems" 168 "Xantrex Technology" 169 "Marlin Technologies" 172 "Yanmar Marine" 174 "Volvo Penta" 176 "Carling Technologies Inc. (Moritz Aerospace)" 185 "Beede Instruments" 192 "Floscan Instrument" 193 "Nobeltec" 198 "Mystic Valley Communications" 199 "Actia" 201 "Disenos Y Technologia" 211 "Digital Switching Systems" 215 "Xintex/Atena" 224 "EMMI NETWORK" 228 "ZF" 229 "Garmin" 233 "Yacht Monitoring Solutions" 235 "Sailormade Marine Telemetry/Tetra Technology" 243 "Eride" 257 "Honda Motor" 272 "Groco" 273 "Actisense" 274 "Amphenol LTW Technology" 275 "Navico" 283 "Hamilton Jet" 285 "Sea Recovery" 286 "Coelmo SRL Italy" 295 "BEP Marine" 304 "Empir Bus" 305 "NovAtel" 306 "Sleipner Motor" 307 "MBW Technologies" 315 "ICOM" 328 "Qwerty" 329 "Dief" 341 "Boening Automationstechnologie" 345 "Korean Maritime University" 351 "Thrane and Thrane" 355 "Mastervolt" 356 "Fischer Panda Generators" 358 "Victron Energy" 370 "Rolls Royce Marine" 373 "Electronic Design" 374 "Northern Lights" 378 "Glendinning" 381 "B & G" 384 "Rose Point Navigation Systems" 385 "Johnson Outdoors Marine Electronics Inc Geonav" 394 "Capi 2" 396 "Beyond Measure" 400 "Livorsi Marine" 404 "ComNav" 409 "Chetco" 419 "Fusion Electronics" 421 "Standard Horizon" 422 "True Heading" 426 "Egersund Marine Electronics" 427 "em-trak Marine Electronics" 431 "Tohatsu Co, JP" 437 "Digital Yacht" 438 "Comar Systems Limited" 440 "Cummins" 443 "VDO (aka Continental-Corporation)" 451 "Parker Hannifin aka Village Marine Tech" 459 "Alltek Marine Electronics" 460 "SAN GIORGIO S.E.I.N" 466 "Veethree Electronics & Marine" 470 "SI-TEX Marine Electronics" 471 "Sea Cross Marine" 475 "GME aka Standard Communications" 476 "Humminbird Marine Electronics" 478 "Ocean Sat" 481 "Chetco Digital Instruments" 493 "Watcheye" 499 "Lcj Capteurs" 502 "Attwood Marine" 503 "Naviop S.R.L." 504 "Vesper Marine" 510 "Marinesoft" 513 "Simarine" 517 "NoLand Engineering" 518 "Transas USA" 529 "National Instruments Korea" 530 "National Marine Electronics Association" 532 "Onwa Marine" 540 "Webasto" 571 "Marinecraft (South Korea)" 573 "McMurdo Group aka Orolia" 578 "Advansea" 579 "KVH" 580 "San Jose Technology" 583 "Yacht Control" 586 "Suzuki Motor" 591 "US Coast Guard" 595 "Ship Module aka Customware" 600 "Aquatic AV" 605 "Aventics" 606 "Intellian" 612 "SamwonIT" 614 "Arlt Tecnologies" 637 "Bavaria Yachts" 641 "Diverse Yacht Services" 644 "Wema U.S.A dba KUS" 658 "Shenzhen Jiuzhou Himunication" 688 "Rockford" 699 "Harman International" 704 "JL Audio" 708 "Lars Thrane" 715 "Autonnic" 717 "Yacht Devices" 734 "REAP Systems" 735 "AEM Performance Electronics" 739 "LxNav" 741 "Littelfuse, Inc (formerly Carling Technologies)" 743 "DaeMyung" 744 "Woosung" 748 "ISOTTA IFRA srl" 773 "Clarion US" 776 "HMI Systems" 777 "Ocean Signal" 778 "Seakeeper" 781 "Poly Planar" 785 "Fischer Panda DE" 795 "Broyda Industries" 796 "Canadian Automotive" 797 "Tides Marine" 798 "Lumishore" 799 "Still Water Designs and Audio" 802 "BJ Technologies (Beneteau)" 803 "Gill Sensors" 811 "Blue Water Desalination" 815 "FLIR" 824 "Undheim Systems" 826 "Lewmar" 838 "TeamSurv" 844 "Fell Marine" 847 "Oceanvolt" 862 "Prospec" 868 "Data Panel" 890 "L3 Technologies" 894 "Rhodan Marine Systems" 896 "Nexfour Solutions" 905 "ASA Electronics" 909 "Marines Co (South Korea)" 911 "Nautic-on" 917 "Sentinel" 929 "JL Marine Systems" 930 "Ecotronix" 944 "Zontisa Marine" 951 "EXOR International" 962 "Timbolier Industries" 963 "TJC Micro" 968 "Cox Powertrain" 969 "Blue Seas" 981 "Kobelt Manufacturing" 992 "Blue Ocean IOT" 997 "Xenta Systems" 999 "Signal K" 1004 "Ultraflex" 1008 "Lintest SmartBoat" 1011 "Soundmax" 1020 "Team Italia Marine (Onyx Marine Automation s.r.l)" 1021 "Entratech" 1022 "ITC" 1029 "The Marine Guardian" 1047 "Sonic" 1051 "ProNav" 1053 "Vetus Maxwell INC." 1056 "Lithium Pros" 1059 "Boatrax" 1062 "Marol Co ltd" 1065 "CALYPSO Instruments" 1066 "Spot Zero Water" 1069 "Lithionics Battery" 1070 "Quick-teck Electronics" 1075 "Uniden America" 1083 "Nauticoncept" 1084 "Shadow-Caster LED lighting" 1085 "Wet Sounds" 1088 "E-T-A Circuit Breakers" 1092 "Scheiber" 1100 "Smart Yachts International Limited" 1109 "Dockmate" 1114 "Bobs Machine" 1118 "L3Harris ASV" 1119 "Balmar" 1120 "Elettromedia" 1127 "Electromaax" 1140 "Across Oceans Systems" 1145 "Kiwi Yachting" 1150 "BSB Artificial Intelligence" 1151 "Orca Technologies" 1154 "TBS Electronics" 1158 "Technoton Electroics" 1160 "MG Energy Systems" 1169 "Sea Machine Robotics" 1171 "Vista Manufacturing" 1183 "Zipwake" 1186 "Sailmon" 1192 "Airmoniq Pro Kft" 1194 "Sierra Marine" 1200 "Xinuo Information Technology (Xiamen)" 1218 "Septentrio" 1233 "NKE Marine Electronics" 1238 "SuperTrack Aps" 1239 "Honda Electronics" 1245 "Raritan Engineering" 1249 "Integrated Power Solutions AG" 1260 "Interactive Technologies" 1283 "LTG-Tech" 1299 "Energy Solutions (UK)" 1300 "WATT Fuel Cell" 1302 "Pro Mainer" 1305 "Dragonfly Energy" 1306 "Koden Electronics" 1311 "Humphree" 1316 "Hinkley Yachts" 1317 "Global Marine Management GmbH (GMM)" 1320 "Triskel Marine" 1330 "Warwick Control Technologies" 1331 "Dolphin Charger" 1337 "Barnacle Systems" 1348 "Radian IoT" 1353 "Ocean LED Marine" 1359 "BluNav" 1361 "OVA (Nantong Saiyang Electronics Co., Ltd)" 1368 "RAD Propulsion" 1369 "Electric Yacht" 1372 "Elco Motor Yachts" 1384 "Tecnoseal Foundry S.r.l" 1385 "Pro Charging Systems" 1389 "EVEX" 1398 "Gobius Sensor Technology" 1403 "Arco Marine" 1408 "Lenco Marine" 1413 "Naocontrol" 1417 "Revatek" 1438 "Aeolionics" 1439 "PredictWind" 1440 "Egis Mobile Electric" 1445 "Starboard Yacht Group" 1446 "Roswell Marine" 1451 "ePropulsion (Guangdong ePropulsion Technology Ltd.)" 1452 "Micro-Air" 1453 "Vital Battery" 1458 "Ride Controller" 1460 "Tocaro Blue" 1461 "Vanquish Yachts" 1471 "FT Technologies" 1478 "Alps Alpine" 1481 "E-Force Marine" 1482 "CMC Marine" 1483 "Nanjing Sandemarine Information Technology" 1850 "Teleflex Marine (SeaStar Solutions)" 1851 "Raymarine" 1852 "Navionics" 1853 "Japan Radio" 1854 "Northstar Technologies" 1855 "Furuno" 1856 "Trimble" 1857 "Simrad" 1858 "Litton" 1859 "Kvasar" 1860 "MMP" 1861 "Vector Cantech" 1862 "Yamaha Marine" 1863 "Faria Instruments" ;
VAL_ 2649686016 Industry_Code 0 "Global" 1 "Highway" 2 "Agriculture" 3 "Construction" 4 "Marine Industry" 5 "Industrial" ;
VAL_ 2649686016 Sub_protocol_ID 1900 "AHRS ATT transport" 5904 "Autopilot transport" ;
VAL_ 2649686016 Field 3 "Heartbeat" 10 "Mode State" 11 "Heading to Steer" 62 "Response Setting" 114 "Rate of Turn" 115 "Rate of Turn Order" 116 "Turn Angle Order" 158 "System Voltage" 161 "Turn Angle Measured" 239 "Engine RPM B" 240 "Engine RPM A" 246 "Speed" ;
VAL_ 2649686016 Manufacturer_Code 69 "ARKS Enterprises" 78 "FW Murphy/Enovation Controls" 80 "Twin Disc" 85 "Kohler Power Systems" 88 "Hemisphere GPS" 135 "Airmar" 137 "Maretron" 140 "Lowrance" 144 "Mercury Marine" 147 "Nautibus Electronic" 148 "Blue Water Data" 154 "Westerbeke" 157 "ISSPRO" 161 "Offshore Systems (UK)" 163 "Evinrude/BRP" 165 "CPAC Systems" 168 "Xantrex Technology" 169 "Marlin Technologies" 172 "Yanmar Marine" 174 "Volvo Penta" 176 "Carling Technologies Inc. (Moritz Aerospace)" 185 "Beede Instruments" 192 "Floscan Instrument" 193 "Nobeltec" 198 "Mystic Valley Communications" 199 "Actia" 201 "Disenos Y Technologia" 211 "Digital Switching Systems" 215 "Xintex/Atena" 224 "EMMI NETWORK" 228 "ZF" 229 "Garmin" 233 "Yacht Monitoring Solutions" 235 "Sailormade Marine Telemetry/Tetra Technology" 243 "Eride" 257 "Honda Motor" 272 "Groco" 273 "Actisense" 274 "Amphenol LTW Technology" 275 "Navico" 283 "Hamilton Jet" 285 "Sea Recovery" 286 "Coelmo SRL Italy" 295 "BEP Marine" 304 "Empir Bus" 305 "NovAtel" 306 "Sleipner Motor" 307 "MBW Technologies" 315 "ICOM" 328 "Qwerty" 329 "Dief" 341 "Boening Automationstechnologie" 345 "Korean Maritime University" 351 "Thrane and Thrane" 355 "Mastervolt" 356 "Fischer Panda Generators" 358 "Victron Energy" 370 "Rolls Royce Marine" 373 "Electronic Design" 374 "Northern Lights" 378 "Glendinning" 381 "B & G" 384 "Rose Point Navigation Systems" 385 "Johnson Outdoors Marine Electronics Inc Geonav" 394 "Capi 2" 396 "Beyond Measure" 400 "Livorsi Marine" 404 "ComNav" 409 "Chetco" 419 "Fusion Electronics" 421 "Standard Horizon" 422 "True Heading" 426 "Egersund Marine Electronics" 427 "em-trak Marine Electronics" 431 "Tohatsu Co, JP" 437 "Digital Yacht" 438 "Comar Systems Limited" 440 "Cummins" 443 "VDO (aka Continental-Corporation)" 451 "Parker Hannifin aka Village Marine Tech" 459 "Alltek Marine Electronics" 460 "SAN GIORGIO S.E.I.N" 466 "Veethree Electronics & Marine" 470 "SI-TEX Marine Electronics" 471 "Sea Cross Marine" 475 "GME aka Standard Communications" 476 "Humminbird Marine Electronics" 478 "Ocean Sat" 481 "Chetco Digital Instruments" 493 "Watcheye" 499 "Lcj Capteurs" 502 "Attwood Marine" 503 "Naviop S.R.L." 504 "Vesper Marine" 510 "Marinesoft" 513 "Simarine" 517 "NoLand Engineering" 518 "Transas USA" 529 "National Instruments Korea" 530 "National Marine Electronics Association" 532 "Onwa Marine" 540 "Webasto" 571 "Marinecraft (South Korea)" 573 "McMurdo Group aka Orolia" 578 "Advansea" 579 "KVH" 580 "San Jose Technology" 583 "Yacht Control" 586 "Suzuki Motor" 591 "US Coast Guard" 595 "Ship Module aka Customware" 600 "Aquatic AV" 605 "Aventics" 606 "Intellian" 612 "SamwonIT" 614 "Arlt Tecnologies" 637 "Bavaria Yachts" 641 "Diverse Yacht Services" 644 "Wema U.S.A dba KUS" 658 "Shenzhen Jiuzhou Himunication" 688 "Rockford" 699 "Harman International" 704 "JL Audio" 708 "Lars Thrane" 715 "Autonnic" 717 "Yacht Devices" 734 "REAP Systems" 735 "AEM Performance Electronics" 739 "LxNav" 741 "Littelfuse, Inc (formerly Carling Technologies)" 743 "DaeMyung" 744 "Woosung" 748 "ISOTTA IFRA srl" 773 "Clarion US" 776 "HMI Systems" 777 "Ocean Signal" 778 "Seakeeper" 781 "Poly Planar" 785 "Fischer Panda DE" 795 "Broyda Industries" 796 "Canadian Automotive" 797 "Tides Marine" 798 "Lumishore" 799 "Still Water Designs and Audio" 802 "BJ Technologies (Beneteau)" 803 "Gill Sensors" 811 "Blue Water Desalination" 815 "FLIR" 824 "Undheim Systems" 826 "Lewmar" 838 "TeamSurv" 844 "Fell Marine" 847 "Oceanvolt" 862 "Prospec" 868 "Data Panel" 890 "L3 Technologies" 894 "Rhodan Marine Systems" 896 "Nexfour Solutions" 905 "ASA Electronics" 909 "Marines Co (South Korea)" 911 "Nautic-on" 917 "Sentinel" 929 "JL Marine Systems" 930 "Ecotronix" 944 "Zontisa Marine" 951 "EXOR International" 962 "Timbolier Industries" 963 "TJC Micro" 968 "Cox Powertrain" 969 "Blue Seas" 981 "Kobelt Manufacturing" 992 "Blue Ocean IOT" 997 "Xenta Systems" 999 "Signal K" 1004 "Ultraflex" 1008 "Lintest SmartBoat" 1011 "Soundmax" 1020 "Team Italia Marine (Onyx Marine Automation s.r.l)" 1021 "Entratech" 1022 "ITC" 1029 "The Marine Guardian" 1047 "Sonic" 1051 "ProNav" 1053 "Vetus Maxwell INC." 1056 "Lithium Pros" 1059 "Boatrax" 1062 "Marol Co ltd" 1065 "CALYPSO Instruments" 1066 "Spot Zero Water" 1069 "Lithionics Battery" 1070 "Quick-teck Electronics" 1075 "Uniden America" 1083 "Nauticoncept" 1084 "Shadow-Caster LED lighting" 1085 "Wet Sounds" 1088 "E-T-A Circuit Breakers" 1092 "Scheiber" 1100 "Smart Yachts International Limited" 1109 "Dockmate" 1114 "Bobs Machine" 1118 "L3Harris ASV" 1119 "Balmar" 1120 "Elettromedia" 1127 "Electromaax" 1140 "Across Oceans Systems" 1145 "Kiwi Yachting" 1150 "BSB Artificial Intelligence" 1151 "Orca Technologies" 1154 "TBS Electronics" 1158 "Technoton Electroics" 1160 "MG Energy Systems" 1169 "Sea Machine Robotics" 1171 "Vista Manufacturing" 1183 "Zipwake" 1186 "Sailmon" 1192 "Airmoniq Pro Kft" 1194 "Sierra Marine" 1200 "Xinuo Information Technology (Xiamen)" 1218 "Septentrio" 1233 "NKE Marine Electronics" 1238 "SuperTrack Aps" 1239 "Honda Electronics" 1245 "Raritan Engineering" 1249 "Integrated Power Solutions AG" 1260 "Interactive Technologies" 1283 "LTG-Tech" 1299 "Energy Solutions (UK)" 1300 "WATT Fuel Cell" 1302 "Pro Mainer" 1305 "Dragonfly Energy" 1306 "Koden Electronics" 1311 "Humphree" 1316 "Hinkley Yachts" 1317 "Global Marine Management GmbH (GMM)" 1320 "Triskel Marine" 1330 "Warwick Control Technologies" 1331 "Dolphin Charger" 1337 "Barnacle Systems" 1348 "Radian IoT" 1353 "Ocean LED Marine" 1359 "BluNav" 1361 "OVA (Nantong Saiyang Electronics Co., Ltd)" 1368 "RAD Propulsion" 1369 "Electric Yacht" 1372 "Elco Motor Yachts" 1384 "Tecnoseal Foundry S.r.l" 1385 "Pro Charging Systems" 1389 "EVEX" 1398 "Gobius Sensor Technology" 1403 "Arco Marine" 1408 "Lenco Marine" 1413 "Naocontrol" 1417 "Revatek" 1438 "Aeolionics" 1439 "PredictWind" 1440 "Egis Mobile Electric" 1445 "Starboard Yacht Group" 1446 "Roswell Marine" 1451 "ePropulsion (Guangdong ePropulsion Technology Ltd.)" 1452 "Micro-Air" 1453 "Vital Battery" 1458 "Ride Controller" 1460 "Tocaro Blue" 1461 "Vanquish Yachts" 1471 "FT Technologies" 1478 "Alps Alpine" 1481 "E-Force Marine" 1482 "CMC Marine" 1483 "Nanjing Sandemarine Information Technology" 1850 "Teleflex Marine (SeaStar Solutions)" 1851 "Raymarine" 1852 "Navionics" 1853 "Japan Radio" 1854 "Northstar Technologies" 1855 "Furuno" 1856 "Trimble" 1857 "Simrad" 1858 "Litton" 1859 "Kvasar" 1860 "MMP" 1861 "Vector Cantech" 1862 "Yamaha Marine" 1863 "Faria Instruments" ;
VAL_ 2649686016 Industry_Code 0 "Global" 1 "Highway" 2 "Agriculture" 3 "Construction" 4 "Marine Industry" 5 "Industrial" ;
VAL_ 2649686016 Sub_protocol_ID 1900 "AHRS ATT transport" 5904 "Autopilot transport" ;
VAL_ 2649686016 Field 3 "Heartbeat" 10 "Mode State" 11 "Heading to Steer" 62 "Response Setting" 114 "Rate of Turn" 115 "Rate of Turn Order" 116 "Turn Angle Order" 158 "System Voltage" 161 "Turn Angle Measured" 239 "Engine RPM B" 240 "Engine RPM A" 246 "Speed" ;
VAL_ 2649686016 Manufacturer_Code 69 "ARKS Enterprises" 78 "FW Murphy/Enovation Controls" 80 "Twin Disc" 85 "Kohler Power Systems" 88 "Hemisphere GPS" 135 "Airmar" 137 "Maretron" 140 "Lowrance" 144 "Mercury Marine" 147 "Nautibus Electronic" 148 "Blue Water Data" 154 "Westerbeke" 157 "ISSPRO" 161 "Offshore Systems (UK)" 163 "Evinrude/BRP" 165 "CPAC Systems" 168 "Xantrex Technology" 169 "Marlin Technologies" 172 "Yanmar Marine" 174 "Volvo Penta" 176 "Carling Technologies Inc. (Moritz Aerospace)" 185 "Beede Instruments" 192 "Floscan Instrument" 193 "Nobeltec" 198 "Mystic Valley Communications" 199 "Actia" 201 "Disenos Y Technologia" 211 "Digital Switching Systems" 215 "Xintex/Atena" 224 "EMMI NETWORK" 228 "ZF" 229 "Garmin" 233 "Yacht Monitoring Solutions" 235 "Sailormade Marine Telemetry/Tetra Technology" 243 "Eride" 257 "Honda Motor" 272 "Groco" 273 "Actisense" 274 "Amphenol LTW Technology" 275 "Navico" 283 "Hamilton Jet" 285 "Sea Recovery" 286 "Coelmo SRL Italy" 295 "BEP Marine" 304 "Empir Bus" 305 "NovAtel" 306 "Sleipner Motor" 307 "MBW Technologies" 315 "ICOM" 328 "Qwerty" 329 "Dief" 341 "Boening Automationstechnologie" 345 "Korean Maritime University" 351 "Thrane and Thrane" 355 "Mastervolt" 356 "Fischer Panda Generators" 358 "Victron Energy" 370 "Rolls Royce Marine" 373 "Electronic Design" 374 "Northern Lights" 378 "Glendinning" 381 "B & G" 384 "Rose Point Navigation Systems" 385 "Johnson Outdoors Marine Electronics Inc Geonav" 394 "Capi 2" 396 "Beyond Measure" 400 "Livorsi Marine" 404 "ComNav" 409 "Chetco" 419 "Fusion Electronics" 421 "Standard Horizon" 422 "True Heading" 426 "Egersund Marine Electronics" 427 "em-trak Marine Electronics" 431 "Tohatsu Co, JP" 437 "Digital Yacht" 438 "Comar Systems Limited" 440 "Cummins" 443 "VDO (aka Continental-Corporation)" 451 "Parker Hannifin aka Village Marine Tech" 459 "Alltek Marine Electronics" 460 "SAN GIORGIO S.E.I.N" 466 "Veethree Electronics & Marine" 470 "SI-TEX Marine Electronics" 471 "Sea Cross Marine" 475 "GME aka Standard Communications" 476 "Humminbird Marine Electronics" 478 "Ocean Sat" 481 "Chetco Digital Instruments" 493 "Watcheye" 499 "Lcj Capteurs" 502 "Attwood Marine" 503 "Naviop S.R.L." 504 "Vesper Marine" 510 "Marinesoft" 513 "Simarine" 517 "NoLand Engineering" 518 "Transas USA" 529 "National Instruments Korea" 530 "National Marine Electronics Association" 532 "Onwa Marine" 540 "Webasto" 571 "Marinecraft (South Korea)" 573 "McMurdo Group aka Orolia" 578 "Advansea" 579 "KVH" 580 "San Jose Technology" 583 "Yacht Control" 586 "Suzuki Motor" 591 "US Coast Guard" 595 "Ship Module aka Customware" 600 "Aquatic AV" 605 "Aventics" 606 "Intellian" 612 "SamwonIT" 614 "Arlt Tecnologies" 637 "Bavaria Yachts" 641 "Diverse Yacht Services" 644 "Wema U.S.A dba KUS" 658 "Shenzhen Jiuzhou Himunication" 688 "Rockford" 699 "Harman International" 704 "JL Audio" 708 "Lars Thrane" 715 "Autonnic" 717 "Yacht Devices" 734 "REAP Systems" 735 "AEM Performance Electronics" 739 "LxNav" 741 "Littelfuse, Inc (formerly Carling Technologies)" 743 "DaeMyung" 744 "Woosung" 748 "ISOTTA IFRA srl" 773 "Clarion US" 776 "HMI Systems" 777 "Ocean Signal" 778 "Seakeeper" 781 "Poly Planar" 785 "Fischer Panda DE" 795 "Broyda Industries" 796 "Canadian Automotive" 797 "Tides Marine" 798 "Lumishore" 799 "Still Water Designs and Audio" 802 "BJ Technologies (Beneteau)" 803 "Gill Sensors" 811 "Blue Water Desalination" 815 "FLIR" 824 "Undheim Systems" 826 "Lewmar" 838 "TeamSurv" 844 "Fell Marine" 847 "Oceanvolt" 862 "Prospec" 868 "Data Panel" 890 "L3 Technologies" 894 "Rhodan Marine Systems" 896 "Nexfour Solutions" 905 "ASA Electronics" 909 "Marines Co (South Korea)" 911 "Nautic-on" 917 "Sentinel" 929 "JL Marine Systems" 930 "Ecotronix" 944 "Zontisa Marine" 951 "EXOR International" 962 "Timbolier Industries" 963 "TJC Micro" 968 "Cox Powertrain" 969 "Blue Seas" 981 "Kobelt Manufacturing" 992 "Blue Ocean IOT" 997 "Xenta Systems" 999 "Signal K" 1004 "Ultraflex" 1008 "Lintest SmartBoat" 1011 "Soundmax" 1020 "Team Italia Marine (Onyx Marine Automation s.r.l)" 1021 "Entratech" 1022 "ITC" 1029 "The Marine Guardian" 1047 "Sonic" 1051 "ProNav" 1053 "Vetus Maxwell INC." 1056 "Lithium Pros" 1059 "Boatrax" 1062 "Marol Co ltd" 1065 "CALYPSO Instruments" 1066 "Spot Zero Water" 1069 "Lithionics Battery" 1070 "Quick-teck Electronics" 1075 "Uniden America" 1083 "Nauticoncept" 1084 "Shadow-Caster LED lighting" 1085 "Wet Sounds" 1088 "E-T-A Circuit Breakers" 1092 "Scheiber" 1100 "Smart Yachts International Limited" 1109 "Dockmate" 1114 "Bobs Machine" 1118 "L3Harris ASV" 1119 "Balmar" 1120 "Elettromedia" 1127 "Electromaax" 1140 "Across Oceans Systems" 1145 "Kiwi Yachting" 1150 "BSB Artificial Intelligence" 1151 "Orca Technologies" 1154 "TBS Electronics" 1158 "Technoton Electroics" 1160 "MG Energy Systems" 1169 "Sea Machine Robotics" 1171 "Vista Manufacturing" 1183 "Zipwake" 1186 "Sailmon" 1192 "Airmoniq Pro Kft" 1194 "Sierra Marine" 1200 "Xinuo Information Technology (Xiamen)" 1218 "Septentrio" 1233 "NKE Marine Electronics" 1238 "SuperTrack Aps" 1239 "Honda Electronics" 1245 "Raritan Engineering" 1249 "Integrated Power Solutions AG" 1260 "Interactive Technologies" 1283 "LTG-Tech" 1299 "Energy Solutions (UK)" 1300 "WATT Fuel Cell" 1302 "Pro Mainer" 1305 "Dragonfly Energy" 1306 "Koden Electronics" 1311 "Humphree" 1316 "Hinkley Yachts" 1317 "Global Marine Management GmbH (GMM)" 1320 "Triskel Marine" 1330 "Warwick Control Technologies" 1331 "Dolphin Charger" 1337 "Barnacle Systems" 1348 "Radian IoT" 1353 "Ocean LED Marine" 1359 "BluNav" 1361 "OVA (Nantong Saiyang Electronics Co., Ltd)" 1368 "RAD Propulsion" 1369 "Electric Yacht" 1372 "Elco Motor Yachts" 1384 "Tecnoseal Foundry S.r.l" 1385 "Pro Charging Systems" 1389 "EVEX" 1398 "Gobius Sensor Technology" 1403 "Arco Marine" 1408 "Lenco Marine" 1413 "Naocontrol" 1417 "Revatek" 1438 "Aeolionics" 1439 "PredictWind" 1440 "Egis Mobile Electric" 1445 "Starboard Yacht Group" 1446 "Roswell Marine" 1451 "ePropulsion (Guangdong ePropulsion Technology Ltd.)" 1452 "Micro-Air" 1453 "Vital Battery" 1458 "Ride Controller" 1460 "Tocaro Blue" 1461 "Vanquish Yachts" 1471 "FT Technologies" 1478 "Alps Alpine" 1481 "E-Force Marine" 1482 "CMC Marine" 1483 "Nanjing Sandemarine Information Technology" 1850 "Teleflex Marine (SeaStar Solutions)" 1851 "Raymarine" 1852 "Navionics" 1853 "Japan Radio" 1854 "Northstar Technologies" 1855 "Furuno" 1856 "Trimble" 1857 "Simrad" 1858 "Litton" 1859 "Kvasar" 1860 "MMP" 1861 "Vector Cantech" 1862 "Yamaha Marine" 1863 "Faria Instruments" ;
VAL_ 2649686016 Industry_Code 0 "Global" 1 "Highway" 2 "Agriculture" 3 "Construction" 4 "Marine Industry" 5 "Industrial" ;
VAL_ 2649686016 Sub_protocol_ID 1900 "AHRS ATT transport" 5904 "Autopilot transport" ;
VAL_ 2649686016 Field 3 "Heartbeat" 10 "Mode State" 11 "Heading to Steer" 62 "Response Setting" 114 "Rate of Turn" 115 "Rate of Turn Order" 116 "Turn Angle Order" 158 "System Voltage" 161 "Turn Angle Measured" 239 "Engine RPM B" 240 "Engine RPM A" 246 "Speed" ;
VAL_ 2649686016 Manufacturer_Code 69 "ARKS Enterprises" 78 "FW Murphy/Enovation Controls" 80 "Twin Disc" 85 "Kohler Power Systems" 88 "Hemisphere GPS" 135 "Airmar" 137 "Maretron" 140 "Lowrance" 144 "Mercury Marine" 147 "Nautibus Electronic" 148 "Blue Water Data" 154 "Westerbeke" 157 "ISSPRO" 161 "Offshore Systems (UK)" 163 "Evinrude/BRP" 165 "CPAC Systems" 168 "Xantrex Technology" 169 "Marlin Technologies" 172 "Yanmar Marine" 174 "Volvo Penta" 176 "Carling Technologies Inc. (Moritz Aerospace)" 185 "Beede Instruments" 192 "Floscan Instrument" 193 "Nobeltec" 198 "Mystic Valley Communications" 199 "Actia" 201 "Disenos Y Technologia" 211 "Digital Switching Systems" 215 "Xintex/Atena" 224 "EMMI NETWORK" 228 "ZF" 229 "Garmin" 233 "Yacht Monitoring Solutions" 235 "Sailormade Marine Telemetry/Tetra Technology" 243 "Eride" 257 "Honda Motor" 272 "Groco" 273 "Actisense" 274 "Amphenol LTW Technology" 275 "Navico" 283 "Hamilton Jet" 285 "Sea Recovery" 286 "Coelmo SRL Italy" 295 "BEP Marine" 304 "Empir Bus" 305 "NovAtel" 306 "Sleipner Motor" 307 "MBW Technologies" 315 "ICOM" 328 "Qwerty" 329 "Dief" 341 "Boening Automationstechnologie" 345 "Korean Maritime University" 351 "Thrane and Thrane" 355 "Mastervolt" 356 "Fischer Panda Generators" 358 "Victron Energy" 370 "Rolls Royce Marine" 373 "Electronic Design" 374 "Northern Lights" 378 "Glendinning" 381 "B & G" 384 "Rose Point Navigation Systems" 385 "Johnson Outdoors Marine Electronics Inc Geonav" 394 "Capi 2" 396 "Beyond Measure" 400 "Livorsi Marine" 404 "ComNav" 409 "Chetco" 419 "Fusion Electronics" 421 "Standard Horizon" 422 "True Heading" 426 "Egersund Marine Electronics" 427 "em-trak Marine Electronics" 431 "Tohatsu Co, JP" 437 "Digital Yacht" 438 "Comar Systems Limited" 440 "Cummins" 443 "VDO (aka Continental-Corporation)" 451 "Parker Hannifin aka Village Marine Tech" 459 "Alltek Marine Electronics" 460 "SAN GIORGIO S.E.I.N" 466 "Veethree Electronics & Marine" 470 "SI-TEX Marine Electronics" 471 "Sea Cross Marine" 475 "GME aka Standard Communications" 476 "Humminbird Marine Electronics" 478 "Ocean Sat" 481 "Chetco Digital Instruments" 493 "Watcheye" 499 "Lcj Capteurs" 502 "Attwood Marine" 503 "Naviop S.R.L." 504 "Vesper Marine" 510 "Marinesoft" 513 "Simarine" 517 "NoLand Engineering" 518 "Transas USA" 529 "National Instruments Korea" 530 "National Marine Electronics Association" 532 "Onwa Marine" 540 "Webasto" 571 "Marinecraft (South Korea)" 573 "McMurdo Group aka Orolia" 578 "Advansea" 579 "KVH" 580 "San Jose Technology" 583 "Yacht Control" 586 "Suzuki Motor" 591 "US Coast Guard" 595 "Ship Module aka Customware" 600 "Aquatic AV" 605 "Aventics" 606 "Intellian" 612 "SamwonIT" 614 "Arlt Tecnologies" 637 "Bavaria Yachts" 641 "Diverse Yacht Services" 644 "Wema U.S.A dba KUS" 658 "Shenzhen Jiuzhou Himunication" 688 "Rockford" 699 "Harman International" 704 "JL Audio" 708 "Lars Thrane" 715 "Autonnic" 717 "Yacht Devices" 734 "REAP Systems" 735 "AEM Performance Electronics" 739 "LxNav" 741 "Littelfuse, Inc (formerly Carling Technologies)" 743 "DaeMyung" 744 "Woosung" 748 "ISOTTA IFRA srl" 773 "Clarion US" 776 "HMI Systems" 777 "Ocean Signal" 778 "Seakeeper" 781 "Poly Planar" 785 "Fischer Panda DE" 795 "Broyda Industries" 796 "Canadian Automotive" 797 "Tides Marine" 798 "Lumishore" 799 "Still Water Designs and Audio" 802 "BJ Technologies (Beneteau)" 803 "Gill Sensors" 811 "Blue Water Desalination" 815 "FLIR" 824 "Undheim Systems" 826 "Lewmar" 838 "TeamSurv" 844 "Fell Marine" 847 "Oceanvolt" 862 "Prospec" 868 "Data Panel" 890 "L3 Technologies" 894 "Rhodan Marine Systems" 896 "Nexfour Solutions" 905 "ASA Electronics" 909 "Marines Co (South Korea)" 911 "Nautic-on" 917 "Sentinel" 929 "JL Marine Systems" 930 "Ecotronix" 944 "Zontisa Marine" 951 "EXOR International" 962 "Timbolier Industries" 963 "TJC Micro" 968 "Cox Powertrain" 969 "Blue Seas" 981 "Kobelt Manufacturing" 992 "Blue Ocean IOT" 997 "Xenta Systems" 999 "Signal K" 1004 "Ultraflex" 1008 "Lintest SmartBoat" 1011 "Soundmax" 1020 "Team Italia Marine (Onyx Marine Automation s.r.l)" 1021 "Entratech" 1022 "ITC" 1029 "The Marine Guardian" 1047 "Sonic" 1051 "ProNav" 1053 "Vetus Maxwell INC." 1056 "Lithium Pros" 1059 "Boatrax" 1062 "Marol Co ltd" 1065 "CALYPSO Instruments" 1066 "Spot Zero Water" 1069 "Lithionics Battery" 1070 "Quick-teck Electronics" 1075 "Uniden America" 1083 "Nauticoncept" 1084 "Shadow-Caster LED lighting" 1085 "Wet Sounds" 1088 "E-T-A Circuit Breakers" 1092 "Scheiber" 1100 "Smart Yachts International Limited" 1109 "Dockmate" 1114 "Bobs Machine" 1118 "L3Harris ASV" 1119 "Balmar" 1120 "Elettromedia" 1127 "Electromaax" 1140 "Across Oceans Systems" 1145 "Kiwi Yachting" 1150 "BSB Artificial Intelligence" 1151 "Orca Technologies" 1154 "TBS Electronics" 1158 "Technoton Electroics" 1160 "MG Energy Systems" 1169 "Sea Machine Robotics" 1171 "Vista Manufacturing" 1183 "Zipwake" 1186 "Sailmon" 1192 "Airmoniq Pro Kft" 1194 "Sierra Marine" 1200 "Xinuo Information Technology (Xiamen)" 1218 "Septentrio" 1233 "NKE Marine Electronics" 1238 "SuperTrack Aps" 1239 "Honda Electronics" 1245 "Raritan Engineering" 1249 "Integrated Power Solutions AG" 1260 "Interactive Technologies" 1283 "LTG-Tech" 1299 "Energy Solutions (UK)" 1300 "WATT Fuel Cell" 1302 "Pro Mainer" 1305 "Dragonfly Energy" 1306 "Koden Electronics" 1311 "Humphree" 1316 "Hinkley Yachts" 1317 "Global Marine Management GmbH (GMM)" 1320 "Triskel Marine" 1330 "Warwick Control Technologies" 1331 "Dolphin Charger" 1337 "Barnacle Systems" 1348 "Radian IoT" 1353 "Ocean LED Marine" 1359 "BluNav" 1361 "OVA (Nantong Saiyang Electronics Co., Ltd)" 1368 "RAD Propulsion" 1369 "Electric Yacht" 1372 "Elco Motor Yachts" 1384 "Tecnoseal Foundry S.r.l" 1385 "Pro Charging Systems" 1389 "EVEX" 1398 "Gobius Sensor Technology" 1403 "Arco Marine" 1408 "Lenco Marine" 1413 "Naocontrol" 1417 "Revatek" 1438 "Aeolionics" 1439 "PredictWind" 1440 "Egis Mobile Electric" 1445 "Starboard Yacht Group" 1446 "Roswell Marine" 1451 "ePropulsion (Guangdong ePropulsion Technology Ltd.)" 1452 "Micro-Air" 1453 "Vital Battery" 1458 "Ride Controller" 1460 "Tocaro Blue" 1461 "Vanquish Yachts" 1471 "FT Technologies" 1478 "Alps Alpine" 1481 "E-Force Marine" 1482 "CMC Marine" 1483 "Nanjing Sandemarine Information Technology" 1850 "Teleflex Marine (SeaStar Solutions)" 1851 "Raymarine" 1852 "Navionics" 1853 "Japan Radio" 1854 "Northstar Technologies" 1855 "Furuno" 1856 "Trimble" 1857 "Simrad" 1858 "Litton" 1859 "Kvasar" 1860 "MMP" 1861 "Vector Cantech" 1862 "Yamaha Marine" 1863 "Faria Instruments" ;
VAL_ 2649686016 Industry_Code 0 "Global" 1 "Highway" 2 "Agriculture" 3 "Construction" 4 "Marine Industry" 5 "Industrial" ;
VAL_ 2649686016 Sub_protocol_ID 1900 "AHRS ATT transport" 5904 "Autopilot transport" ;
VAL_ 2649686016 Field 3 "Heartbeat" 10 "Mode State" 11 "Heading to Steer" 62 "Response Setting" 114 "Rate of Turn" 115 "Rate of Turn Order" 116 "Turn Angle Order" 158 "System Voltage" 161 "Turn Angle Measured" 239 "Engine RPM B" 240 "Engine RPM A" 246 "Speed" ;
VAL_ 2649686016 Manufacturer_Code 69 "ARKS Enterprises" 78 "FW Murphy/Enovation Controls" 80 "Twin Disc" 85 "Kohler Power Systems" 88 "Hemisphere GPS" 135 "Airmar" 137 "Maretron" 140 "Lowrance" 144 "Mercury Marine" 147 "Nautibus Electronic" 148 "Blue Water Data" 154 "Westerbeke" 157 "ISSPRO" 161 "Offshore Systems (UK)" 163 "Evinrude/BRP" 165 "CPAC Systems" 168 "Xantrex Technology" 169 "Marlin Technologies" 172 "Yanmar Marine" 174 "Volvo Penta" 176 "Carling Technologies Inc. (Moritz Aerospace)" 185 "Beede Instruments" 192 "Floscan Instrument" 193 "Nobeltec" 198 "Mystic Valley Communications" 199 "Actia" 201 "Disenos Y Technologia" 211 "Digital Switching Systems" 215 "Xintex/Atena" 224 "EMMI NETWORK" 228 "ZF" 229 "Garmin" 233 "Yacht Monitoring Solutions" 235 "Sailormade Marine Telemetry/Tetra Technology" 243 "Eride" 257 "Honda Motor" 272 "Groco" 273 "Actisense" 274 "Amphenol LTW Technology" 275 "Navico" 283 "Hamilton Jet" 285 "Sea Recovery" 286 "Coelmo SRL Italy" 295 "BEP Marine" 304 "Empir Bus" 305 "NovAtel" 306 "Sleipner Motor" 307 "MBW Technologies" 315 "ICOM" 328 "Qwerty" 329 "Dief" 341 "Boening Automationstechnologie" 345 "Korean Maritime University" 351 "Thrane and Thrane" 355 "Mastervolt" 356 "Fischer Panda Generators" 358 "Victron Energy" 370 "Rolls Royce Marine" 373 "Electronic Design" 374 "Northern Lights" 378 "Glendinning" 381 "B & G" 384 "Rose Point Navigation Systems" 385 "Johnson Outdoors Marine Electronics Inc Geonav" 394 "Capi 2" 396 "Beyond Measure" 400 "Livorsi Marine" 404 "ComNav" 409 "Chetco" 419 "Fusion Electronics" 421 "Standard Horizon" 422 "True Heading" 426 "Egersund Marine Electronics" 427 "em-trak Marine Electronics" 431 "Tohatsu Co, JP" 437 "Digital Yacht" 438 "Comar Systems Limited" 440 "Cummins" 443 "VDO (aka Continental-Corporation)" 451 "Parker Hannifin aka Village Marine Tech" 459 "Alltek Marine Electronics" 460 "SAN GIORGIO S.E.I.N" 466 "Veethree Electronics & Marine" 470 "SI-TEX Marine Electronics" 471 "Sea Cross Marine" 475 "GME aka Standard Communications" 476 "Humminbird Marine Electronics" 478 "Ocean Sat" 481 "Chetco Digital Instruments" 493 "Watcheye" 499 "Lcj Capteurs" 502 "Attwood Marine" 503 "Naviop S.R.L." 504 "Vesper Marine" 510 "Marinesoft" 513 "Simarine" 517 "NoLand Engineering" 518 "Transas USA" 529 "National Instruments Korea" 530 "National Marine Electronics Association" 532 "Onwa Marine" 540 "Webasto" 571 "Marinecraft (South Korea)" 573 "McMurdo Group aka Orolia" 578 "Advansea" 579 "KVH" 580 "San Jose Technology" 583 "Yacht Control" 586 "Suzuki Motor" 591 "US Coast Guard" 595 "Ship Module aka Customware" 600 "Aquatic AV" 605 "Aventics" 606 "Intellian" 612 "SamwonIT" 614 "Arlt Tecnologies" 637 "Bavaria Yachts" 641 "Diverse Yacht Services" 644 "Wema U.S.A dba KUS" 658 "Shenzhen Jiuzhou Himunication" 688 "Rockford" 699 "Harman International" 704 "JL Audio" 708 "Lars Thrane" 715 "Autonnic" 717 "Yacht Devices" 734 "REAP Systems" 735 "AEM Performance Electronics" 739 "LxNav" 741 "Littelfuse, Inc (formerly Carling Technologies)" 743 "DaeMyung" 744 "Woosung" 748 "ISOTTA IFRA srl" 773 "Clarion US" 776 "HMI Systems" 777 "Ocean Signal" 778 "Seakeeper" 781 "Poly Planar" 785 "Fischer Panda DE" 795 "Broyda Industries" 796 "Canadian Automotive" 797 "Tides Marine" 798 "Lumishore" 799 "Still Water Designs and Audio" 802 "BJ Technologies (Beneteau)" 803 "Gill Sensors" 811 "Blue Water Desalination" 815 "FLIR" 824 "Undheim Systems" 826 "Lewmar" 838 "TeamSurv" 844 "Fell Marine" 847 "Oceanvolt" 862 "Prospec" 868 "Data Panel" 890 "L3 Technologies" 894 "Rhodan Marine Systems" 896 "Nexfour Solutions" 905 "ASA Electronics" 909 "Marines Co (South Korea)" 911 "Nautic-on" 917 "Sentinel" 929 "JL Marine Systems" 930 "Ecotronix" 944 "Zontisa Marine" 951 "EXOR International" 962 "Timbolier Industries" 963 "TJC Micro" 968 "Cox Powertrain" 969 "Blue Seas" 981 "Kobelt Manufacturing" 992 "Blue Ocean IOT" 997 "Xenta Systems" 999 "Signal K" 1004 "Ultraflex" 1008 "Lintest SmartBoat" 1011 "Soundmax" 1020 "Team Italia Marine (Onyx Marine Automation s.r.l)" 1021 "Entratech" 1022 "ITC" 1029 "The Marine Guardian" 1047 "Sonic" 1051 "ProNav" 1053 "Vetus Maxwell INC." 1056 "Lithium Pros" 1059 "Boatrax" 1062 "Marol Co ltd" 1065 "CALYPSO Instruments" 1066 "Spot Zero Water" 1069 "Lithionics Battery" 1070 "Quick-teck Electronics" 1075 "Uniden America" 1083 "Nauticoncept" 1084 "Shadow-Caster LED lighting" 1085 "Wet Sounds" 1088 "E-T-A Circuit Breakers" 1092 "Scheiber" 1100 "Smart Yachts International Limited" 1109 "Dockmate" 1114 "Bobs Machine" 1118 "L3Harris ASV" 1119 "Balmar" 1120 "Elettromedia" 1127 "Electromaax" 1140 "Across Oceans Systems" 1145 "Kiwi Yachting" 1150 "BSB Artificial Intelligence" 1151 "Orca Technologies" 1154 "TBS Electronics" 1158 "Technoton Electroics" 1160 "MG Energy Systems" 1169 "Sea Machine Robotics" 1171 "Vista Manufacturing" 1183 "Zipwake" 1186 "Sailmon" 1192 "Airmoniq Pro Kft" 1194 "Sierra Marine" 1200 "Xinuo Information Technology (Xiamen)" 1218 "Septentrio" 1233 "NKE Marine Electronics" 1238 "SuperTrack Aps" 1239 "Honda Electronics" 1245 "Raritan Engineering" 1249 "Integrated Power Solutions AG" 1260 "Interactive Technologies" 1283 "LTG-Tech" 1299 "Energy Solutions (UK)" 1300 "WATT Fuel Cell" 1302 "Pro Mainer" 1305 "Dragonfly Energy" 1306 "Koden Electronics" 1311 "Humphree" 1316 "Hinkley Yachts" 1317 "Global Marine Management GmbH (GMM)" 1320 "Triskel Marine" 1330 "Warwick Control Technologies" 1331 "Dolphin Charger" 1337 "Barnacle Systems" 1348 "Radian IoT" 1353 "Ocean LED Marine" 1359 "BluNav" 1361 "OVA (Nantong Saiyang Electronics Co., Ltd)" 1368 "RAD Propulsion" 1369 "Electric Yacht" 1372 "Elco Motor Yachts" 1384 "Tecnoseal Foundry S.r.l" 1385 "Pro Charging Systems" 1389 "EVEX" 1398 "Gobius Sensor Technology" 1403 "Arco Marine" 1408 "Lenco Marine" 1413 "Naocontrol" 1417 "Revatek" 1438 "Aeolionics" 1439 "PredictWind" 1440 "Egis Mobile Electric" 1445 "Starboard Yacht Group" 1446 "Roswell Marine" 1451 "ePropulsion (Guangdong ePropulsion Technology Ltd.)" 1452 "Micro-Air" 1453 "Vital Battery" 1458 "Ride Controller" 1460 "Tocaro Blue" 1461 "Vanquish Yachts" 1471 "FT Technologies" 1478 "Alps Alpine" 1481 "E-Force Marine" 1482 "CMC Marine" 1483 "Nanjing Sandemarine Information Technology" 1850 "Teleflex Marine (SeaStar Solutions)" 1851 "Raymarine" 1852 "Navionics" 1853 "Japan Radio" 1854 "Northstar Technologies" 1855 "Furuno" 1856 "Trimble" 1857 "Simrad" 1858 "Litton" 1859 "Kvasar" 1860 "MMP" 1861 "Vector Cantech" 1862 "Yamaha Marine" 1863 "Faria Instruments" ;
VAL_ 2649686016 Industry_Code 0 "Global" 1 "Highway" 2 "Agriculture" 3 "Construction" 4 "Marine Industry" 5 "Industrial" ;
VAL_ 2649686016 Sub_protocol_ID 1900 "AHRS ATT transport" 5904 "Autopilot transport" ;
VAL_ 2649686016 Field 3 "Heartbeat" 10 "Mode State" 11 "Heading to Steer" 62 "Response Setting" 114 "Rate of Turn" 115 "Rate of Turn Order" 116 "Turn Angle Order" 158 "System Voltage" 161 "Turn Angle Measured" 239 "Engine RPM B" 240 "Engine RPM A" 246 "Speed" ;
VAL_ 2582577152 Industry_Code 0 "Global" 1 "Highway" 2 "Agriculture" 3 "Construction" 4 "Marine Industry" 5 "Industrial" ;
VAL_ 2582577152 Mode 0 "Day" 1 "Night" 13 "Color" ;
VAL_ 2582577152 Color 0 "Day full color" 1 "Day high contrast" 2 "Night full color" 3 "Night red/black" 4 "Night green/black" ;
VAL_ 2582577152 Industry_Code 0 "Global" 1 "Highway" 2 "Agriculture" 3 "Construction" 4 "Marine Industry" 5 "Industrial" ;
VAL_ 2582577152 Mode 0 "Day" 1 "Night" 13 "Color" ;
VAL_ 2582577152 Backlight 0 "0%" 1 "5%" 2 "10%" 3 "15%" 4 "20%" 5 "25%" 6 "30%" 7 "35%" 8 "40%" 9 "45%" 10 "50%" 11 "55%" 12 "60%" 13 "65%" 14 "70%" 15 "75%" 16 "80%" 17 "85%" 18 "90%" 19 "95%" 20 "100%" ;
VAL_ 2582577152 Industry_Code 0 "Global" 1 "Highway" 2 "Agriculture" 3 "Construction" 4 "Marine Industry" 5 "Industrial" ;
VAL_ 2582577152 Mode 0 "Day" 1 "Night" 13 "Color" ;
VAL_ 2582577152 Backlight 0 "0%" 1 "5%" 2 "10%" 3 "15%" 4 "20%" 5 "25%" 6 "30%" 7 "35%" 8 "40%" 9 "45%" 10 "50%" 11 "55%" 12 "60%" 13 "65%" 14 "70%" 15 "75%" 16 "80%" 17 "85%" 18 "90%" 19 "95%" 20 "100%" ;
VAL_ 2582577152 Industry_Code 0 "Global" 1 "Highway" 2 "Agriculture" 3 "Construction" 4 "Marine Industry" 5 "Industrial" ;
VAL_ 2582577152 Industry_Code 0 "Global" 1 "Highway" 2 "Agriculture" 3 "Construction" 4 "Marine Industry" 5 "Industrial" ;
VAL_ 2582577152 Product_code 434 "SSC200" 1047 "SMS100" 1151 "MBB200C" 1534 "DST110" 1776 "GPS100" 2606 "CLM100" 2686 "SSC300" 2781 "TLA100" 3373 "GPS200" 3563 "DST100" 3637 "FFM100" 3979 "NBE100" 4018 "RAA100" 4078 "RIM100" 4319 "J2K100" 8165 "ALM100" 9339 "IPG100" 9375 "DCM100" 9845 "EMS100" 12337 "CLMD16" 16434 "DSM250" 20067 "TMP100" 20298 "DSM150" 21703 "FPM100" 22585 "DCR100" 23603 "SIM100" 26493 "ACM100" 27244 "MBB300C" 28077 "MConnect" ;
VAL_ 2582577152 Software_code 1 "Version 1" ;
VAL_ 2582577152 Command 80 "Deviation calibration" ;
VAL_ 2582577152 Status 1 "Started" 2 "Completed successfully" 3 "Failed to complete" 4 "Turning too fast" 5 "Turning too slow" 6 "Invalid movement" ;
VAL_ 2582577152 Industry_Code 0 "Global" 1 "Highway" 2 "Agriculture" 3 "Construction" 4 "Marine Industry" 5 "Industrial" ;
VAL_ 2582577152 Product_code 434 "SSC200" 1047 "SMS100" 1151 "MBB200C" 1534 "DST110" 1776 "GPS100" 2606 "CLM100" 2686 "SSC300" 2781 "TLA100" 3373 "GPS200" 3563 "DST100" 3637 "FFM100" 3979 "NBE100" 4018 "RAA100" 4078 "RIM100" 4319 "J2K100" 8165 "ALM100" 9339 "IPG100" 9375 "DCM100" 9845 "EMS100" 12337 "CLMD16" 16434 "DSM250" 20067 "TMP100" 20298 "DSM150" 21703 "FPM100" 22585 "DCR100" 23603 "SIM100" 26493 "ACM100" 27244 "MBB300C" 28077 "MConnect" ;
VAL_ 2582577152 Opcode 0 "Read All" 1 "Write Register" 2 "Read Config" 3 "Write Config" 4 "Calibrate" 5 "Clear Calibration" 6 "Status" 7 "Clear Status" 8 "Reset Factory Default" 9 "Debug" 16 "Write Instance" 17 "Read Instance" 32 "Write Label" 33 "Read Label" 48 "Write Switch Config" 49 "Read Switch Config" 64 "Write Alert Config" 65 "Read Alert Config" 80 "Write Channel Config" 81 "Read Channel Config" 86 "Read Channel Config Extended" 87 "Write Channel Config Extended" ;
VAL_ 2582577152 Industry_Code 0 "Global" 1 "Highway" 2 "Agriculture" 3 "Construction" 4 "Marine Industry" 5 "Industrial" ;
VAL_ 2582577152 Proprietary_ID 108 "Pilot Configuration" 140 "Display" 240 "Seatalk 1 Encoded" ;
VAL_ 2582577152 command 2 "Rudder Limit" 3 "Rudder Damping" 4 "Rudder Offset" 6 "Reverse Rudder Reference" 8 "Cruise Speed" 11 "Power Steer Mode" 12 "Settings" 15 "Wind Type" 17 "Auto Turn" 18 "Calibration Lock" 20 "Gybe Inhibit" 21 "Compass Offset" 22 "Hull Type" 23 "Drive Type" 25 "Response Level" 26 "Max Compass Deviation" 27 "Hard Over Time" 29 "Debug Level" 33 "Compass Lock" 34 "Speed Input" 35 "Compass Linearisation Progress" 36 "ACU Debug Level" 37 "Wind Shift Alarm" 38 "Auto Turn" 39 "Auto Turn Timeout" 129 "Seatalk1" ;
VAL_ 2582577152 Seatalk1_Command 0 "Depth Below Transducer" 1 "Equipment ID" 5 "Engine RPM and PITCH" 16 "Apparent Wind Angle" 17 "Apparent Wind Speed" 32 "Speed through water" 33 "Trip Mileage" 34 "Total Mileage" 35 "Water temperature (ST50)" 36 "Display units for Mileage & Speed" 37 "Total & Trip Log" 38 "Speed through water (with average)" 39 "Water temperature" 48 "Set lamp Intensity" 54 "Cancel MOB (Man Over Board) condition" 56 "Codelock data" 80 "LAT position" 81 "LON position" 82 "Speed over Ground" 83 "Course over Ground (COG)" 84 "GMT-time" 85 "TRACK keystroke on GPS unit" 86 "Date" 87 "Sat Info" 88 "LAT/LON (raw unfiltered)" 89 "Set Count Down Timer" 97 "Issued by E-80 multifunction display at initialization" 101 "Select Fathom display units for depth display" 102 "Wind alarm" 104 "Alarm acknowledgment keystroke" 108 "Second equipment-ID datagram" 110 "MOB (Man Over Board)" 112 "Keystroke on Raymarine A25006 ST60 Maxiview Remote Control" 128 "Set Lamp Intensity" 129 "Sent by course computer during setup" 130 "Target waypoint name" 131 "Sent by course computer" 132 "Compass heading Autopilot course and Rudder position" 133 "Navigation to waypoint information" 134 "Keystroke" 135 "Set Response level" 136 "Autopilot Parameter" 137 "Compass heading sent by ST40 compass instrument" 144 "Device Identification" 145 "Set Rudder gain" 146 "Set Autopilot Parameter" 147 "Enter AP-Setup" 149 "Replaces command 84 while autopilot is in value setting mode" 153 "Compass variation" 154 "Version String" 156 "Compass heading and Rudder position" 158 "Waypoint definition" 161 "Destination Waypoint Info" 162 "Arrival Info" 164 "Broadcast query/response to identify devices" 165 "GPS and DGPS Info" 167 "Unknown meaning" 168 "Alarm ON/OFF for Guard" 171 "Alarm ON/OFF for Guard" ;
VAL_ 2582577152 device 3 "S100" 5 "Course Computer" ;
VAL_ 2582577152 Industry_Code 0 "Global" 1 "Highway" 2 "Agriculture" 3 "Construction" 4 "Marine Industry" 5 "Industrial" ;
VAL_ 2582577152 Proprietary_ID 108 "Pilot Configuration" 140 "Display" 240 "Seatalk 1 Encoded" ;
VAL_ 2582577152 command1 2 "Rudder Limit" 3 "Rudder Damping" 4 "Rudder Offset" 6 "Reverse Rudder Reference" 8 "Cruise Speed" 11 "Power Steer Mode" 12 "Settings" 15 "Wind Type" 17 "Auto Turn" 18 "Calibration Lock" 20 "Gybe Inhibit" 21 "Compass Offset" 22 "Hull Type" 23 "Drive Type" 25 "Response Level" 26 "Max Compass Deviation" 27 "Hard Over Time" 29 "Debug Level" 33 "Compass Lock" 34 "Speed Input" 35 "Compass Linearisation Progress" 36 "ACU Debug Level" 37 "Wind Shift Alarm" 38 "Auto Turn" 39 "Auto Turn Timeout" 129 "Seatalk1" ;
VAL_ 2582577152 Group 0 "None" 1 "Helm 1" 2 "Helm 2" 3 "Cockpit" 4 "Flybridge" 5 "Mast" 6 "Group 1" 7 "Group 2" 8 "Group 3" 9 "Group 4" 10 "Group 5" ;
VAL_ 2582577152 Shared 1 "Shared" 2 "Not Shared" ;
VAL_ 2582577152 Industry_Code 0 "Global" 1 "Highway" 2 "Agriculture" 3 "Construction" 4 "Marine Industry" 5 "Industrial" ;
VAL_ 2582577152 Proprietary_ID 108 "Pilot Configuration" 140 "Display" 240 "Seatalk 1 Encoded" ;
VAL_ 2582577152 command1 2 "Rudder Limit" 3 "Rudder Damping" 4 "Rudder Offset" 6 "Reverse Rudder Reference" 8 "Cruise Speed" 11 "Power Steer Mode" 12 "Settings" 15 "Wind Type" 17 "Auto Turn" 18 "Calibration Lock" 20 "Gybe Inhibit" 21 "Compass Offset" 22 "Hull Type" 23 "Drive Type" 25 "Response Level" 26 "Max Compass Deviation" 27 "Hard Over Time" 29 "Debug Level" 33 "Compass Lock" 34 "Speed Input" 35 "Compass Linearisation Progress" 36 "ACU Debug Level" 37 "Wind Shift Alarm" 38 "Auto Turn" 39 "Auto Turn Timeout" 129 "Seatalk1" ;
VAL_ 2582577152 Group 0 "None" 1 "Helm 1" 2 "Helm 2" 3 "Cockpit" 4 "Flybridge" 5 "Mast" 6 "Group 1" 7 "Group 2" 8 "Group 3" 9 "Group 4" 10 "Group 5" ;
VAL_ 2582577152 Color 0 "Day 1" 2 "Day 2" 3 "Red/Black" 4 "Inverse" ;
VAL_ 2582577152 Industry_Code 0 "Global" 1 "Highway" 2 "Agriculture" 3 "Construction" 4 "Marine Industry" 5 "Industrial" ;
VAL_ 2582577152 Proprietary_ID 108 "Pilot Configuration" 140 "Display" 240 "Seatalk 1 Encoded" ;
VAL_ 2582577152 command 2 "Rudder Limit" 3 "Rudder Damping" 4 "Rudder Offset" 6 "Reverse Rudder Reference" 8 "Cruise Speed" 11 "Power Steer Mode" 12 "Settings" 15 "Wind Type" 17 "Auto Turn" 18 "Calibration Lock" 20 "Gybe Inhibit" 21 "Compass Offset" 22 "Hull Type" 23 "Drive Type" 25 "Response Level" 26 "Max Compass Deviation" 27 "Hard Over Time" 29 "Debug Level" 33 "Compass Lock" 34 "Speed Input" 35 "Compass Linearisation Progress" 36 "ACU Debug Level" 37 "Wind Shift Alarm" 38 "Auto Turn" 39 "Auto Turn Timeout" 129 "Seatalk1" ;
VAL_ 2582577152 Seatalk1_Command 0 "Depth Below Transducer" 1 "Equipment ID" 5 "Engine RPM and PITCH" 16 "Apparent Wind Angle" 17 "Apparent Wind Speed" 32 "Speed through water" 33 "Trip Mileage" 34 "Total Mileage" 35 "Water temperature (ST50)" 36 "Display units for Mileage & Speed" 37 "Total & Trip Log" 38 "Speed through water (with average)" 39 "Water temperature" 48 "Set lamp Intensity" 54 "Cancel MOB (Man Over Board) condition" 56 "Codelock data" 80 "LAT position" 81 "LON position" 82 "Speed over Ground" 83 "Course over Ground (COG)" 84 "GMT-time" 85 "TRACK keystroke on GPS unit" 86 "Date" 87 "Sat Info" 88 "LAT/LON (raw unfiltered)" 89 "Set Count Down Timer" 97 "Issued by E-80 multifunction display at initialization" 101 "Select Fathom display units for depth display" 102 "Wind alarm" 104 "Alarm acknowledgment keystroke" 108 "Second equipment-ID datagram" 110 "MOB (Man Over Board)" 112 "Keystroke on Raymarine A25006 ST60 Maxiview Remote Control" 128 "Set Lamp Intensity" 129 "Sent by course computer during setup" 130 "Target waypoint name" 131 "Sent by course computer" 132 "Compass heading Autopilot course and Rudder position" 133 "Navigation to waypoint information" 134 "Keystroke" 135 "Set Response level" 136 "Autopilot Parameter" 137 "Compass heading sent by ST40 compass instrument" 144 "Device Identification" 145 "Set Rudder gain" 146 "Set Autopilot Parameter" 147 "Enter AP-Setup" 149 "Replaces command 84 while autopilot is in value setting mode" 153 "Compass variation" 154 "Version String" 156 "Compass heading and Rudder position" 158 "Waypoint definition" 161 "Destination Waypoint Info" 162 "Arrival Info" 164 "Broadcast query/response to identify devices" 165 "GPS and DGPS Info" 167 "Unknown meaning" 168 "Alarm ON/OFF for Guard" 171 "Alarm ON/OFF for Guard" ;
VAL_ 2582577152 key 1 "Auto" 2 "Standby" 3 "Wind" 5 "-1" 6 "-10" 7 "+1" 8 "+10" 33 "-1 and -10" 34 "+1 and +10" 35 "Track" ;
VAL_ 2582577152 Industry_Code 0 "Global" 1 "Highway" 2 "Agriculture" 3 "Construction" 4 "Marine Industry" 5 "Industrial" ;
VAL_ 2582577152 Proprietary_ID 108 "Pilot Configuration" 140 "Display" 240 "Seatalk 1 Encoded" ;
VAL_ 2582577152 command 2 "Rudder Limit" 3 "Rudder Damping" 4 "Rudder Offset" 6 "Reverse Rudder Reference" 8 "Cruise Speed" 11 "Power Steer Mode" 12 "Settings" 15 "Wind Type" 17 "Auto Turn" 18 "Calibration Lock" 20 "Gybe Inhibit" 21 "Compass Offset" 22 "Hull Type" 23 "Drive Type" 25 "Response Level" 26 "Max Compass Deviation" 27 "Hard Over Time" 29 "Debug Level" 33 "Compass Lock" 34 "Speed Input" 35 "Compass Linearisation Progress" 36 "ACU Debug Level" 37 "Wind Shift Alarm" 38 "Auto Turn" 39 "Auto Turn Timeout" 129 "Seatalk1" ;
VAL_ 2582577152 Hull_Type 0 "Sail" 1 "Sail (slow turn)" 2 "Sail Catamaran" 3 "Power (slow turn)" 4 "Power (fast turn)" 8 "Power" ;
VAL_ 2582577152 Industry_Code 0 "Global" 1 "Highway" 2 "Agriculture" 3 "Construction" 4 "Marine Industry" 5 "Industrial" ;
VAL_ 2582577152 Proprietary_ID 108 "Pilot Configuration" 140 "Display" 240 "Seatalk 1 Encoded" ;
VAL_ 2582577152 command 2 "Rudder Limit" 3 "Rudder Damping" 4 "Rudder Offset" 6 "Reverse Rudder Reference" 8 "Cruise Speed" 11 "Power Steer Mode" 12 "Settings" 15 "Wind Type" 17 "Auto Turn" 18 "Calibration Lock" 20 "Gybe Inhibit" 21 "Compass Offset" 22 "Hull Type" 23 "Drive Type" 25 "Response Level" 26 "Max Compass Deviation" 27 "Hard Over Time" 29 "Debug Level" 33 "Compass Lock" 34 "Speed Input" 35 "Compass Linearisation Progress" 36 "ACU Debug Level" 37 "Wind Shift Alarm" 38 "Auto Turn" 39 "Auto Turn Timeout" 129 "Seatalk1" ;
VAL_ 2582577152 Seatalk1_Command 0 "Depth Below Transducer" 1 "Equipment ID" 5 "Engine RPM and PITCH" 16 "Apparent Wind Angle" 17 "Apparent Wind Speed" 32 "Speed through water" 33 "Trip Mileage" 34 "Total Mileage" 35 "Water temperature (ST50)" 36 "Display units for Mileage & Speed" 37 "Total & Trip Log" 38 "Speed through water (with average)" 39 "Water temperature" 48 "Set lamp Intensity" 54 "Cancel MOB (Man Over Board) condition" 56 "Codelock data" 80 "LAT position" 81 "LON position" 82 "Speed over Ground" 83 "Course over Ground (COG)" 84 "GMT-time" 85 "TRACK keystroke on GPS unit" 86 "Date" 87 "Sat Info" 88 "LAT/LON (raw unfiltered)" 89 "Set Count Down Timer" 97 "Issued by E-80 multifunction display at initialization" 101 "Select Fathom display units for depth display" 102 "Wind alarm" 104 "Alarm acknowledgment keystroke" 108 "Second equipment-ID datagram" 110 "MOB (Man Over Board)" 112 "Keystroke on Raymarine A25006 ST60 Maxiview Remote Control" 128 "Set Lamp Intensity" 129 "Sent by course computer during setup" 130 "Target waypoint name" 131 "Sent by course computer" 132 "Compass heading Autopilot course and Rudder position" 133 "Navigation to waypoint information" 134 "Keystroke" 135 "Set Response level" 136 "Autopilot Parameter" 137 "Compass heading sent by ST40 compass instrument" 144 "Device Identification" 145 "Set Rudder gain" 146 "Set Autopilot Parameter" 147 "Enter AP-Setup" 149 "Replaces command 84 while autopilot is in value setting mode" 153 "Compass variation" 154 "Version String" 156 "Compass heading and Rudder position" 158 "Waypoint definition" 161 "Destination Waypoint Info" 162 "Arrival Info" 164 "Broadcast query/response to identify devices" 165 "GPS and DGPS Info" 167 "Unknown meaning" 168 "Alarm ON/OFF for Guard" 171 "Alarm ON/OFF for Guard" ;
VAL_ 2582577152 Pilot_Mode 64 "Standby" 66 "Auto" 70 "Wind" 74 "Track" ;
VAL_ 2582577152 Industry_Code 0 "Global" 1 "Highway" 2 "Agriculture" 3 "Construction" 4 "Marine Industry" 5 "Industrial" ;
VAL_ 2582577152 Proprietary_ID 108 "Pilot Configuration" 140 "Display" 240 "Seatalk 1 Encoded" ;
VAL_ 2582577152 command 2 "Rudder Limit" 3 "Rudder Damping" 4 "Rudder Offset" 6 "Reverse Rudder Reference" 8 "Cruise Speed" 11 "Power Steer Mode" 12 "Settings" 15 "Wind Type" 17 "Auto Turn" 18 "Calibration Lock" 20 "Gybe Inhibit" 21 "Compass Offset" 22 "Hull Type" 23 "Drive Type" 25 "Response Level" 26 "Max Compass Deviation" 27 "Hard Over Time" 29 "Debug Level" 33 "Compass Lock" 34 "Speed Input" 35 "Compass Linearisation Progress" 36 "ACU Debug Level" 37 "Wind Shift Alarm" 38 "Auto Turn" 39 "Auto Turn Timeout" 129 "Seatalk1" ;
VAL_ 2582577152 Enabled 0 "No" 1 "Yes" ;
VAL_ 2582577152 Unknown_2 0 "No" 1 "Yes" ;
VAL_ 2582644480 Alert_Type 1 "Emergency Alarm" 2 "Alarm" 5 "Warning" 8 "Caution" ;
VAL_ 2582644480 Alert_Category 0 "Navigational" 1 "Technical" ;
VAL_ 2582644480 Temporary_Silence_Status 0 "No" 1 "Yes" ;
VAL_ 2582644480 Acknowledge_Status 0 "No" 1 "Yes" ;
VAL_ 2582644480 Escalation_Status 0 "No" 1 "Yes" ;
VAL_ 2582644480 Temporary_Silence_Support 0 "No" 1 "Yes" ;
VAL_ 2582644480 Acknowledge_Support 0 "No" 1 "Yes" ;
VAL_ 2582644480 Escalation_Support 0 "No" 1 "Yes" ;
VAL_ 2582644480 Trigger_Condition 0 "Manual" 1 "Auto" 2 "Test" 3 "Disabled" ;
VAL_ 2582644480 Threshold_Status 0 "Normal" 1 "Threshold Exceeded" 2 "Extreme Threshold Exceeded" 3 "Low Threshold Exceeded" 4 "Acknowledged" 5 "Awaiting Acknowledge" ;
VAL_ 2582644480 Alert_State 0 "Disabled" 1 "Normal" 2 "Active" 3 "Silenced" 4 "Acknowledged" 5 "Awaiting Acknowledge" ;
VAL_ 2582644736 Alert_Type 1 "Emergency Alarm" 2 "Alarm" 5 "Warning" 8 "Caution" ;
VAL_ 2582644736 Alert_Category 0 "Navigational" 1 "Technical" ;
VAL_ 2582644736 Response_Command 0 "Acknowledge" 1 "Temporary Silence" 2 "Test Command off" 3 "Test Command on" ;
VAL_ 2582644992 Alert_Type 1 "Emergency Alarm" 2 "Alarm" 5 "Warning" 8 "Caution" ;
VAL_ 2582644992 Alert_Category 0 "Navigational" 1 "Technical" ;
VAL_ 2582644992 Language_ID 0 "English (US)" 1 "English (UK)" 2 "Arabic" 3 "Chinese (simplified)" 4 "Croatian" 5 "Danish" 6 "Dutch" 7 "Finnish" 8 "French" 9 "German" 10 "Greek" 11 "Italian" 12 "Japanese" 13 "Korean" 14 "Norwegian" 15 "Polish" 16 "Portuguese" 17 "Russian" 18 "Spanish" 19 "Swedish" ;
VAL_ 2582645248 Alert_Type 1 "Emergency Alarm" 2 "Alarm" 5 "Warning" 8 "Caution" ;
VAL_ 2582645248 Alert_Category 0 "Navigational" 1 "Technical" ;

CM_ SG_ 2582644992 Alert_Text_Description "STRING field: decode bytes as ASCII (0x00/@/0xFF = terminator); canboat type: STRING_LAU";
CM_ SG_ 2582644992 Alert_Location_Text_Description "STRING field: decode bytes as ASCII (0x00/@/0xFF = terminator); canboat type: STRING_LAU";

BA_DEF_ BO_ "GenMsgCycleTime" INT 0 60000;
BA_DEF_ BO_ "ProtocolType" STRING;

BA_DEF_ BO_ "J1939PGN" INT 0 262143;
BA_ "J1939PGN" BO_ 2649686016 126720;
BA_ "J1939PGN" BO_ 2649686016 126720;
BA_ "J1939PGN" BO_ 2649686016 126720;
BA_ "J1939PGN" BO_ 2649686016 126720;
BA_ "J1939PGN" BO_ 2649686016 126720;
BA_ "J1939PGN" BO_ 2649686016 126720;
BA_ "J1939PGN" BO_ 2649686016 126720;
BA_ "J1939PGN" BO_ 2649686016 126720;
BA_ "J1939PGN" BO_ 2649686016 126720;
BA_ "J1939PGN" BO_ 2649686016 126720;
BA_ "J1939PGN" BO_ 2649686016 126720;
BA_ "J1939PGN" BO_ 2649686016 126720;
BA_ "J1939PGN" BO_ 2649686016 126720;
BA_ "J1939PGN" BO_ 2582642688 126976;
BA_ "J1939PGN" BO_ 2582644480 126983;
BA_ "J1939PGN" BO_ 2582644736 126984;
BA_ "J1939PGN" BO_ 2582644992 126985;
BA_ "J1939PGN" BO_ 2582645248 126986;
